VERSION "HINBNNNYNNNNNNNNNNNNNNNNNNNNNNNNNNNYYNNNNN/4>%%%/4/'%**4NNN///"

NS_ :

BS_:

BU_: Traffic Tester CGW ADU

BO_ 597 HMI_Request_ADU_CatS1: 32 ADU
 SG_ HMI_Request_ADU_CatS1_MACTx : 227|28@0+ (1,0) [0|268435455] ""  CGW
 SG_ HMI_Request_ADU_CatS1_FVTx : 231|4@0+ (1,0) [0|15] ""  CGW
 SG_ HMI_Request_ADU_CatS1_No_Cs : 223|8@0+ (1,0) [0|255] ""  CGW
 SG_ HMI_Request_ADU_CatS1_No_Cnt : 211|4@0+ (1,0) [0|15] ""  CGW
 SG_ HMI_Status_TSROffMute_Rq : 154|2@0+ (1,0) [0|0] ""  CGW
 SG_ HMI_Status_CBDA5_Rq : 155|1@0+ (1,0) [0|0] ""  CGW
 SG_ HMI_Status_CBDA4_Rq : 156|1@0+ (1,0) [0|0] ""  CGW
 SG_ HMI_Status_BSM6_Rq : 157|1@0+ (1,0) [0|0] ""  CGW
 SG_ HMI_Status_BSM5_Rq : 158|1@0+ (1,0) [0|0] ""  CGW
 SG_ HMI_Status_DAS2_Rq : 145|3@0+ (1,0) [0|0] ""  CGW
 SG_ HMI_Status_DAS1_Rq : 149|4@0+ (1,0) [0|0] ""  CGW
 SG_ HMI_Status_TSR3_Rq : 150|1@0+ (1,0) [0|0] ""  CGW
 SG_ HMI_Status_TSR2_Rq : 151|1@0+ (1,0) [0|0] ""  CGW
 SG_ HMI_Status_TSR1_Rq : 138|3@0+ (1,0) [0|0] ""  CGW
 SG_ HMI_Status_LKA10_Rq : 139|1@0+ (1,0) [0|0] ""  CGW
 SG_ HMI_Status_LKA9_Rq : 142|3@0+ (1,0) [0|0] ""  CGW
 SG_ HMI_Status_LKA8_Rq : 143|1@0+ (1,0) [0|0] ""  CGW
 SG_ HMI_Status_LKA7_Rq : 128|1@0+ (1,0) [0|0] ""  CGW
 SG_ HMI_Status_LKA6_Rq : 129|1@0+ (1,0) [0|0] ""  CGW
 SG_ HMI_Status_LKA5_Rq : 130|1@0+ (1,0) [0|0] ""  CGW
 SG_ HMI_Status_LKA4_Rq : 131|1@0+ (1,0) [0|0] ""  CGW
 SG_ HMI_Status_LKA3_Rq : 132|1@0+ (1,0) [0|0] ""  CGW
 SG_ HMI_Status_LKA2_Rq : 133|1@0+ (1,0) [0|0] ""  CGW
 SG_ HMI_Status_LKA1_Rq : 135|2@0+ (1,0) [0|0] ""  CGW
 SG_ HMI_Status_ACCASCISA2_Rq : 120|1@0+ (1,0) [0|0] ""  CGW
 SG_ HMI_Status_ACCASCISA1_Rq : 121|1@0+ (1,0) [0|0] ""  CGW
 SG_ HMI_Status_ACCASCISA_OVSP_Rq : 123|2@0+ (1,0) [0|0] ""  CGW
 SG_ HMI_Status_ISA2_Rq : 124|1@0+ (1,0) [0|0] ""  CGW
 SG_ HMI_Status_ISA1_Rq : 126|2@0+ (1,0) [0|0] ""  CGW
 SG_ HMI_Status_ACCASC4_Rq : 127|1@0+ (1,0) [0|0] ""  CGW
 SG_ HMI_Status_ACCASC3_Rq : 112|1@0+ (1,0) [0|0] ""  CGW
 SG_ HMI_Status_ACCASC2_Rq : 113|1@0+ (1,0) [0|0] ""  CGW
 SG_ HMI_Status_ACCASC1_Rq : 114|1@0+ (1,0) [0|0] ""  CGW
 SG_ HMI_Status_ASC3_Rq : 115|1@0+ (1,0) [0|0] ""  CGW
 SG_ HMI_Status_ASC2_Rq : 116|1@0+ (1,0) [0|0] ""  CGW
 SG_ HMI_Status_ASC1_Rq : 118|2@0+ (1,0) [0|0] ""  CGW
 SG_ HMI_Status_DAS3_Rq : 105|3@0+ (1,0) [0|0] ""  CGW
 SG_ HMI_Status_ACC12_Rq : 106|1@0+ (1,0) [0|0] ""  CGW
 SG_ HMI_Status_ACC11_Rq : 107|1@0+ (1,0) [0|0] ""  CGW
 SG_ HMI_Status_ACC10_Rq : 108|1@0+ (1,0) [0|0] ""  CGW
 SG_ HMI_Status_ACC9_Rq : 109|1@0+ (1,0) [0|0] ""  CGW
 SG_ HMI_Status_ACC8_Rq : 97|4@0+ (1,0) [0|0] ""  CGW
 SG_ HMI_Status_ACC7_Rq : 100|3@0+ (1,0) [0|0] ""  CGW
 SG_ HMI_Status_ACC6_Rq : 102|2@0+ (1,0) [0|0] ""  CGW
 SG_ HMI_Status_ACC5_Rq : 103|1@0+ (1,0) [0|0] ""  CGW
 SG_ HMI_Status_ACC4_Rq : 89|2@0+ (1,0) [0|0] ""  CGW
 SG_ HMI_Status_ACC3_Rq : 90|1@0+ (1,0) [0|0] ""  CGW
 SG_ HMI_Status_ACC2_Rq : 91|1@0+ (1,0) [0|0] ""  CGW
 SG_ HMI_Status_ACC1_Rq : 94|3@0+ (1,0) [0|0] ""  CGW
 SG_ HMI_Status_RCTA2_Rq : 95|1@0+ (1,0) [0|0] ""  CGW
 SG_ HMI_Status_RCTA1_Rq : 80|1@0+ (1,0) [0|0] ""  CGW
 SG_ HMI_Status_RPTB2_Rq : 81|1@0+ (1,0) [0|0] ""  CGW
 SG_ HMI_Status_RCTB1_Rq : 83|2@0+ (1,0) [0|0] ""  CGW
 SG_ HMI_Status_RPTC2_Rq : 84|1@0+ (1,0) [0|0] ""  CGW
 SG_ HMI_Status_RPTC1_Rq : 86|2@0+ (1,0) [0|0] ""  CGW
 SG_ HMI_Status_PAEB2_Rq : 87|1@0+ (1,0) [0|0] ""  CGW
 SG_ HMI_Status_PAEB1_Rq : 74|3@0+ (1,0) [0|0] ""  CGW
 SG_ HMI_Status_OCP8_Rq : 76|2@0+ (1,0) [0|0] ""  CGW
 SG_ HMI_Status_OCP7_Rq : 78|2@0+ (1,0) [0|0] ""  CGW
 SG_ HMI_Status_OCP6_Rq : 64|2@0+ (1,0) [0|0] ""  CGW
 SG_ HMI_Status_OCP5_Rq : 66|2@0+ (1,0) [0|0] ""  CGW
 SG_ HMI_Status_OCP4_Rq : 67|1@0+ (1,0) [0|0] ""  CGW
 SG_ HMI_Status_OCP3_Rq : 69|2@0+ (1,0) [0|0] ""  CGW
 SG_ HMI_Status_OCP2_Rq : 70|1@0+ (1,0) [0|0] ""  CGW
 SG_ HMI_Status_OCP1_Rq : 71|1@0+ (1,0) [0|0] ""  CGW
 SG_ HMI_Status_CBDA3_Rq : 57|2@0+ (1,0) [0|0] ""  CGW
 SG_ HMI_Status_CBDA2_Rq : 59|2@0+ (1,0) [0|0] ""  CGW
 SG_ HMI_Status_CBDA1_Rq : 60|1@0+ (1,0) [0|0] ""  CGW
 SG_ HMI_Status_BSM4_Rq : 62|2@0+ (1,0) [0|0] ""  CGW
 SG_ HMI_Status_BSM3_Rq : 48|2@0+ (1,0) [0|0] ""  CGW
 SG_ HMI_Status_BSM2_Rq : 49|1@0+ (1,0) [0|0] ""  CGW
 SG_ HMI_Status_BSM1_Rq : 50|1@0+ (1,0) [0|0] ""  CGW
 SG_ HMI_Status_BSP8_Rq : 52|2@0+ (1,0) [0|0] ""  CGW
 SG_ HMI_Status_BSP7_Rq : 54|2@0+ (1,0) [0|0] ""  CGW
 SG_ HMI_Status_BSP6_Rq : 40|2@0+ (1,0) [0|0] ""  CGW
 SG_ HMI_Status_BSP5_Rq : 42|2@0+ (1,0) [0|0] ""  CGW
 SG_ HMI_Status_BSP4_Rq : 43|1@0+ (1,0) [0|0] ""  CGW
 SG_ HMI_Status_BSP3_Rq : 45|2@0+ (1,0) [0|0] ""  CGW
 SG_ HMI_Status_BSP2_Rq : 46|1@0+ (1,0) [0|0] ""  CGW
 SG_ HMI_Status_BSP1_Rq : 47|1@0+ (1,0) [0|0] ""  CGW
 SG_ HMI_Status_RDPRDW4_Rq : 32|1@0+ (1,0) [0|0] ""  CGW
 SG_ HMI_Status_RDPRDW3_Rq : 34|2@0+ (1,0) [0|0] ""  CGW
 SG_ HMI_Status_RDPRDW2_Rq : 35|1@0+ (1,0) [0|0] ""  CGW
 SG_ HMI_Status_RDPRDW1_Rq : 36|1@0+ (1,0) [0|0] ""  CGW
 SG_ HMI_Status_LDW5_Rq : 38|2@0+ (1,0) [0|0] ""  CGW
 SG_ HMI_Status_LDW4_Rq : 24|2@0+ (1,0) [0|0] ""  CGW
 SG_ HMI_Status_LDW3_Rq : 25|1@0+ (1,0) [0|0] ""  CGW
 SG_ HMI_Status_LDW2_Rq : 26|1@0+ (1,0) [0|0] ""  CGW
 SG_ HMI_Status_LDW1_Rq : 27|1@0+ (1,0) [0|0] ""  CGW
 SG_ HMI_Status_LDP4_Rq : 29|2@0+ (1,0) [0|0] ""  CGW
 SG_ HMI_Status_LDP3_Rq : 31|2@0+ (1,0) [0|0] ""  CGW
 SG_ HMI_Status_LDP2_Rq : 16|1@0+ (1,0) [0|0] ""  CGW
 SG_ HMI_Status_LDP1_Rq : 18|2@0+ (1,0) [0|0] ""  CGW
 SG_ HMI_Status_FCTA4_Rq : 20|2@0+ (1,0) [0|0] ""  CGW
 SG_ HMI_Status_FCTA3_Rq : 22|2@0+ (1,0) [0|0] ""  CGW
 SG_ HMI_Status_FCTA2_Rq : 23|1@0+ (1,0) [0|0] ""  CGW
 SG_ HMI_Status_FCTA1_Rq : 8|1@0+ (1,0) [0|0] ""  CGW
 SG_ HMI_Status_CTB5_Rq : 10|2@0+ (1,0) [0|0] ""  CGW
 SG_ HMI_Status_CTB4_Rq : 12|2@0+ (1,0) [0|0] ""  CGW
 SG_ HMI_Status_CTB3_Rq : 13|1@0+ (1,0) [0|0] ""  CGW
 SG_ HMI_Status_CTB2_Rq : 14|1@0+ (1,0) [0|0] ""  CGW
 SG_ HMI_Status_CTB1_Rq : 0|2@0+ (1,0) [0|0] ""  CGW
 SG_ HMI_Status_PTC2_Rq : 1|1@0+ (1,0) [0|0] ""  CGW
 SG_ HMI_Status_PTC1_Rq : 3|2@0+ (1,0) [0|0] ""  CGW
 SG_ HMI_Status_AEBFCW2_Rq : 4|1@0+ (1,0) [0|0] ""  CGW
 SG_ HMI_Status_AEBFCW1_Rq : 7|3@0+ (1,0) [0|0] ""  CGW

BO_ 593 MAZPCM01: 32 CGW
 SG_ ID41B_No_Cs : 255|8@0+ (1,0) [0|255] ""  ADU
 SG_ AMBDS_ST : 183|1@0+ (1,0) [0|0] ""  ADU
 SG_ AMBDS_VL : 168|1@0+ (1,0) [0|0] ""  ADU
 SG_ AMBDS : 160|8@0+ (0.5,-40) [-40|60] "degC"  ADU
 SG_ AMBTE_ST : 161|1@0+ (1,0) [0|0] ""  ADU
 SG_ AMBTE_VL : 162|1@0+ (1,0) [0|0] ""  ADU
 SG_ AMBTE : 154|8@0+ (0.5,-40) [-40|60] "degC"  ADU
 SG_ RDYIND : 155|1@0+ (1,0) [0|1] ""  ADU
 SG_ GEAR_MET : 143|4@0+ (1,0) [0|0] ""  ADU
 SG_ THF : 132|1@0+ (1,0) [0|0] ""  ADU
 SG_ B_ISPTM : 135|3@0+ (1,0) [0|7] ""  ADU
 SG_ IGP_PT2 : 80|1@0+ (1,0) [0|0] ""  ADU
 SG_ B_B : 79|1@0+ (1,0) [0|0] ""  ADU
 SG_ B_LO : 64|1@0+ (1,0) [0|0] ""  ADU
 SG_ B_2 : 65|1@0+ (1,0) [0|0] ""  ADU
 SG_ B_3 : 66|1@0+ (1,0) [0|0] ""  ADU
 SG_ B_4 : 67|1@0+ (1,0) [0|0] ""  ADU
 SG_ B_D : 68|1@0+ (1,0) [0|0] ""  ADU
 SG_ B_N : 69|1@0+ (1,0) [0|0] ""  ADU
 SG_ B_R : 70|1@0+ (1,0) [0|0] ""  ADU
 SG_ B_P : 71|1@0+ (1,0) [0|0] ""  ADU
 SG_ ID251_No_Cs : 63|8@0+ (1,0) [0|255] ""  ADU
 SG_ PDLF : 6|1@0+ (1,0) [0|0] ""  ADU
 SG_ EGF : 7|1@0+ (1,0) [0|0] ""  ADU

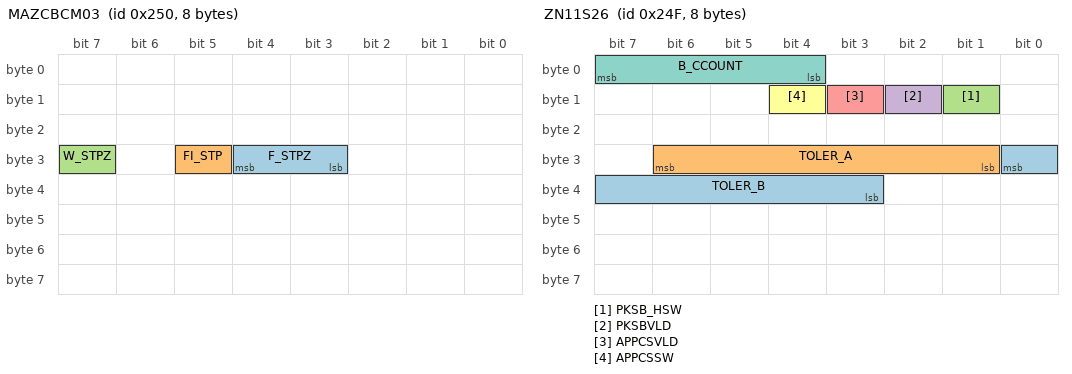
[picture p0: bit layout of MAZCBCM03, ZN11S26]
BO_ 592 MAZCBCM03: 8 CGW
 SG_ F_STPZ : 28|2@0+ (1,0) [0|3] ""  ADU
 SG_ FI_STP : 29|1@0+ (1,0) [0|1] ""  ADU
 SG_ W_STPZ : 31|1@0+ (1,0) [0|1] ""  ADU

BO_ 591 ZN11S26: 8 CGW
 SG_ TOLER_B : 24|6@0- (0.2,0) [-6.4|6.2] "km/h"  ADU
 SG_ TOLER_A : 30|6@0+ (0.002,0.94) [0.94|1.064] "Unitless"  ADU
 SG_ PKSB_HSW : 9|1@0+ (1,0) [0|0] ""  ADU
 SG_ PKSBVLD : 10|1@0+ (1,0) [0|0] ""  ADU
 SG_ APPCSVLD : 11|1@0+ (1,0) [0|0] ""  ADU
 SG_ APPCSSW : 12|1@0+ (1,0) [0|0] ""  ADU
 SG_ B_CCOUNT : 7|4@0+ (1,0) [0|15] ""  ADU

BO_ 590 MET1S44: 8 CGW
 SG_ KZK24E_MACTx : 35|28@0+ (1,0) [0|268435455] ""  ADU
 SG_ FV24E_FVTx : 39|4@0+ (1,0) [0|15] ""  ADU
 SG_ CCCOUNT : 27|4@0+ (1,0) [0|15] ""  ADU
 SG_ TSSMD2_M : 22|1@0+ (1,0) [0|0] ""  ADU
 SG_ TSSMD1_M : 23|1@0+ (1,0) [0|0] ""  ADU
 SG_ LTM_M : 8|1@0+ (1,0) [0|0] ""  ADU
 SG_ CANCEL_M : 9|1@0+ (1,0) [0|0] ""  ADU
 SG_ FLICK_PLUS_M : 10|1@0+ (1,0) [0|0] ""  ADU
 SG_ FLICK_MINUS_M : 11|1@0+ (1,0) [0|0] ""  ADU
 SG_ SET_PLUS_M : 12|1@0+ (1,0) [0|0] ""  ADU
 SG_ SET_MINUS_M : 13|1@0+ (1,0) [0|0] ""  ADU
 SG_ RES_M : 14|1@0+ (1,0) [0|0] ""  ADU
 SG_ TSSMD2 : 15|1@0+ (1,0) [0|0] ""  ADU
 SG_ TSSMD1 : 0|1@0+ (1,0) [0|0] ""  ADU
 SG_ LTM : 1|1@0+ (1,0) [0|0] ""  ADU
 SG_ CANCEL : 2|1@0+ (1,0) [0|0] ""  ADU
 SG_ FLICK_PLUS : 3|1@0+ (1,0) [0|0] ""  ADU
 SG_ FLICK_MINUS : 4|1@0+ (1,0) [0|0] ""  ADU
 SG_ SET_PLUS : 5|1@0+ (1,0) [0|0] ""  ADU
 SG_ SET_MINUS : 6|1@0+ (1,0) [0|0] ""  ADU
 SG_ RES : 7|1@0+ (1,0) [0|0] ""  ADU

BO_ 588 FCM1S78: 8 ADU
 SG_ OTHFRILL : 7|20@0+ (0.04,0) [0|41943] "cd/m^2"  CGW

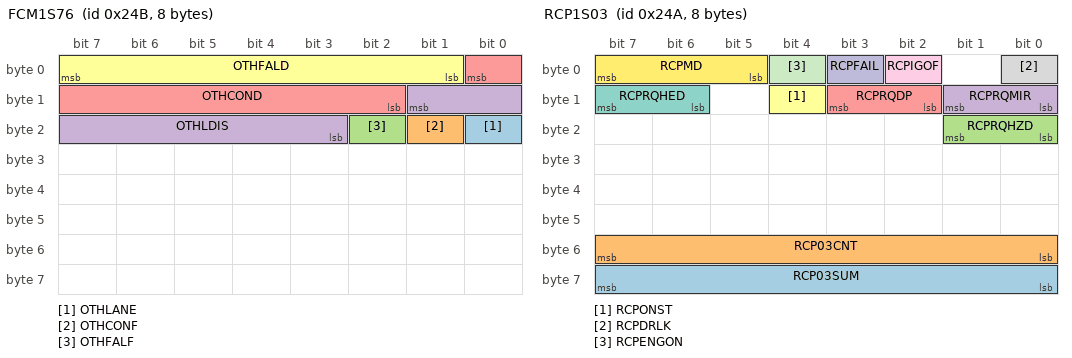
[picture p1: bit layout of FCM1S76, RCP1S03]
BO_ 587 FCM1S76: 8 ADU
 SG_ OTHLANE : 16|1@0+ (1,0) [0|1] ""  CGW
 SG_ OTHCONF : 17|1@0+ (1,0) [0|1] ""  CGW
 SG_ OTHFALF : 18|1@0+ (1,0) [0|1] ""  CGW
 SG_ OTHLDIS : 9|7@0+ (1,0) [0|127] "m"  CGW
 SG_ OTHCOND : 0|7@0+ (1,0) [0|127] "m"  CGW
 SG_ OTHFALD : 7|7@0+ (1,0) [0|127] "m"  CGW

BO_ 586 RCP1S03: 8 ADU
 SG_ RCP03SUM : 63|8@0+ (1,0) [0|255] ""  CGW
 SG_ RCP03CNT : 55|8@0+ (1,0) [0|255] "counter"  CGW
 SG_ RCPRQHZD : 17|2@0+ (1,0) [0|3] ""  CGW
 SG_ RCPRQMIR : 9|2@0+ (1,0) [0|3] ""  CGW
 SG_ RCPRQDP : 11|2@0+ (1,0) [0|3] ""  CGW
 SG_ RCPONST : 12|1@0+ (1,0) [0|1] ""  CGW
 SG_ RCPRQHED : 15|2@0+ (1,0) [0|3] ""  CGW
 SG_ RCPDRLK : 0|1@0+ (1,0) [0|1] ""  CGW
 SG_ RCPIGOF : 2|1@0+ (1,0) [0|1] ""  CGW
 SG_ RCPFAIL : 3|1@0+ (1,0) [0|1] ""  CGW
 SG_ RCPENGON : 4|1@0+ (1,0) [0|1] ""  CGW
 SG_ RCPMD : 7|3@0+ (1,0) [0|7] ""  CGW

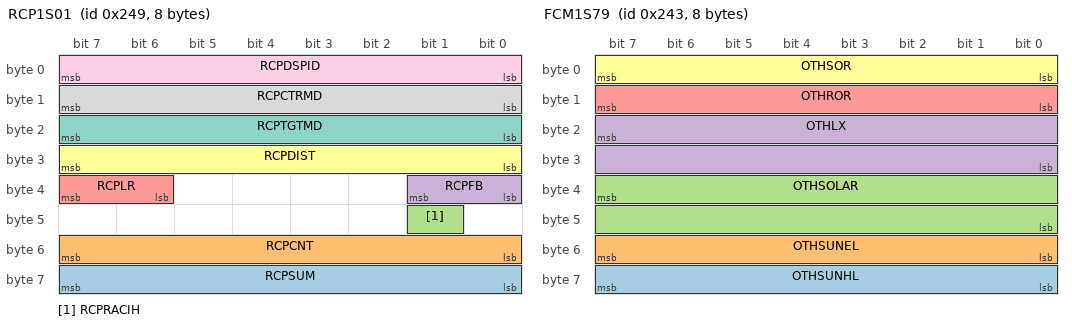
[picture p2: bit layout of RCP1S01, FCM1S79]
BO_ 585 RCP1S01: 8 ADU
 SG_ RCPSUM : 63|8@0+ (1,0) [0|255] ""  CGW
 SG_ RCPCNT : 55|8@0+ (1,0) [0|255] ""  CGW
 SG_ RCPRACIH : 41|1@0+ (1,0) [0|1] ""  CGW
 SG_ RCPFB : 33|2@0+ (1,0) [0|3] ""  CGW
 SG_ RCPLR : 39|2@0+ (1,0) [0|3] ""  CGW
 SG_ RCPDIST : 31|8@0+ (1,0) [0|255] "m"  CGW
 SG_ RCPTGTMD : 23|8@0+ (1,0) [0|255] ""  CGW
 SG_ RCPCTRMD : 15|8@0+ (1,0) [0|255] ""  CGW
 SG_ RCPDSPID : 7|8@0+ (1,0) [0|255] ""  CGW

BO_ 579 FCM1S79: 8 ADU
 SG_ OTHSUNHL : 63|8@0+ (1,0) [0|255] ""  CGW
 SG_ OTHSUNEL : 55|8@0+ (1,0) [0|255] ""  CGW
 SG_ OTHSOLAR : 39|16@0+ (1,0) [0|65535] ""  CGW
 SG_ OTHLX : 23|16@0+ (1,0) [0|65535] ""  CGW
 SG_ OTHROR : 15|8@0+ (1,0) [0|255] ""  CGW
 SG_ OTHSOR : 7|8@0+ (1,0) [0|255] ""  CGW

BO_ 552 TransGearData: 8 CGW
 SG_ ID228_No_Cs : 63|8@0+ (1,0) [0|255] "" Vector__XXX
 SG_ ID228_No_Cnt : 51|4@0+ (1,0) [0|15] "" Vector__XXX
 SG_ ShiftOpeWarning_D_Rq : 55|4@0+ (1,0) [0|0] "" Vector__XXX
 SG_ ShiftPos_D_Act : 43|4@0+ (1,0) [0|0] "" Vector__XXX
 SG_ TransmChangeLeverPosition : 47|4@0+ (1,0) [0|0] ""  ADU
 SG_ DispAtLvrPos_ArrowReq : 32|1@0+ (1,0) [0|0] "" Vector__XXX
 SG_ ShiftPos_D_Trg : 36|4@0+ (1,0) [0|0] "" Vector__XXX
 SG_ DispAtLvrPos_Off_Req : 37|1@0+ (1,0) [0|0] "" Vector__XXX
 SG_ AT_INDLvl_D_Rq : 39|2@0+ (1,0) [0|0] "" Vector__XXX
 SG_ AT_FailSafeLvl_D_Rq : 25|2@0+ (1,0) [0|0] "" Vector__XXX
 SG_ PwrDwn_D_Req_ByTCM : 27|2@0+ (1,0) [0|0] "" Vector__XXX
 SG_ SBW_INDLvl_D_Rq : 29|2@0+ (1,0) [0|0] "" Vector__XXX
 SG_ ParkLockWarning_D_Rq : 31|2@0+ (1,0) [0|0] "" Vector__XXX
 SG_ ShiftrPos_D_Qf : 17|2@0+ (1,0) [0|0] "" Vector__XXX
 SG_ SbwWarningLamp_B_Rq : 18|1@0+ (1,0) [0|0] "" Vector__XXX
 SG_ TransmParking_D_Act : 21|3@0+ (1,0) [0|0] "" Vector__XXX
 SG_ TrnSlaCtl_B_Rq : 22|1@0+ (1,0) [0|0] "" Vector__XXX
 SG_ TrnSlaCtlFlag : 23|1@0+ (1,0) [0|0] "" Vector__XXX
 SG_ TrnShifActv_B_Actl : 8|1@0+ (1,0) [0|0] "" Vector__XXX
 SG_ AT_OILTEMPHi_D_Rq : 10|2@0+ (1,0) [0|0] "" Vector__XXX
 SG_ TrnCnvtClu_D_Actl : 12|2@0+ (1,0) [0|0] "" Vector__XXX
 SG_ DispGearPos_FlashReq : 13|1@0+ (1,0) [0|0] "" Vector__XXX
 SG_ OD_Hold_Sport_Flash : 14|1@0+ (1,0) [0|0] "" Vector__XXX
 SG_ DispAtLvrPos_FlashReq : 15|1@0+ (1,0) [0|0] "" Vector__XXX
 SG_ DispAtLvrPos_D_Rq : 3|4@0+ (1,0) [0|0] "" Vector__XXX
 SG_ DispGearPos_D_Rq : 7|4@0+ (1,0) [0|0] "" Vector__XXX

BO_ 548 MAZDSC01: 32 CGW
 SG_ ID224_No_Cnt : 243|4@0+ (1,0) [0|15] ""  ADU
 SG_ SMVSCMZ01 : 62|8@0+ (1,0) [0|255] ""  ADU
 SG_ B_MCST : 48|2@0+ (1,0) [0|3] ""  ADU
 SG_ RJMALSSR : 49|1@0+ (1,0) [0|0] ""  ADU
 SG_ REJUFEXT : 50|1@0+ (1,0) [0|0] ""  ADU
 SG_ VXRLHDS : 51|1@0+ (1,0) [0|0] ""  ADU
 SG_ VXRRHDS : 52|1@0+ (1,0) [0|0] ""  ADU
 SG_ VXFLHDS : 53|1@0+ (1,0) [0|0] ""  ADU
 SG_ VXFRHDS : 54|1@0+ (1,0) [0|0] ""  ADU
 SG_ GVSPD : 38|16@0+ (0.01,0) [0|655.35] "km/h"  ADU
 SG_ SP1P : 28|6@0+ (1,0) [0|63] ""  ADU
 SG_ GVSPDINV : 29|1@0+ (1,0) [0|0] ""  ADU
 SG_ EPBDDACT : 30|1@0+ (1,0) [0|0] ""  ADU
 SG_ CWAACT : 17|1@0+ (1,0) [0|0] ""  ADU
 SG_ TRCOPE : 23|6@0+ (1,0) [0|63] ""  ADU
 SG_ MCBACT : 8|1@0+ (1,0) [0|0] ""  ADU
 SG_ VDMACT : 9|1@0+ (1,0) [0|0] ""  ADU
 SG_ ABSOPE : 14|5@0+ (1,0) [0|0] ""  ADU
 SG_ EPBF : 15|1@0+ (1,0) [0|0] ""  ADU
 SG_ APPSPCER : 1|2@0+ (1,0) [0|0] ""  ADU
 SG_ WSTP : 2|1@0+ (1,0) [0|0] ""  ADU
 SG_ FSTP : 3|1@0+ (1,0) [0|0] ""  ADU
 SG_ EPBSW : 5|2@0+ (1,0) [0|0] ""  ADU
 SG_ EPBLOCK : 7|2@0+ (1,0) [0|0] ""  ADU

BO_ 544 ABG1S09: 32 CGW
 SG_ SAB_ON : 153|2@0+ (1,0) [0|3] ""  ADU
 SG_ CSA_ON : 155|2@0+ (1,0) [0|3] ""  ADU
 SG_ FRAB_ON : 145|2@0+ (1,0) [0|3] ""  ADU

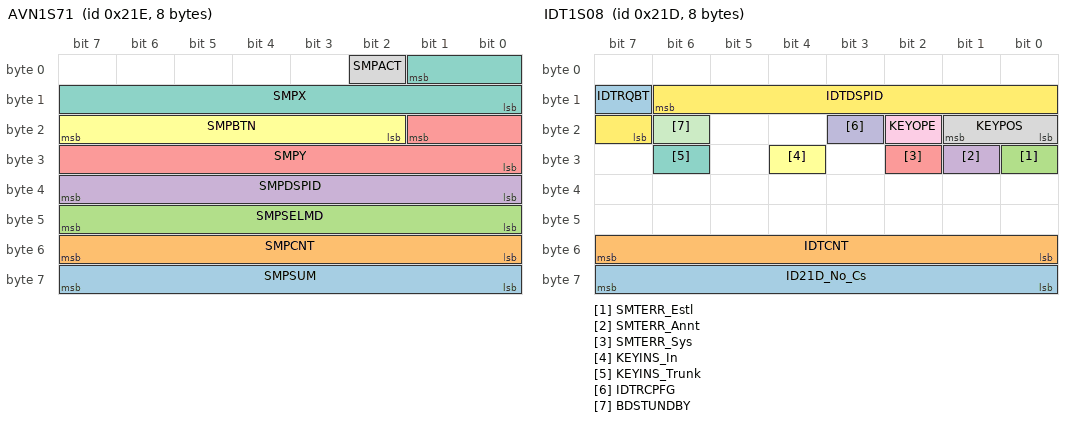
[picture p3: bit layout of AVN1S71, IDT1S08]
BO_ 542 AVN1S71: 8 CGW
 SG_ SMPSUM : 63|8@0+ (1,0) [0|255] ""  ADU
 SG_ SMPCNT : 55|8@0+ (1,0) [0|255] ""  ADU
 SG_ SMPSELMD : 47|8@0+ (1,0) [0|255] ""  ADU
 SG_ SMPDSPID : 39|8@0+ (1,0) [0|255] ""  ADU
 SG_ SMPY : 17|10@0+ (1,0) [0|1023] ""  ADU
 SG_ SMPBTN : 23|6@0+ (1,0) [0|63] ""  ADU
 SG_ SMPX : 1|10@0+ (1,0) [0|1023] ""  ADU
 SG_ SMPACT : 2|1@0+ (1,0) [0|1] ""  ADU

BO_ 541 IDT1S08: 8 CGW
 SG_ ID21D_No_Cs : 63|8@0+ (1,0) [0|255] ""  ADU
 SG_ IDTCNT : 55|8@0+ (1,0) [0|255] ""  ADU
 SG_ SMTERR_Estl : 24|1@0+ (1,0) [0|0] ""  ADU
 SG_ SMTERR_Annt : 25|1@0+ (1,0) [0|0] ""  ADU
 SG_ SMTERR_Sys : 26|1@0+ (1,0) [0|0] ""  ADU
 SG_ KEYINS_In : 28|1@0+ (1,0) [0|0] ""  ADU
 SG_ KEYINS_Trunk : 30|1@0+ (1,0) [0|0] ""  ADU
 SG_ KEYPOS : 17|2@0+ (1,0) [0|0] ""  ADU
 SG_ KEYOPE : 18|1@0+ (1,0) [0|0] ""  ADU
 SG_ IDTRCPFG : 19|1@0+ (1,0) [0|0] ""  ADU
 SG_ BDSTUNDBY : 22|1@0+ (1,0) [0|0] ""  ADU
 SG_ IDTDSPID : 14|8@0+ (1,0) [0|0] ""  ADU
 SG_ IDTRQBT : 15|1@0+ (1,0) [0|0] ""  ADU

BO_ 540 AVN1S73: 8 CGW
 SG_ Y2_COORD : 49|10@0+ (1,0) [0|1023] "pix"  ADU
 SG_ SW_AP : 51|1@0+ (1,0) [0|0] ""  ADU
 SG_ CD_SIZE : 55|4@0+ (1,0) [0|0] ""  ADU
 SG_ X2_COORD : 33|10@0+ (1,0) [0|1023] "pix"  ADU
 SG_ MIC_POS : 36|3@0+ (1,0) [0|0] ""  ADU
 SG_ VR_STATE : 39|3@0+ (1,0) [0|0] ""  ADU
 SG_ Y_COORD : 17|10@0+ (1,0) [0|1023] "pix"  ADU
 SG_ CUST_APP : 19|1@0+ (1,0) [0|0] ""  ADU
 SG_ CUST_TRA : 20|1@0+ (1,0) [0|0] ""  ADU
 SG_ SW_PVM : 21|1@0+ (1,0) [0|0] ""  ADU
 SG_ MMD_MODE : 22|1@0+ (1,0) [0|0] ""  ADU
 SG_ DN_DISP : 23|1@0+ (1,0) [0|0] ""  ADU
 SG_ X_COORD : 1|10@0+ (1,0) [0|1023] "pix"  ADU
 SG_ MM_RESET : 2|1@0+ (1,0) [0|0] ""  ADU
 SG_ DI_MODE : 3|1@0+ (1,0) [0|0] ""  ADU
 SG_ CMD_MODE : 4|1@0+ (1,0) [0|0] ""  ADU
 SG_ IRQ_MM : 5|1@0+ (1,0) [0|0] ""  ADU
 SG_ CC_MODE : 6|1@0+ (1,0) [0|0] ""  ADU
 SG_ AVN_ON : 7|1@0+ (1,0) [0|0] ""  ADU

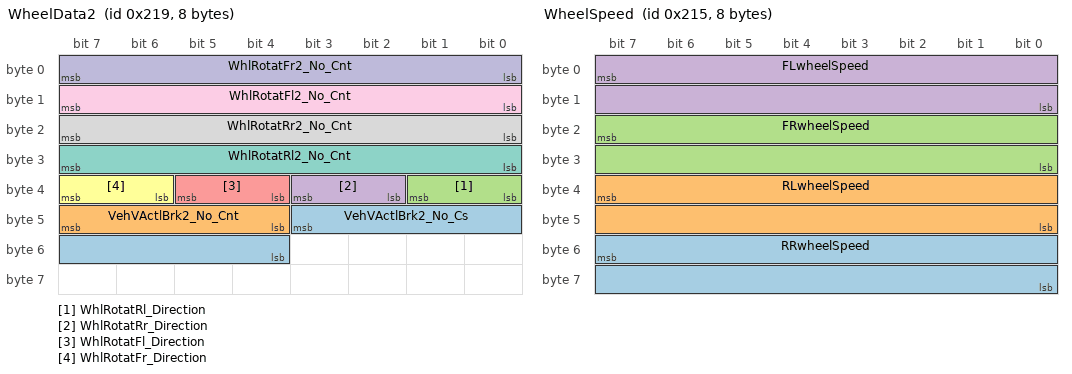
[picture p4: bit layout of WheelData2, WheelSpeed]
BO_ 537 WheelData2: 8 CGW
 SG_ VehVActlBrk2_No_Cs : 43|8@0+ (1,0) [0|255] ""  ADU
 SG_ VehVActlBrk2_No_Cnt : 47|4@0+ (1,0) [0|15] ""  ADU
 SG_ WhlRotatRl_Direction : 33|2@0+ (1,0) [0|0] ""  ADU
 SG_ WhlRotatRr_Direction : 35|2@0+ (1,0) [0|0] ""  ADU
 SG_ WhlRotatFl_Direction : 37|2@0+ (1,0) [0|0] ""  ADU
 SG_ WhlRotatFr_Direction : 39|2@0+ (1,0) [0|0] ""  ADU
 SG_ WhlRotatRl2_No_Cnt : 31|8@0+ (1,0) [0|255] ""  ADU
 SG_ WhlRotatRr2_No_Cnt : 23|8@0+ (1,0) [0|255] ""  ADU
 SG_ WhlRotatFl2_No_Cnt : 15|8@0+ (1,0) [0|255] ""  ADU
 SG_ WhlRotatFr2_No_Cnt : 7|8@0+ (1,0) [0|255] ""  ADU

BO_ 533 WheelSpeed: 8 CGW
 SG_ RRwheelSpeed : 55|16@0+ (0.01,-100) [-100|300] "km/h"  ADU
 SG_ RLwheelSpeed : 39|16@0+ (0.01,-100) [-100|300] "km/h"  ADU
 SG_ FRwheelSpeed : 23|16@0+ (0.01,-100) [-100|300] "km/h"  ADU
 SG_ FLwheelSpeed : 7|16@0+ (0.01,-100) [-100|300] "km/h"  ADU

BO_ 526 VSC1G35: 8 CGW
 SG_ ID20E_No_Cs : 63|8@0+ (1,0) [0|255] ""  ADU
 SG_ DAMODE : 50|3@0+ (1,0) [0|0] ""  ADU
 SG_ BRKON : 51|1@0+ (1,0) [0|0] ""  ADU
 SG_ BRKSBFC : 53|2@0+ (1,0) [0|0] ""  ADU
 SG_ BRKMNFC : 55|2@0+ (1,0) [0|0] ""  ADU
 SG_ SFTFC : 41|2@0+ (1,0) [0|0] ""  ADU
 SG_ DRVFC : 43|2@0+ (1,0) [0|0] ""  ADU
 SG_ VMCLGFC : 45|2@0+ (1,0) [0|0] ""  ADU
 SG_ EPBFC : 47|2@0+ (1,0) [0|0] ""  ADU
 SG_ DAFAIL : 34|1@0+ (1,0) [0|0] ""  ADU
 SG_ DASTBHAL : 35|1@0+ (1,0) [0|0] ""  ADU
 SG_ HLDSTB : 36|1@0+ (1,0) [0|0] ""  ADU
 SG_ CCS : 39|1@0+ (1,0) [0|0] ""  ADU
 SG_ FBKRLY : 24|1@0+ (1,0) [0|0] ""  ADU
 SG_ TSVSC : 26|1@0+ (1,0) [0|0] ""  ADU
 SG_ DBRKINFC : 28|2@0+ (1,0) [0|0] ""  ADU
 SG_ BRKHT : 29|1@0+ (1,0) [0|0] ""  ADU
 SG_ XGVCINV : 30|1@0+ (1,0) [0|0] ""  ADU
 SG_ SPDLMTD : 31|1@0+ (1,0) [0|0] ""  ADU
 SG_ SPDLMT : 23|8@0+ (1,0) [0|255] "km/h"  ADU
 SG_ GVC : 7|16@0- (0.001,0) [-32.768|32.767] "m/s^2"  ADU

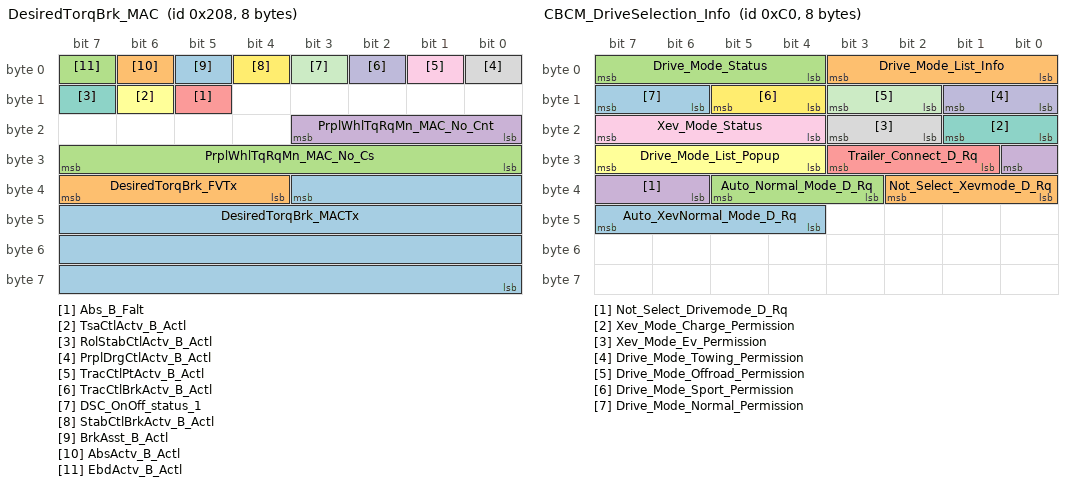
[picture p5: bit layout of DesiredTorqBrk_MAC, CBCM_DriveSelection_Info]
BO_ 520 DesiredTorqBrk_MAC: 8 CGW
 SG_ DesiredTorqBrk_MACTx : 35|28@0+ (1,0) [0|268435455] ""  ADU
 SG_ DesiredTorqBrk_FVTx : 39|4@0+ (1,0) [0|15] ""  ADU
 SG_ PrplWhlTqRqMn_MAC_No_Cs : 31|8@0+ (1,0) [0|255] "" Vector__XXX
 SG_ PrplWhlTqRqMn_MAC_No_Cnt : 19|4@0+ (1,0) [0|15] "" Vector__XXX
 SG_ Abs_B_Falt : 13|1@0+ (1,0) [0|0] ""  ADU
 SG_ TsaCtlActv_B_Actl : 14|1@0+ (1,0) [0|0] ""  ADU
 SG_ RolStabCtlActv_B_Actl : 15|1@0+ (1,0) [0|0] "" Vector__XXX
 SG_ PrplDrgCtlActv_B_Actl : 0|1@0+ (1,0) [0|0] "" Vector__XXX
 SG_ TracCtlPtActv_B_Actl : 1|1@0+ (1,0) [0|0] "" Vector__XXX
 SG_ TracCtlBrkActv_B_Actl : 2|1@0+ (1,0) [0|0] "" Vector__XXX
 SG_ DSC_OnOff_status_1 : 3|1@0+ (1,0) [0|0] "" Vector__XXX
 SG_ StabCtlBrkActv_B_Actl : 4|1@0+ (1,0) [0|0] ""  ADU
 SG_ BrkAsst_B_Actl : 5|1@0+ (1,0) [0|0] ""  ADU
 SG_ AbsActv_B_Actl : 6|1@0+ (1,0) [0|0] "" Vector__XXX
 SG_ EbdActv_B_Actl : 7|1@0+ (1,0) [0|0] "" Vector__XXX

BO_ 508 VSC1G30: 32 CGW
 SG_ KZK1FC_MACTx : 227|28@0+ (1,0) [0|268435455] ""  ADU
 SG_ FV1FC_FVTx : 231|4@0+ (1,0) [0|15] ""  ADU
 SG_ FBKDR_AX : 212|13@0- (0.01,0) [-40.96|40.95] "m/s^2"  ADU
 SG_ PBALEVEL : 215|3@0+ (1,0) [0|0] ""  ADU
 SG_ FAPDL_AX : 199|16@0- (0.001,0) [-32.768|32.767] "m/s^2"  ADU
 SG_ AVLH_GAX : 183|16@0- (0.001,0) [-32.768|32.767] "m/s^2"  ADU
 SG_ AVLL_GAX : 167|16@0- (0.001,0) [-32.768|32.767] "m/s^2"  ADU
 SG_ FDRV_GAX : 151|16@0- (0.001,0) [-32.768|32.767] "m/s^2"  ADU
 SG_ VMC_STR : 135|16@0- (0.001,0) [-32.768|32.767] "rad"  ADU
 SG_ PECO_ACC : 119|16@0- (0.001,0) [-32.768|32.767] "m/s^2"  ADU
 SG_ VMC_LTID : 109|6@0+ (1,0) [0|0] ""  ADU
 SG_ LTCLFC : 111|2@0+ (1,0) [0|0] ""  ADU
 SG_ SSMST : 101|2@0+ (1,0) [0|0] ""  ADU
 SG_ BDLCVRCP : 89|2@0+ (1,0) [0|0] ""  ADU
 SG_ BDLCFRCP : 91|1@0+ (1,0) [0|0] ""  ADU
 SG_ ADSBKINV : 92|1@0+ (1,0) [0|0] ""  ADU
 SG_ PCSBKLE : 95|1@0+ (1,0) [0|0] ""  ADU
 SG_ SSBKST : 81|2@0+ (1,0) [0|0] ""  ADU
 SG_ SSMFC : 83|2@0+ (1,0) [0|0] ""  ADU
 SG_ PCSGUARD : 87|1@0+ (1,0) [0|0] ""  ADU
 SG_ GECO_ACC : 71|16@0- (0.001,0) [-32.768|32.767] "m/s^2"  ADU
 SG_ VMC_LGID : 53|6@0+ (1,0) [0|0] ""  ADU
 SG_ ACCBKLE : 54|1@0+ (1,0) [0|0] ""  ADU
 SG_ XSTOP : 55|1@0+ (1,0) [0|0] ""  ADU
 SG_ VMC_ACC : 39|16@0- (0.001,0) [-32.768|32.767] "m/s^2"  ADU
 SG_ VMCLGIDP : 29|6@0+ (1,0) [0|0] ""  ADU
 SG_ VMACSYS : 30|1@0+ (1,0) [0|0] ""  ADU
 SG_ VMCLGIDB : 21|6@0+ (1,0) [0|0] ""  ADU
 SG_ VMCINTMT : 22|1@0+ (1,0) [0|0] ""  ADU
 SG_ DRVBKOP : 23|1@0+ (1,0) [0|0] ""  ADU
 SG_ TBKCR_AX : 4|13@0- (0.01,0) [-40.96|40.95] "m/s^2"  ADU
 SG_ TBKCSYS2 : 5|1@0+ (1,0) [0|0] ""  ADU
 SG_ FBKDRSYS : 6|1@0+ (1,0) [0|0] ""  ADU
 SG_ RCONFLG : 7|1@0+ (1,0) [0|0] ""  ADU

BO_ 505 ENG1G40: 32 CGW
 SG_ EDRENG04 : 80|8@0+ (1,0) [0|255] ""  ADU
 SG_ EDRENG03 : 72|8@0+ (1,0) [0|255] ""  ADU
 SG_ EDRENG02 : 64|8@0+ (1,0) [0|255] ""  ADU
 SG_ EDRENG01 : 56|8@0+ (1,0) [0|255] ""  ADU
 SG_ WSTL2 : 57|1@0+ (1,0) [0|0] ""  ADU
 SG_ WSTL2_F : 59|2@0+ (1,0) [0|0] ""  ADU
 SG_ Y_TGTIDL : 49|6@0+ (1,0) [0|0] ""  ADU
 SG_ Y_FSIDL : 41|8@0+ (1,0) [0|0] ""  ADU
 SG_ B_PDLF : 42|1@0+ (1,0) [0|0] ""  ADU
 SG_ EACCP : 34|8@0+ (0.5,0) [0|100] "%"  ADU
 SG_ IGP_PT1 : 35|1@0+ (1,0) [0|0] ""  ADU
 SG_ NE1 : 19|16@0+ (0.78125,0) [0|12799.21875] "rpm"  ADU
 SG_ PTCURSFT : 8|5@0+ (1,0) [0|0] ""  ADU
 SG_ KDNSW : 9|1@0+ (1,0) [0|0] ""  ADU
 SG_ XPAIDLV : 10|1@0+ (1,0) [0|0] ""  ADU
 SG_ XPAIDL : 11|1@0+ (1,0) [0|0] ""  ADU
 SG_ CRUCAN : 14|3@0+ (1,0) [0|0] ""  ADU
 SG_ DGTMD : 15|1@0+ (1,0) [0|0] ""  ADU

BO_ 357 EngControlData: 32 CGW
 SG_ HeaterCntVlv_State : 189|3@0+ (1,0) [0|0] "" Vector__XXX
 SG_ FuelLid_UnLock_B_Req : 191|2@0+ (1,0) [0|0] "" Vector__XXX
 SG_ EngCltFlow_Cnt_Vlv : 183|8@0+ (1,-15) [-15|134] "deg" Vector__XXX
 SG_ CylState : 174|7@0+ (1,0) [0|127] "" Vector__XXX
 SG_ TrnAinTq_D_Qf1 : 144|2@0+ (1,0) [0|0] "" Vector__XXX
 SG_ TrnAin_Tq_Actl1 : 139|11@0+ (1,-500) [-500|1547] "NM" Vector__XXX
 SG_ HeaterCoreEst_Te_Actl : 132|8@0+ (1,-40) [-40|214] "degC" Vector__XXX
 SG_ HeaterCoreTeEst_D_Qf : 134|2@0+ (1,0) [0|0] "" Vector__XXX
 SG_ ClosedFuelTankSystem_PCM : 135|1@0+ (1,0) [0|0] "" Vector__XXX
 SG_ ID202_E2E_CRCProfile1 : 127|8@0+ (1,0) [0|255] "" Vector__XXX
 SG_ ApedPosPcActl_D_Qf : 116|2@0+ (1,0) [0|0] ""  ADU
 SG_ ID202_E2E_CNTProfile1 : 107|4@0+ (1,0) [0|14] "" Vector__XXX
 SG_ DcdcWarningDisp_B_Rq_202 : 109|1@0+ (1,0) [0|0] "" Vector__XXX
 SG_ ApedPos_Pc_ActlArb : 103|10@0+ (0.1,0) [0|102.3] "%"  ADU
 SG_ EngAout_N_ReqTacho : 84|13@0+ (2,0) [0|16380] "rpm" Vector__XXX
 SG_ EngAout_D_ReqTachoGain : 86|2@0+ (1,0) [0|0] "" Vector__XXX
 SG_ EngAout_N_Actl : 71|13@0+ (2,0) [0|16380] "rpm"  ADU
 SG_ TrnTotTq_Rt_Est : 55|16@0+ (0.001,0) [0|65.533] "" Vector__XXX
 SG_ VehVLim_Warning : 41|1@0+ (1,0) [0|0] "" Vector__XXX
 SG_ AirCondRec_B_Rq : 42|1@0+ (1,0) [0|0] "" Vector__XXX
 SG_ AWD_State_Req_165 : 32|4@0+ (1,0) [0|0] "" Vector__XXX
 SG_ VehVLim_OverVS_KD : 33|1@0+ (1,0) [0|0] "" Vector__XXX
 SG_ NeutralSwActv_D_Actl : 36|2@0+ (1,0) [0|0] "" Vector__XXX
 SG_ GearPos_D_TrgMt : 24|4@0+ (1,0) [0|0] "" Vector__XXX
 SG_ GearRvrseActv_B_Actl : 25|1@0+ (1,0) [0|0] ""  ADU
 SG_ BrakeSw_Fail_Warning2 : 27|1@0+ (1,0) [0|0] ""  ADU
 SG_ EngAoutIdl_N_RqVsc : 22|11@0+ (2,0) [0|4094] "rpm" Vector__XXX
 SG_ BrkOnOffSwtch_D_Actl_2 : 8|2@0+ (1,0) [0|0] ""  ADU
 SG_ AWDTrgt_I_Req_165 : 7|12@0+ (0.015,0) [0|6] "A" Vector__XXX

BO_ 253 ECM_Status: 32 CGW
 SG_ ID0B0_No_Cs : 191|8@0+ (1,0) [0|255] "" Vector__XXX
 SG_ ID0B0_No_Cnt : 179|4@0+ (1,0) [0|15] "" Vector__XXX
 SG_ HEVIG_B_Actl : 162|1@0+ (1,0) [0|0] "" Vector__XXX
 SG_ IG_OnOff_PT : 163|1@0+ (1,0) [0|0] "" Vector__XXX
 SG_ RexRelay_Req : 164|1@0+ (1,0) [0|0] "" Vector__XXX
 SG_ EngCrank_Req : 165|1@0+ (1,0) [0|0] "" Vector__XXX
 SG_ ChgHiVoltCont_Req : 166|1@0+ (1,0) [0|0] "" Vector__XXX
 SG_ HiVoltCont_Req : 167|1@0+ (1,0) [0|0] "" Vector__XXX
 SG_ CDTHVANS : 152|1@0+ (1,0) [0|0] "" Vector__XXX
 SG_ Permit_Isolate_Detect : 153|1@0+ (1,0) [0|0] "" Vector__XXX
 SG_ Chrg_Enable : 154|1@0+ (1,0) [0|0] "" Vector__XXX
 SG_ Eng_Enable : 155|1@0+ (1,0) [0|0] "" Vector__XXX
 SG_ HiVolt_Enable : 156|1@0+ (1,0) [0|0] "" Vector__XXX
 SG_ CellBalance_Req : 157|1@0+ (1,0) [0|0] "" Vector__XXX
 SG_ CoastDownMode : 158|1@0+ (1,0) [0|0] "" Vector__XXX
 SG_ Discharge_Req : 159|1@0+ (1,0) [0|0] "" Vector__XXX
 SG_ BatteryHeater_On_Sig : 147|1@0+ (1,0) [0|0] "" Vector__XXX
 SG_ AirConditioner_On_Sig : 148|1@0+ (1,0) [0|0] "" Vector__XXX
 SG_ Supply_On_Sig : 149|1@0+ (1,0) [0|0] "" Vector__XXX
 SG_ Charge_On_Sig : 150|1@0+ (1,0) [0|0] "" Vector__XXX
 SG_ Ready_On_Sig : 151|1@0+ (1,0) [0|0] "" Vector__XXX
 SG_ GenStartStop_Req : 138|1@0+ (1,0) [0|0] "" Vector__XXX
 SG_ SupStartStop_Req : 139|1@0+ (1,0) [0|0] "" Vector__XXX
 SG_ ChgStartStop_Req : 140|1@0+ (1,0) [0|0] "" Vector__XXX
 SG_ DrvStartStop_Req : 141|1@0+ (1,0) [0|0] "" Vector__XXX
 SG_ EatcStartStop_Req : 142|1@0+ (1,0) [0|0] "" Vector__XXX
 SG_ EcuStartStop_Req : 143|1@0+ (1,0) [0|0] "" Vector__XXX
 SG_ Veh_State_Sig : 131|4@0+ (1,0) [0|0] "" Vector__XXX
 SG_ Veh_Mode_Sig : 135|4@0+ (1,0) [0|0] "" Vector__XXX
 SG_ Clutch_Stroke : 127|8@0+ (0.5,0) [0|100] "%" Vector__XXX
 SG_ CidSwStat_iStpCancel_ONOFF_GUI : 111|2@0+ (1,0) [0|0] "" Vector__XXX
 SG_ PTiStpRdy_B_Actl : 96|1@0+ (1,0) [0|0] "" Vector__XXX
 SG_ iStpDenyBrk_B_Actl : 97|1@0+ (1,0) [0|0] "" Vector__XXX
 SG_ iStpDenyPwStr_B_Actl : 98|1@0+ (1,0) [0|0] "" Vector__XXX
 SG_ iStpKeySta_B_Actl : 99|1@0+ (1,0) [0|0] "" Vector__XXX
 SG_ iStpDenyAC_B_Actl : 100|1@0+ (1,0) [0|0] "" Vector__XXX
 SG_ iStpDenyNrange_B_Actl : 101|1@0+ (1,0) [0|0] "" Vector__XXX
 SG_ iStpDenyDPF_B_Actl : 102|1@0+ (1,0) [0|0] "" Vector__XXX
 SG_ CidSwStat_iStpCancel_ONOFF : 88|2@0+ (1,0) [0|0] "" Vector__XXX
 SG_ ELM_IRCutReq : 89|1@0+ (1,0) [0|0] "" Vector__XXX
 SG_ BatteryWeakenFlag : 90|1@0+ (1,0) [0|0] "" Vector__XXX
 SG_ iStpDoorOpen_B_Actl : 91|1@0+ (1,0) [0|0] "" Vector__XXX
 SG_ SISS_EngineState : 95|4@0+ (1,0) [0|0] ""  ADU
 SG_ SISS_IRCutReq : 80|1@0+ (1,0) [0|0] "" Vector__XXX
 SG_ SKE_Control : 82|2@0+ (1,0) [0|0] "" Vector__XXX
 SG_ SISS_Mode_for_SKE : 83|1@0+ (1,0) [0|0] "" Vector__XXX
 SG_ iStpReady_Rq : 84|1@0+ (1,0) [0|0] "" Vector__XXX
 SG_ iStpDenyBatt_B_Actl : 85|1@0+ (1,0) [0|0] "" Vector__XXX
 SG_ SlaCtl_B_Rq : 86|1@0+ (1,0) [0|0] "" Vector__XXX
 SG_ SISS_WarningLamp_R : 73|3@0+ (1,0) [0|0] "" Vector__XXX
 SG_ SISS_WarningLamp_G : 76|3@0+ (1,0) [0|0] "" Vector__XXX
 SG_ SISS_AlarmBuzzer : 79|3@0+ (1,0) [0|0] "" Vector__XXX
 SG_ SISSStatus : 64|1@0+ (1,0) [0|0] "" Vector__XXX
 SG_ SrlyUpper_Connect_Rq : 66|2@0+ (1,0) [0|0] "" Vector__XXX
 SG_ PlaCtl_B_Rq : 67|1@0+ (1,0) [0|0] "" Vector__XXX
 SG_ Xev_Charge_Req_PCM : 58|3@0+ (1,0) [0|0] "" Vector__XXX
 SG_ PTGeneralWarn_Mirror : 59|1@0+ (1,0) [0|0] "" Vector__XXX
 SG_ Drive_Mode_Req_PCM : 63|4@0+ (1,0) [0|0] "" Vector__XXX
 SG_ Drive_Mode_Towing_Req_PCM : 49|2@0+ (1,0) [0|0] "" Vector__XXX
 SG_ Drive_Mode_OffRoad_Req_PCM : 51|2@0+ (1,0) [0|0] "" Vector__XXX
 SG_ Drive_Mode_Sport_Req_PCM : 53|2@0+ (1,0) [0|0] "" Vector__XXX
 SG_ Drive_Mode_Normal_Req_PCM : 55|2@0+ (1,0) [0|0] "" Vector__XXX
 SG_ ATFalseStartWarning : 40|1@0+ (1,0) [0|0] "" Vector__XXX
 SG_ BattRgenStat_B_Actl : 41|1@0+ (1,0) [0|0] "" Vector__XXX
 SG_ RegenBrkFailWarning : 42|1@0+ (1,0) [0|0] "" Vector__XXX
 SG_ BmsWarn_B_Rq : 43|1@0+ (1,0) [0|0] "" Vector__XXX
 SG_ SmtAclInh_B_Actl : 44|1@0+ (1,0) [0|0] "" Vector__XXX
 SG_ BrakeSw_Fail_Warning : 45|1@0+ (1,0) [0|0] "" Vector__XXX
 SG_ BOS_Active_B_Actl : 46|1@0+ (1,0) [0|0] ""  ADU
 SG_ DriveMode_Hold_Rq_PCM : 47|1@0+ (1,0) [0|0] "" Vector__XXX
 SG_ GlobalConfgWarn_B_Rq : 32|1@0+ (1,0) [0|0] "" Vector__XXX
 SG_ CrankingTime : 37|5@0+ (1,0) [2|31] "sec" Vector__XXX
 SG_ ApedOnN_B_Rq : 38|1@0+ (1,0) [0|0] "" Vector__XXX
 SG_ IG_OFF_Delay_Request : 39|1@0+ (1,0) [0|0] "" Vector__XXX
 SG_ Crank_wait : 31|8@0+ (1,0) [0|0] "" Vector__XXX
 SG_ SilGearPosActl_D_Dsply : 19|4@0+ (1,0) [0|0] "" Vector__XXX
 SG_ Xev_Ev_Req_PCM : 22|3@0+ (1,0) [0|0] "" Vector__XXX
 SG_ VspLmtAlarm_B_Rq : 23|1@0+ (1,0) [0|0] "" Vector__XXX
 SG_ PTGeneralWarn_B_Rq : 8|1@0+ (1,0) [0|0] "" Vector__XXX
 SG_ SRLY_state : 9|1@0+ (1,0) [0|0] "" Vector__XXX
 SG_ SilGearPos_D_Dsply : 13|4@0+ (1,0) [0|0] "" Vector__XXX
 SG_ VspLmtWarn_B_Rq : 15|2@0+ (1,0) [0|0] "" Vector__XXX
 SG_ KeyState : 2|3@0+ (1,0) [0|0] "" Vector__XXX
 SG_ ShiftIndicatorLight : 4|2@0+ (1,0) [0|0] "" Vector__XXX
 SG_ PowerSourceStatus : 7|3@0+ (1,0) [0|0] ""  ADU

BO_ 218 ENG1S62: 32 CGW
 SG_ ID0DA_No_Cs : 255|8@0+ (1,0) [0|255] ""  ADU
 SG_ BKSBWCF : 80|1@0+ (1,0) [0|0] ""  ADU
 SG_ SBWSYSOR : 81|1@0+ (1,0) [0|0] ""  ADU
 SG_ DORRQSFT : 85|4@0+ (1,0) [0|0] ""  ADU
 SG_ SBWPROK : 86|1@0+ (1,0) [0|0] ""  ADU
 SG_ SBWPRTNG : 87|1@0+ (1,0) [0|0] ""  ADU
 SG_ FAVLLAPP : 71|16@0+ (1,0) [0|65535] "Nm"  ADU
 SG_ STSPTAPP : 50|3@0+ (1,0) [0|0] ""  ADU
 SG_ ATBRKOK : 51|1@0+ (1,0) [0|0] ""  ADU
 SG_ SOCLOWID : 55|3@0+ (1,0) [0|0] ""  ADU
 SG_ FDRVRAPP : 39|16@0+ (1,0) [0|65535] "Nm"  ADU
 SG_ FAVLLPRE : 23|16@0+ (1,0) [0|65535] "Nm"  ADU
 SG_ FAVLHAPP : 7|16@0+ (1,0) [0|65535] "Nm"  ADU

BO_ 192 CBCM_DriveSelection_Info: 8 CGW
 SG_ Auto_XevNormal_Mode_D_Rq : 47|4@0+ (1,0) [0|0] "" Vector__XXX
 SG_ Not_Select_Xevmode_D_Rq : 34|3@0+ (1,0) [0|0] "" Vector__XXX
 SG_ Auto_Normal_Mode_D_Rq : 37|3@0+ (1,0) [0|0] "" Vector__XXX
 SG_ Not_Select_Drivemode_D_Rq : 24|3@0+ (1,0) [0|0] "" Vector__XXX
 SG_ Trailer_Connect_D_Rq : 27|3@0+ (1,0) [0|0] "" Vector__XXX
 SG_ Drive_Mode_List_Popup : 31|4@0+ (1,0) [0|0] "" Vector__XXX
 SG_ Xev_Mode_Charge_Permission : 17|2@0+ (1,0) [0|0] "" Vector__XXX
 SG_ Xev_Mode_Ev_Permission : 19|2@0+ (1,0) [0|0] "" Vector__XXX
 SG_ Xev_Mode_Status : 23|4@0+ (1,0) [0|0] "" Vector__XXX
 SG_ Drive_Mode_Towing_Permission : 9|2@0+ (1,0) [0|0] "" Vector__XXX
 SG_ Drive_Mode_Offroad_Permission : 11|2@0+ (1,0) [0|0] "" Vector__XXX
 SG_ Drive_Mode_Sport_Permission : 13|2@0+ (1,0) [0|0] "" Vector__XXX
 SG_ Drive_Mode_Normal_Permission : 15|2@0+ (1,0) [0|0] "" Vector__XXX
 SG_ Drive_Mode_List_Info : 3|4@0+ (1,0) [0|0] "" Vector__XXX
 SG_ Drive_Mode_Status : 7|4@0+ (1,0) [0|0] ""  ADU

BO_ 159 CBCM_IllumStatus: 8 CGW
 SG_ BpedDrvAppl_D_Actl : 59|2@0+ (1,0) [0|0] ""  ADU
 SG_ IndirectIllumination_D_Rq : 63|3@0+ (1,0) [0|0] "" Vector__XXX
 SG_ WelcomIllumination_D_Rq : 49|2@0+ (1,0) [0|0] "" Vector__XXX
 SG_ FootLamp_D_Rq : 52|3@0+ (1,0) [0|0] "" Vector__XXX
 SG_ DoorCourtesyLamp_D_Rq : 54|2@0+ (1,0) [0|0] "" Vector__XXX
 SG_ CargoLamp_D_Rq : 40|2@0+ (1,0) [0|0] "" Vector__XXX
 SG_ CBCM_Control_No_Cnt : 44|4@0+ (1,0) [0|15] "" Vector__XXX
 SG_ DimmerCancel : 46|2@0+ (1,0) [0|0] "" Vector__XXX
 SG_ EngOff_T_Actl : 30|16@0+ (1,0) [0|65534] "" Vector__XXX
 SG_ Drive_Mode_FlashReq : 16|2@0+ (1,0) [0|0] "" Vector__XXX
 SG_ Drive_Mode_Enabled : 18|2@0+ (1,0) [0|0] "" Vector__XXX
 SG_ CarMde_D_Actl : 22|4@0+ (1,0) [0|0] "" Vector__XXX
 SG_ PanelBrightLevel_Pc_Actl : 14|8@0+ (1,0) [0|100] "%" Vector__XXX
 SG_ REVSWVLD : 0|1@0+ (1,0) [0|0] ""  ADU
 SG_ Reverselamp_B_Req : 1|1@0+ (1,0) [0|0] ""  ADU
 SG_ IlumiMde_D_Actl : 3|2@0+ (1,0) [0|0] "" Vector__XXX
 SG_ Illum_PowerControlStatus : 4|1@0+ (1,0) [0|0] ""  ADU
 SG_ AudioMute_B_Actl : 5|1@0+ (1,0) [0|0] "" Vector__XXX
 SG_ RoomFuseStat_D_Actl : 7|2@0+ (1,0) [0|0] "" Vector__XXX

BO_ 154 BCM_Information1: 8 CGW
 SG_ BCMINFO1_No_Cs : 63|8@0+ (1,0) [0|255] "" Vector__XXX
 SG_ BCMINFO1_No_Cnt : 51|4@0+ (1,0) [0|15] "" Vector__XXX
 SG_ LED_HI_B : 53|2@0+ (1,0) [0|0] "" Vector__XXX
 SG_ SndRSP_Fail_B_Actl : 54|1@0+ (1,0) [0|0] "" Vector__XXX
 SG_ SndFSP_Fail_B_Actl : 55|1@0+ (1,0) [0|0] "" Vector__XXX
 SG_ FuelCalcCmplt_B_Actl : 40|1@0+ (1,0) [0|0] "" Vector__XXX
 SG_ Refuel2_B_Actl : 41|1@0+ (1,0) [0|0] "" Vector__XXX
 SG_ Refuel1_B_Actl : 42|1@0+ (1,0) [0|0] "" Vector__XXX
 SG_ Hazard_lamp_State_D_Actl : 43|1@0+ (1,0) [0|0] ""  ADU
 SG_ DRL_Tail_Lamp_B_Rq : 44|1@0+ (1,0) [0|0] "" Vector__XXX
 SG_ TNS_Buzzer_Cntl_Req : 45|1@0+ (1,0) [0|0] "" Vector__XXX
 SG_ Turn_Snd_Cmd_Left : 46|1@0+ (1,0) [0|0] "" Vector__XXX
 SG_ Turn_Snd_Cmd_Right : 47|1@0+ (1,0) [0|0] "" Vector__XXX
 SG_ WiprGuid_B_Rq : 32|1@0+ (1,0) [0|0] "" Vector__XXX
 SG_ BurglarHorn_B_Req : 33|1@0+ (1,0) [0|0] "" Vector__XXX
 SG_ RSRmid_Indicator_Req : 35|2@0+ (1,0) [0|0] "" Vector__XXX
 SG_ RSRmid_DisplayReq : 37|2@0+ (1,0) [0|0] "" Vector__XXX
 SG_ BlwCont_B_Actl : 38|1@0+ (1,0) [0|0] "" Vector__XXX
 SG_ FrntWipr_D_Actl : 24|2@0+ (1,0) [0|0] ""  ADU
 SG_ SteeringHeatCutLvl : 26|2@0+ (1,0) [0|0] "" Vector__XXX
 SG_ PtcCutLvl : 28|2@0+ (1,0) [0|0] "" Vector__XXX
 SG_ BmotCutLvl : 30|2@0+ (1,0) [0|0] "" Vector__XXX
 SG_ SeatHeatCutLvl : 16|2@0+ (1,0) [0|0] "" Vector__XXX
 SG_ RdefCutLvl : 18|2@0+ (1,0) [0|0] "" Vector__XXX
 SG_ SeatVentCutLvl : 20|2@0+ (1,0) [0|0] "" Vector__XXX
 SG_ WshrLvl_D_Actl : 22|2@0+ (1,0) [0|0] "" Vector__XXX
 SG_ TNS_IpcDsply_D_Rq : 8|2@0+ (1,0) [0|0] ""  ADU
 SG_ Turn_Ind_Cmd_Left : 9|1@0+ (1,0) [0|0] ""  ADU
 SG_ Turn_Ind_Cmd_Right : 10|1@0+ (1,0) [0|0] ""  ADU
 SG_ Turnlamp_ESS_B_Req : 11|1@0+ (1,0) [0|0] "" Vector__XXX
 SG_ Turnlamp_KoDo_B_Req : 12|1@0+ (1,0) [0|0] "" Vector__XXX
 SG_ LightWarning_D_Rq : 15|3@0+ (1,0) [0|0] ""  ADU
 SG_ ResHeatCont_B_Actl : 0|1@0+ (1,0) [0|0] "" Vector__XXX
 SG_ ResEngCont_B_Actl : 1|1@0+ (1,0) [0|0] "" Vector__XXX
 SG_ CBDA_Sleep_B_Rq : 2|1@0+ (1,0) [0|0] "" Vector__XXX
 SG_ RearWiprLo_B_Rq : 4|2@0+ (1,0) [0|0] "" Vector__XXX
 SG_ AutoWiprIND_B_Rq : 5|1@0+ (1,0) [0|0] "" Vector__XXX
 SG_ RearFogIpcDsply_B_Rq : 6|1@0+ (1,0) [0|0] ""  ADU
 SG_ HiBeamIpcDsply_B_Rq : 7|1@0+ (1,0) [0|0] ""  ADU

BO_ 153 Light_Control: 8 CGW
 SG_ LightCont_No_Cs : 63|8@0+ (1,0) [0|255] ""  ADU
 SG_ LightCont_No_Cnt : 51|4@0+ (1,0) [0|15] ""  ADU
 SG_ SeatBeltWrn_D_Rq : 53|2@0+ (1,0) [0|0] "" Vector__XXX
 SG_ PWGGUID_B_Rq : 54|1@0+ (1,0) [0|0] "" Vector__XXX
 SG_ DrOpnWrn_D_Rq : 40|2@0+ (1,0) [0|0] "" Vector__XXX
 SG_ LVL_Act_Trgt_length : 36|12@0+ (0.005,0) [0|20.475] "mm" Vector__XXX
 SG_ LidStop_B_Req : 20|1@0+ (1,0) [0|0] "" Vector__XXX
 SG_ Outlet_L2_B_Req : 21|1@0+ (1,0) [0|0] "" Vector__XXX
 SG_ Outlet_L1_B_Req : 22|1@0+ (1,0) [0|0] "" Vector__XXX
 SG_ Outlet_R2_B_Req : 23|1@0+ (1,0) [0|0] "" Vector__XXX
 SG_ Outlet_R1_B_Req : 8|1@0+ (1,0) [0|0] "" Vector__XXX
 SG_ Rearfog_B_Req : 9|1@0+ (1,0) [0|0] ""  ADU
 SG_ TnsLamp_Frnt_B_Rq : 10|1@0+ (1,0) [0|0] ""  ADU
 SG_ RLS_Control_req : 12|2@0+ (1,0) [0|0] "" Vector__XXX
 SG_ LghtSwState_D_Qf : 14|2@0+ (1,0) [0|0] ""  ADU
 SG_ Light_LeverSW_Mode_D_Actl : 0|2@0+ (1,0) [0|0] "" Vector__XXX
 SG_ Light_CombiSW_Mode_D_Actl : 2|2@0+ (1,0) [0|0] ""  ADU
 SG_ FSM_Lamp_B_Rq : 3|1@0+ (1,0) [0|0] "" Vector__XXX
 SG_ DRL_Lamp_B_Rq : 4|1@0+ (1,0) [0|0] ""  ADU
 SG_ HeadLampHiCtl_D_Rq : 5|1@0+ (1,0) [0|0] ""  ADU
 SG_ HeadLampLoCtl_D_Rq : 6|1@0+ (1,0) [0|0] ""  ADU
 SG_ TnsLamp_Rear_B_Rq : 7|1@0+ (1,0) [0|0] ""  ADU

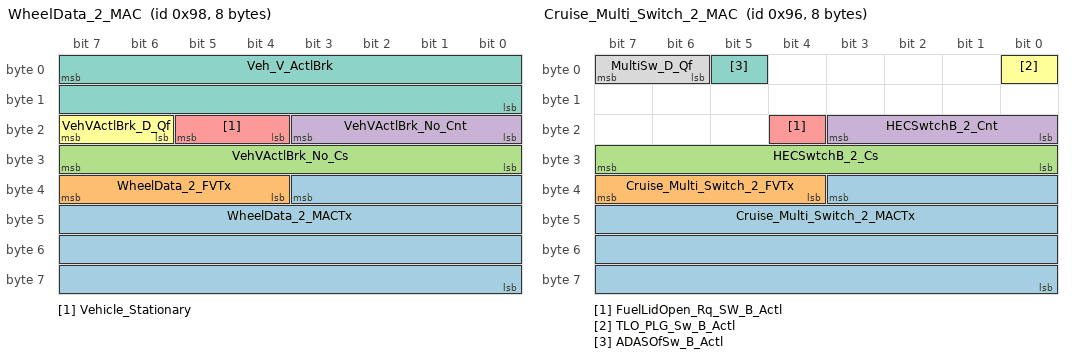
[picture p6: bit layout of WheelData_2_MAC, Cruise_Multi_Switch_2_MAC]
BO_ 152 WheelData_2_MAC: 8 CGW
 SG_ WheelData_2_MACTx : 35|28@0+ (1,0) [0|268435455] ""  ADU
 SG_ WheelData_2_FVTx : 39|4@0+ (1,0) [0|15] ""  ADU
 SG_ VehVActlBrk_No_Cs : 31|8@0+ (1,0) [0|255] ""  ADU
 SG_ VehVActlBrk_No_Cnt : 19|4@0+ (1,0) [0|15] ""  ADU
 SG_ Vehicle_Stationary : 21|2@0+ (1,0) [0|0] "" Vector__XXX
 SG_ VehVActlBrk_D_Qf : 23|2@0+ (1,0) [0|0] ""  ADU
 SG_ Veh_V_ActlBrk : 7|16@0+ (0.01,0) [0|655.35] "kph"  ADU

BO_ 150 Cruise_Multi_Switch_2_MAC: 8 CGW
 SG_ Cruise_Multi_Switch_2_MACTx : 35|28@0+ (1,0) [0|268435455] "" Vector__XXX
 SG_ Cruise_Multi_Switch_2_FVTx : 39|4@0+ (1,0) [0|15] "" Vector__XXX
 SG_ HECSwtchB_2_Cs : 31|8@0+ (1,0) [0|255] "" Vector__XXX
 SG_ HECSwtchB_2_Cnt : 19|4@0+ (1,0) [0|15] "" Vector__XXX
 SG_ FuelLidOpen_Rq_SW_B_Actl : 20|1@0+ (1,0) [0|0] "" Vector__XXX
 SG_ TLO_PLG_Sw_B_Actl : 0|1@0+ (1,0) [0|0] "" Vector__XXX
 SG_ ADASOfSw_B_Actl : 5|1@0+ (1,0) [0|0] ""  ADU
 SG_ MultiSw_D_Qf : 7|2@0+ (1,0) [0|0] ""  ADU

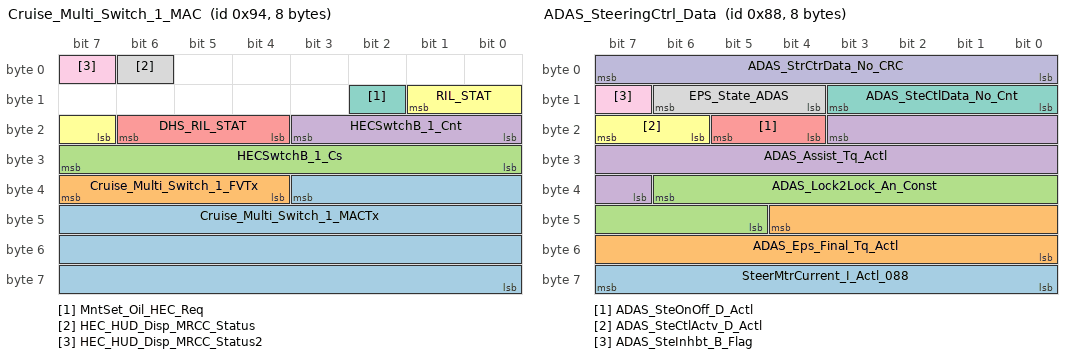
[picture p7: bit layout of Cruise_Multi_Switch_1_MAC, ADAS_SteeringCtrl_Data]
BO_ 148 Cruise_Multi_Switch_1_MAC: 8 CGW
 SG_ Cruise_Multi_Switch_1_MACTx : 35|28@0+ (1,0) [0|268435455] ""  ADU
 SG_ Cruise_Multi_Switch_1_FVTx : 39|4@0+ (1,0) [0|15] ""  ADU
 SG_ HECSwtchB_1_Cs : 31|8@0+ (1,0) [0|255] ""  ADU
 SG_ HECSwtchB_1_Cnt : 19|4@0+ (1,0) [0|15] ""  ADU
 SG_ DHS_RIL_STAT : 22|3@0+ (1,0) [0|0] "" Vector__XXX
 SG_ RIL_STAT : 9|3@0+ (1,0) [0|0] "" Vector__XXX
 SG_ MntSet_Oil_HEC_Req : 10|1@0+ (1,0) [0|0] "" Vector__XXX
 SG_ HEC_HUD_Disp_MRCC_Status : 6|1@0+ (1,0) [0|0] ""  ADU
 SG_ HEC_HUD_Disp_MRCC_Status2 : 7|1@0+ (1,0) [0|0] ""  ADU

BO_ 145 Steering_Column_Switch: 8 CGW
 SG_ HECSwtchA_Cs : 63|8@0+ (1,0) [0|255] ""  ADU
 SG_ HECSwtchA_Cnt : 51|4@0+ (1,0) [0|15] ""  ADU
 SG_ WiprTestMode_B_Actl : 54|1@0+ (1,0) [0|0] "" Vector__XXX
 SG_ FrntWiprInt_V_Actl : 47|8@0+ (1,0) [0|100] "Percent" Vector__XXX
 SG_ PaddleShiftDwn_D_Actl : 29|2@0+ (1,0) [0|0] "" Vector__XXX
 SG_ PaddleShiftUp_D_Actl : 31|2@0+ (1,0) [0|0] "" Vector__XXX
 SG_ RearWasherSw_B_Actl : 16|1@0+ (1,0) [0|0] "" Vector__XXX
 SG_ FrntWasherSw_B_Actl : 17|1@0+ (1,0) [0|0] ""  ADU
 SG_ RearWiprStats_D_Actl : 19|2@0+ (1,0) [0|0] "" Vector__XXX
 SG_ FrntWiprStats_D_Actl : 21|2@0+ (1,0) [0|0] ""  ADU
 SG_ WiprSw_D_Qf : 23|2@0+ (1,0) [0|0] ""  ADU
 SG_ ALH_HBC_Sw_B_Actl : 9|1@0+ (1,0) [0|0] ""  ADU
 SG_ Mfs_Turn_Neutral_SW_Status : 11|1@0+ (1,0) [0|0] ""  ADU
 SG_ Mfs_Turn_Stalk_SW_Status : 13|2@0+ (1,0) [0|0] ""  ADU
 SG_ HeadLghtOffSw_B_Actl : 14|1@0+ (1,0) [0|0] ""  ADU
 SG_ PassngSw_B_Actl : 15|1@0+ (1,0) [0|0] ""  ADU
 SG_ RearFogSw_B_Actl : 0|1@0+ (1,0) [0|0] ""  ADU
 SG_ HeadLghtHiSw_B_Actl : 3|1@0+ (1,0) [0|0] ""  ADU
 SG_ HeadLghtLoSw_B_Actl : 4|1@0+ (1,0) [0|0] ""  ADU
 SG_ TnsSw_B_Actl : 5|1@0+ (1,0) [0|0] ""  ADU
 SG_ LghtSw_D_Qf : 7|2@0+ (1,0) [0|0] ""  ADU

BO_ 139 FCM1S95: 32 ADU
 SG_ KZK08B_MACTx : 227|28@0+ (1,0) [0|268435455] ""  CGW
 SG_ FV08B_FVTx : 231|4@0+ (1,0) [0|15] ""  CGW
 SG_ TSS_SPDL : 209|10@0+ (0.25,0) [0|255.75] "km/h"  CGW
 SG_ TSS_SPDH : 193|10@0+ (0.25,0) [0|255.75] "km/h"  CGW
 SG_ TSSAORFG : 184|1@0+ (1,0) [0|0] ""  CGW
 SG_ TSSACLPH : 185|1@0+ (1,0) [0|0] ""  CGW
 SG_ TSS_RNGR : 188|3@0+ (1,0) [0|0] ""  CGW
 SG_ TSS_PRE : 190|2@0+ (1,0) [0|0] ""  CGW
 SG_ TSS_RSPH : 177|2@0+ (1,0) [0|0] ""  CGW
 SG_ AEBPOSS : 178|1@0+ (1,0) [0|0] ""  CGW
 SG_ TSS_RSPL : 180|2@0+ (1,0) [0|0] ""  CGW
 SG_ TSS_ACLP : 181|1@0+ (1,0) [0|0] ""  CGW
 SG_ TSS_SFTH : 182|1@0+ (1,0) [0|0] ""  CGW
 SG_ TSSLTBKH : 183|1@0+ (1,0) [0|0] ""  CGW
 SG_ TSSCSRQH : 170|1@0+ (1,0) [0|0] ""  CGW
 SG_ TSSCSRQL : 171|1@0+ (1,0) [0|0] ""  CGW
 SG_ TSSINTEL : 172|1@0+ (1,0) [0|0] ""  CGW
 SG_ TSSINTEH : 173|1@0+ (1,0) [0|0] ""  CGW
 SG_ TSSLGFDH : 175|2@0+ (1,0) [0|0] ""  CGW
 SG_ TSSLGIDH : 165|6@0+ (1,0) [0|0] ""  CGW
 SG_ TSS_SFTL : 166|1@0+ (1,0) [0|0] ""  CGW
 SG_ TSSLTBKL : 167|1@0+ (1,0) [0|0] ""  CGW
 SG_ TSS_RACH : 135|16@0- (0.001,0) [-32.768|32.767] "m/s^2"  CGW
 SG_ TSS_ACCH : 111|16@0- (0.001,0) [-32.768|32.767] "m/s^2"  CGW
 SG_ TSS_RACL : 95|16@0- (0.001,0) [-32.768|32.767] "m/s^2"  CGW
 SG_ TSS_ACCL : 71|16@0- (0.001,0) [-32.768|32.767] "m/s^2"  CGW
 SG_ SMKZ08A : 63|8@0+ (1,0) [0|255] ""  CGW
 SG_ TSSLGFDL : 49|2@0+ (1,0) [0|0] ""  CGW
 SG_ TSSLGIDL : 55|6@0+ (1,0) [0|0] ""  CGW
 SG_ TSSBHNGH : 40|1@0+ (1,0) [0|0] ""  CGW
 SG_ TSSSCOKH : 41|1@0+ (1,0) [0|0] ""  CGW
 SG_ TSSBHNGL : 42|1@0+ (1,0) [0|0] ""  CGW
 SG_ TSSSCOKL : 43|1@0+ (1,0) [0|0] ""  CGW
 SG_ TSS_EPBR : 45|2@0+ (1,0) [0|0] ""  CGW
 SG_ SRQEXIST : 46|1@0+ (1,0) [0|0] ""  CGW
 SG_ TSSINV : 47|1@0+ (1,0) [0|0] ""  CGW
 SG_ SCMEXIST : 33|2@0+ (1,0) [0|0] ""  CGW
 SG_ ADSECOST : 35|2@0+ (1,0) [0|0] ""  CGW
 SG_ ESSEGON : 37|1@0+ (1,0) [0|0] ""  CGW
 SG_ PCSALM : 38|1@0+ (1,0) [0|0] ""  CGW
 SG_ ACCFCMF : 39|1@0+ (1,0) [0|0] ""  CGW
 SG_ VGRSTRGR : 25|2@0+ (1,0) [0|0] ""  CGW
 SG_ PCSNOCHG : 26|1@0+ (1,0) [0|0] ""  CGW
 SG_ ACCACT : 27|1@0+ (1,0) [0|0] ""  CGW
 SG_ ACCMOFF : 28|1@0+ (1,0) [0|0] ""  CGW
 SG_ PBATRGR : 30|2@0+ (1,0) [0|0] ""  CGW
 SG_ AVSTRGR : 31|1@0+ (1,0) [0|0] ""  CGW
 SG_ E_CNT08B : 23|8@0+ (1,0) [0|255] ""  CGW
 SG_ E_CRC08B : 7|16@0+ (1,0) [0|65535] ""  CGW

BO_ 136 ADAS_SteeringCtrl_Data: 8 CGW
 SG_ SteerMtrCurrent_I_Actl_088 : 63|8@0+ (1,-127) [-127|127] "Ampere" Vector__XXX
 SG_ ADAS_Eps_Final_Tq_Actl : 44|13@0+ (0.05,-204.75) [-204.75|204.75] "Nm"  ADU
 SG_ ADAS_Lock2Lock_An_Const : 38|10@0+ (1,0) [0|1023] "Angle"  ADU
 SG_ ADAS_Assist_Tq_Actl : 19|13@0+ (0.05,-204.75) [-204.75|204.75] "Nm"  ADU
 SG_ ADAS_SteOnOff_D_Actl : 21|2@0+ (1,0) [0|0] ""  ADU
 SG_ ADAS_SteCtlActv_D_Actl : 23|2@0+ (1,0) [0|0] ""  ADU
 SG_ ADAS_SteCtlData_No_Cnt : 11|4@0+ (1,0) [0|15] ""  ADU
 SG_ EPS_State_ADAS : 14|3@0+ (1,0) [0|0] ""  ADU
 SG_ ADAS_SteInhbt_B_Flag : 15|1@0+ (1,0) [0|0] ""  ADU
 SG_ ADAS_StrCtrData_No_CRC : 7|8@0+ (1,0) [0|255] ""  ADU

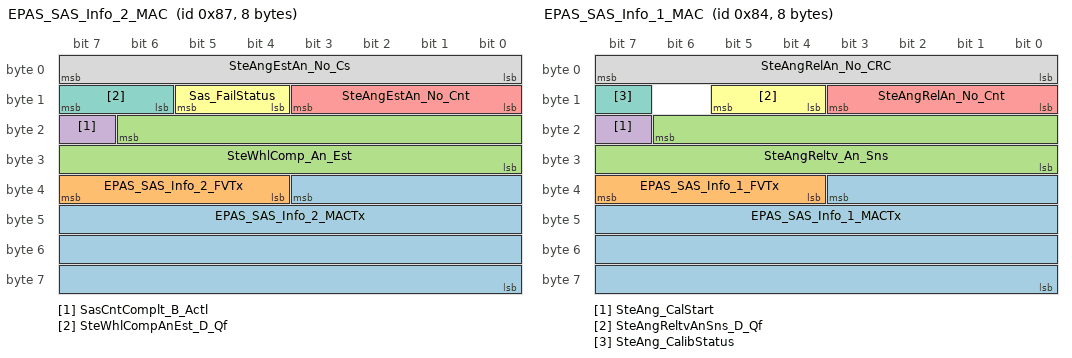
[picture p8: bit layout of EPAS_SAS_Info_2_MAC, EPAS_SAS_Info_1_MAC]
BO_ 135 EPAS_SAS_Info_2_MAC: 8 CGW
 SG_ EPAS_SAS_Info_2_MACTx : 35|28@0+ (1,0) [0|268435455] "" Vector__XXX
 SG_ EPAS_SAS_Info_2_FVTx : 39|4@0+ (1,0) [0|15] "" Vector__XXX
 SG_ SteWhlComp_An_Est : 22|15@0+ (0.1,-1600) [-1600|1676.7] "deg"  ADU
 SG_ SasCntComplt_B_Actl : 23|1@0+ (1,0) [0|0] "" Vector__XXX
 SG_ SteAngEstAn_No_Cnt : 11|4@0+ (1,0) [0|15] "" Vector__XXX
 SG_ Sas_FailStatus : 13|2@0+ (1,0) [0|0] "" Vector__XXX
 SG_ SteWhlCompAnEst_D_Qf : 15|2@0+ (1,0) [0|0] ""  ADU
 SG_ SteAngEstAn_No_Cs : 7|8@0+ (1,0) [0|255] ""  ADU

BO_ 133 CSR1G10: 32 ADU
 SG_ KZK085_MACTx : 227|28@0+ (1,0) [0|268435455] ""  CGW
 SG_ FV085_FVTx : 231|4@0+ (1,0) [0|15] ""  CGW
 SG_ APPSCS : 189|2@0+ (1,0) [0|0] ""  CGW
 SG_ TSSVSPAU : 190|1@0+ (1,0) [0|0] ""  CGW
 SG_ TSSVSPAV : 191|1@0+ (1,0) [0|0] ""  CGW
 SG_ TSS_STR : 175|16@0- (0.001,0) [-32.768|32.767] "rad"  CGW
 SG_ TSSLTRSP : 162|3@0+ (1,0) [0|0] ""  CGW
 SG_ CSRPPMP : 163|1@0+ (1,0) [0|0] ""  CGW
 SG_ CSRAORFG : 164|1@0+ (1,0) [0|0] ""  CGW
 SG_ CSRLMRL : 165|1@0+ (1,0) [0|0] ""  CGW
 SG_ CSRRQBH : 166|1@0+ (1,0) [0|0] ""  CGW
 SG_ TSS_DSTR : 167|1@0+ (1,0) [0|0] ""  CGW
 SG_ TSS_VSPA : 151|16@0- (0.001,0) [-32.768|32.767] "rad"  CGW
 SG_ TSSLDRCO : 139|4@0+ (1,0) [0|0] ""  CGW
 SG_ TSSLGRCH : 143|4@0+ (1,0) [0|0] ""  CGW
 SG_ TSSLTRGN : 135|8@0+ (0.02,0) [0|5.1] ""  CGW
 SG_ SRQCOUNT : 125|6@0+ (1,0) [0|63] ""  CGW
 SG_ DEG6DOF : 127|2@0+ (1,0) [0|0] ""  CGW
 SG_ DMPGAIN : 119|8@0+ (0.01,0) [0|2.55] ""  CGW
 SG_ SYSGAIN : 111|8@0+ (0.01,0) [0|2.55] ""  CGW
 SG_ TSSLTRCK : 99|4@0+ (1,0) [0|0] ""  CGW
 SG_ STVIBFTV : 102|3@0+ (1,0) [0|0] ""  CGW
 SG_ TRAFAIL : 103|1@0+ (1,0) [0|0] ""  CGW
 SG_ CSRGBRK : 87|16@0- (0.001,0) [-32.768|32.767] "m/s^2"  CGW
 SG_ CSRGDRV : 71|16@0- (0.001,0) [-32.768|32.767] "m/s^2"  CGW
 SG_ TSS_LTID : 61|6@0+ (1,0) [0|0] ""  CGW
 SG_ E_APPF : 62|1@0+ (1,0) [0|0] ""  CGW
 SG_ ICSFAIL : 63|1@0+ (1,0) [0|0] ""  CGW
 SG_ CSRBRKID : 53|6@0+ (1,0) [0|0] ""  CGW
 SG_ RCPEXBRK : 54|1@0+ (1,0) [0|0] ""  CGW
 SG_ ICSSYS : 55|1@0+ (1,0) [0|0] ""  CGW
 SG_ CSRDRVID : 45|6@0+ (1,0) [0|0] ""  CGW
 SG_ CSRRQSFT : 34|3@0+ (1,0) [0|0] ""  CGW
 SG_ CSR_RNGR : 37|3@0+ (1,0) [0|0] ""  CGW
 SG_ CSRRCSFT : 39|2@0+ (1,0) [0|0] ""  CGW
 SG_ CSR_EPBR : 25|2@0+ (1,0) [0|0] ""  CGW
 SG_ APPFAIL : 26|1@0+ (1,0) [0|0] ""  CGW
 SG_ APPSYS : 27|1@0+ (1,0) [0|0] ""  CGW
 SG_ APPEXIST : 28|1@0+ (1,0) [0|0] ""  CGW
 SG_ APPMD : 31|3@0+ (1,0) [0|0] ""  CGW
 SG_ E_CNT085 : 23|8@0+ (1,0) [0|255] ""  CGW
 SG_ E_CRC085 : 7|16@0+ (1,0) [0|65535] ""  CGW

BO_ 132 EPAS_SAS_Info_1_MAC: 8 CGW
 SG_ EPAS_SAS_Info_1_MACTx : 35|28@0+ (1,0) [0|268435455] "" Vector__XXX
 SG_ EPAS_SAS_Info_1_FVTx : 39|4@0+ (1,0) [0|15] "" Vector__XXX
 SG_ SteAngReltv_An_Sns : 22|15@0+ (0.1,-1600) [-1600|1676.7] "deg"  ADU
 SG_ SteAng_CalStart : 23|1@0+ (1,0) [0|0] "" Vector__XXX
 SG_ SteAngRelAn_No_Cnt : 11|4@0+ (1,0) [0|15] ""  ADU
 SG_ SteAngReltvAnSns_D_Qf : 13|2@0+ (1,0) [0|0] ""  ADU
 SG_ SteAng_CalibStatus : 15|1@0+ (1,0) [0|0] "" Vector__XXX
 SG_ SteAngRelAn_No_CRC : 7|8@0+ (1,0) [0|255] "" Vector__XXX

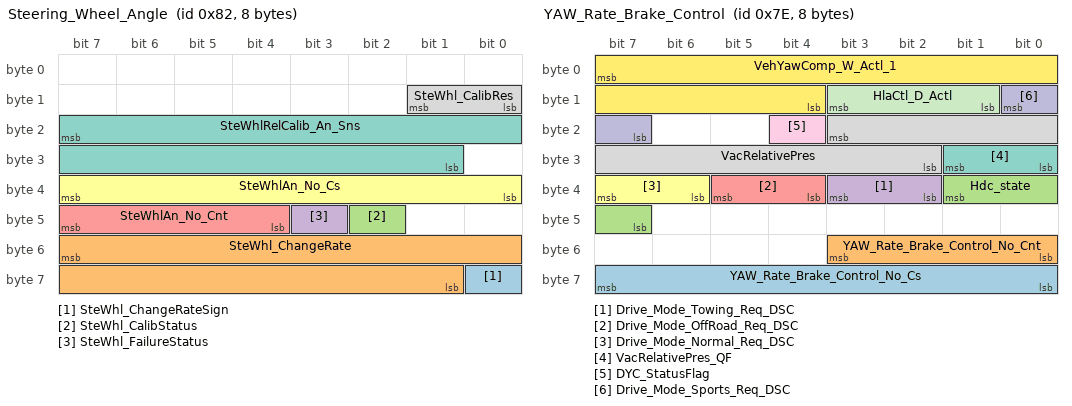
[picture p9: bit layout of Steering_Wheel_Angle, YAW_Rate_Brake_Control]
BO_ 130 Steering_Wheel_Angle: 8 CGW
 SG_ SteWhl_ChangeRateSign : 56|1@0+ (1,0) [0|0] ""  ADU
 SG_ SteWhl_ChangeRate : 55|15@0+ (0.06104,0) [0|1999.9756] "deg/s"  ADU
 SG_ SteWhl_CalibStatus : 42|1@0+ (1,0) [0|0] ""  ADU
 SG_ SteWhl_FailureStatus : 43|1@0+ (1,0) [0|0] ""  ADU
 SG_ SteWhlAn_No_Cnt : 47|4@0+ (1,0) [0|15] "Counts"  ADU
 SG_ SteWhlAn_No_Cs : 39|8@0+ (1,0) [0|255] ""  ADU
 SG_ SteWhlRelCalib_An_Sns : 23|15@0+ (0.1,-1600) [-1600|1676.7] "Deg"  ADU
 SG_ SteWhl_CalibRes : 9|2@0+ (1,0) [0|0] ""  ADU

BO_ 129 VSC1G12: 32 CGW
 SG_ KZK081_MACTx : 227|28@0+ (1,0) [0|268435455] ""  ADU
 SG_ FV081_FVTx : 231|4@0+ (1,0) [0|15] ""  ADU
 SG_ V_YR1HR0 : 103|16@0+ (0.01,-100) [-100|100] "des/s"  ADU
 SG_ V_GYHR0 : 87|16@0+ (1,-3000) [-3000|3000] "mG"  ADU
 SG_ V_GXHR0 : 71|16@0+ (1,-3000) [-3000|3000] "mG"  ADU
 SG_ SMKZ090 : 63|8@0+ (1,0) [0|255] ""  ADU
 SG_ ID081_No_Cnt : 51|4@0+ (1,0) [0|15] ""  ADU
 SG_ VSC_YAW0 : 33|10@0+ (0.244140625,-125.00000001) [-99.853515635|99.853515615] "des/s"  ADU
 SG_ VSC_YAWF : 38|1@0+ (1,0) [0|0] ""  ADU
 SG_ VSC_YAWS : 39|1@0+ (1,0) [0|0] ""  ADU
 SG_ VSC_GY0 : 17|10@0+ (0.035888672,-18.375) [-18.375|18.339111456] "m/s^2"  ADU
 SG_ VSC_GYIV : 22|1@0+ (1,0) [0|0] ""  ADU
 SG_ VSC_GYF : 23|1@0+ (1,0) [0|0] ""  ADU
 SG_ VSC_GX0 : 1|10@0+ (0.035888672,-18.375) [-18.375|18.339111456] "m/s^2"  ADU
 SG_ VSC_GXIV : 6|1@0+ (1,0) [0|0] ""  ADU
 SG_ VSC_GXF : 7|1@0+ (1,0) [0|0] ""  ADU

BO_ 126 YAW_Rate_Brake_Control: 8 CGW
 SG_ YAW_Rate_Brake_Control_No_Cs : 63|8@0+ (1,0) [0|255] "" Vector__XXX
 SG_ YAW_Rate_Brake_Control_No_Cnt : 51|4@0+ (1,0) [0|15] "" Vector__XXX
 SG_ Hdc_state : 33|3@0+ (1,0) [0|0] ""  ADU
 SG_ Drive_Mode_Towing_Req_DSC : 35|2@0+ (1,0) [0|0] "" Vector__XXX
 SG_ Drive_Mode_OffRoad_Req_DSC : 37|2@0+ (1,0) [0|0] "" Vector__XXX
 SG_ Drive_Mode_Normal_Req_DSC : 39|2@0+ (1,0) [0|0] "" Vector__XXX
 SG_ VacRelativePres_QF : 25|2@0+ (1,0) [0|0] "" Vector__XXX
 SG_ VacRelativePres : 19|10@0+ (0.1,-100) [-100|2.3] "Kpa" Vector__XXX
 SG_ DYC_StatusFlag : 20|1@0+ (1,0) [0|0] "" Vector__XXX
 SG_ Drive_Mode_Sports_Req_DSC : 8|2@0+ (1,0) [0|0] ""  ADU
 SG_ HlaCtl_D_Actl : 11|3@0+ (1,0) [0|0] "" Vector__XXX
 SG_ VehYawComp_W_Actl_1 : 7|12@0+ (0.03663,-74.98161) [-74.98161|75.01824] "degrees/second" Vector__XXX

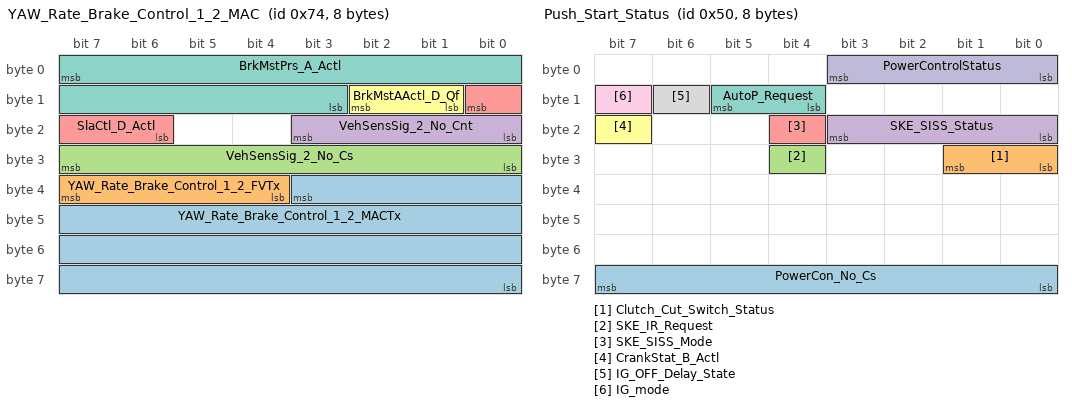
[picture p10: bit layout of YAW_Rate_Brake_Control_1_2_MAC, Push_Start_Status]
BO_ 116 YAW_Rate_Brake_Control_1_2_MAC: 8 CGW
 SG_ YAW_Rate_Brake_Control_1_2_MACTx : 35|28@0+ (1,0) [0|268435455] ""  ADU
 SG_ YAW_Rate_Brake_Control_1_2_FVTx : 39|4@0+ (1,0) [0|15] ""  ADU
 SG_ VehSensSig_2_No_Cs : 31|8@0+ (1,0) [0|255] ""  ADU
 SG_ VehSensSig_2_No_Cnt : 19|4@0+ (1,0) [0|15] ""  ADU
 SG_ SlaCtl_D_Actl : 8|3@0+ (1,0) [0|0] "" Vector__XXX
 SG_ BrkMstAActl_D_Qf : 10|2@0+ (1,0) [0|0] ""  ADU
 SG_ BrkMstPrs_A_Actl : 7|13@0+ (0.032768,-5) [-5|19.969216] "MPa"  ADU

BO_ 80 Push_Start_Status: 8 CGW
 SG_ PowerCon_No_Cs : 63|8@0+ (1,0) [0|255] "" Vector__XXX
 SG_ Clutch_Cut_Switch_Status : 25|2@0+ (1,0) [0|0] "" Vector__XXX
 SG_ SKE_IR_Request : 28|1@0+ (1,0) [0|0] "" Vector__XXX
 SG_ SKE_SISS_Status : 19|4@0+ (1,0) [0|0] "" Vector__XXX
 SG_ SKE_SISS_Mode : 20|1@0+ (1,0) [0|0] "" Vector__XXX
 SG_ CrankStat_B_Actl : 23|1@0+ (1,0) [0|0] "" Vector__XXX
 SG_ AutoP_Request : 13|2@0+ (1,0) [0|0] "" Vector__XXX
 SG_ IG_OFF_Delay_State : 14|1@0+ (1,0) [0|0] "" Vector__XXX
 SG_ IG_mode : 15|1@0+ (1,0) [0|0] "" Vector__XXX
 SG_ PowerControlStatus : 3|4@0+ (1,0) [0|0] ""  ADU

BO_ 48 EPS1S11: 32 CGW
 SG_ KZK030_MACTx : 227|28@0+ (1,0) [0|268435455] ""  ADU
 SG_ FV030_FVTx : 231|4@0+ (1,0) [0|15] ""  ADU
 SG_ EPSACT5 : 216|1@0+ (1,0) [0|0] ""  ADU
 SG_ EPSSTS5 : 217|1@0+ (1,0) [0|0] ""  ADU
 SG_ EPSSATGF : 219|1@0+ (1,0) [0|0] ""  ADU
 SG_ EPSSATG : 215|12@0- (1.5,0) [-3072|3070.5] "deg"  ADU
 SG_ EPS1S11_No_Cnt : 203|4@0+ (1,0) [0|15] "Counts"  ADU
 SG_ EPSTRQ : 183|16@0- (0.01,0) [-327.68|327.67] "Nm"  ADU
 SG_ EPS_AEST : 167|16@0- (0.001,0) [-32.768|32.767] "rad"  ADU
 SG_ EPSAESTF : 152|1@0+ (1,0) [0|0] ""  ADU
 SG_ EPSADACT : 145|2@0+ (1,0) [0|0] ""  ADU
 SG_ DRTGTSTR : 151|6@0+ (2,0) [0|126] "%"  ADU
 SG_ TRQSENSS : 139|4@0- (0.01,0) [-0.08|0.07] "Nm"  ADU
 SG_ EPSSTS0 : 142|1@0+ (1,0) [0|0] ""  ADU
 SG_ EPSACT : 143|1@0+ (1,0) [0|0] ""  ADU
 SG_ EPSFANG : 128|1@0+ (1,0) [0|0] ""  ADU
 SG_ STRUNSET : 131|1@0+ (1,0) [0|0] ""  ADU
 SG_ GRDF : 132|1@0+ (1,0) [0|0] ""  ADU
 SG_ DGRDF : 133|1@0+ (1,0) [0|0] ""  ADU
 SG_ EPSFC : 105|2@0+ (1,0) [0|0] ""  ADU
 SG_ EPSVSPAC : 83|1@0+ (1,0) [0|0] ""  ADU
 SG_ EPS_VSPA : 71|16@0- (0.001,0) [-32.768|32.767] "rad"  ADU
 SG_ SMKZ030 : 63|8@0+ (1,0) [0|255] ""  ADU
 SG_ TRQSENSF : 48|1@0+ (1,0) [0|0] ""  ADU
 SG_ EPSF : 50|1@0+ (1,0) [0|0] ""  ADU
 SG_ EPSSAINV : 51|1@0+ (1,0) [0|0] ""  ADU
 SG_ EPSSAV : 47|12@0- (1,0) [-2048|2047] "deg/s"  ADU
 SG_ EPSSAS : 35|4@0- (0.1,0) [-0.8|0.6] "deg"  ADU
 SG_ EPSSA : 31|12@0- (1.5,0) [-3072|3070.5] "deg"  ADU
 SG_ EPSTS1 : 16|1@0+ (1,0) [0|0] ""  ADU
 SG_ TRQSENS : 7|8@0- (0.1,0) [-12.8|12.6] "Nm"  ADU

BO_ 38 STR1S01: 32 CGW
 SG_ KZK026_MACTx : 227|28@0+ (1,0) [0|268435455] ""  ADU
 SG_ FV026_FVTx : 231|4@0+ (1,0) [0|15] ""  ADU
 SG_ SteWhl_ChangeRateSign2 : 56|1@0+ (1,0) [0|0] ""  ADU
 SG_ SteWhl_ChangeRate2 : 55|15@0+ (0.06104,0) [0|1999.9756] "deg/s"  ADU
 SG_ SteWhl_CalibStatus2 : 42|1@0+ (1,0) [0|0] ""  ADU
 SG_ SteWhl_FailureStatus2 : 43|1@0+ (1,0) [0|0] ""  ADU
 SG_ SteWhlAn_No_Cnt2 : 47|4@0+ (1,0) [0|15] "Counts"  ADU
 SG_ SteWhlAn_No_Cs2 : 39|8@0+ (1,0) [0|255] ""  ADU
 SG_ SteWhlRelCalib_An_Sns2 : 23|15@0+ (0.1,-1600) [-1600|1676.7] "Deg"  ADU
 SG_ SteWhl_CalibRes2 : 9|2@0+ (1,0) [0|0] ""  ADU

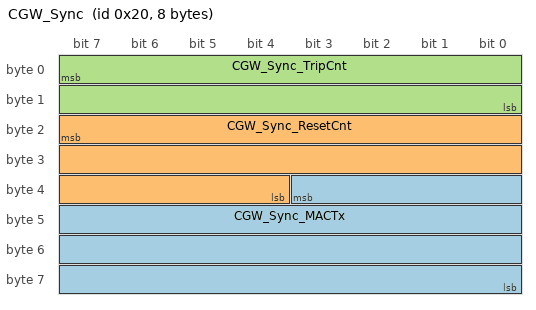
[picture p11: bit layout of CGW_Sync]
BO_ 32 CGW_Sync: 8 CGW
 SG_ CGW_Sync_MACTx : 35|28@0+ (1,0) [0|268435455] ""  ADU
 SG_ CGW_Sync_ResetCnt : 23|20@0+ (1,0) [0|1048575] ""  ADU
 SG_ CGW_Sync_TripCnt : 7|16@0+ (1,0) [0|65535] ""  ADU

BO_ 28 MACKVERI4: 8 CGW
 SG_ MACKVERI4_2 : 39|32@0+ (1,0) [0|4294967295] ""  ADU
 SG_ MACKVERI4_1 : 7|32@0+ (1,0) [0|4294967295] ""  ADU

BO_ 27 MACKVERI3: 8 CGW
 SG_ MACKVERI3_2 : 39|32@0+ (1,0) [0|4294967295] ""  ADU
 SG_ MACKVERI3_1 : 7|32@0+ (1,0) [0|4294967295] ""  ADU

BO_ 26 MACKVERI2: 8 CGW
 SG_ MACKVERI2_2 : 39|32@0+ (1,0) [0|4294967295] ""  ADU
 SG_ MACKVERI2_1 : 7|32@0+ (1,0) [0|4294967295] ""  ADU

BO_ 25 MACKVERI1: 8 CGW
 SG_ MACKVERI1_2 : 39|32@0+ (1,0) [0|4294967295] ""  ADU
 SG_ MACKVERI1_1 : 7|32@0+ (1,0) [0|4294967295] ""  ADU

BO_ 24 MACKID_MACKUSAGE: 8 CGW
 SG_ MACKUSAGE : 15|8@0+ (1,0) [0|255] ""  ADU
 SG_ MACKID : 7|8@0+ (1,0) [0|255] ""  ADU

BO_ 23 MACKSEND8: 8 CGW
 SG_ MACKSEND8_2 : 39|32@0+ (1,0) [0|4294967295] ""  ADU
 SG_ MACKSEND8_1 : 7|32@0+ (1,0) [0|4294967295] ""  ADU

BO_ 22 MACKSEND7: 8 CGW
 SG_ MACKSEND7_2 : 39|32@0+ (1,0) [0|4294967295] ""  ADU
 SG_ MACKSEND7_1 : 7|32@0+ (1,0) [0|4294967295] ""  ADU

BO_ 21 MACKSEND6: 8 CGW
 SG_ MACKSEND6_2 : 39|32@0+ (1,0) [0|4294967295] ""  ADU
 SG_ MACKSEND6_1 : 7|32@0+ (1,0) [0|4294967295] ""  ADU

BO_ 20 MACKSEND5: 8 CGW
 SG_ MACKSEND5_2 : 39|32@0+ (1,0) [0|4294967295] ""  ADU
 SG_ MACKSEND5_1 : 7|32@0+ (1,0) [0|4294967295] ""  ADU

BO_ 19 MACKSEND4: 8 CGW
 SG_ MACKSEND4_2 : 39|32@0+ (1,0) [0|4294967295] ""  ADU
 SG_ MACKSEND4_1 : 7|32@0+ (1,0) [0|4294967295] ""  ADU

BO_ 18 MACKSEND3: 8 CGW
 SG_ MACKSEND3_2 : 39|32@0+ (1,0) [0|4294967295] ""  ADU
 SG_ MACKSEND3_1 : 7|32@0+ (1,0) [0|4294967295] ""  ADU

BO_ 17 MACKSEND2: 8 CGW
 SG_ MACKSEND2_2 : 39|32@0+ (1,0) [0|4294967295] ""  ADU
 SG_ MACKSEND2_1 : 7|32@0+ (1,0) [0|4294967295] ""  ADU

BO_ 16 MACKSEND1: 8 CGW
 SG_ MACKSEND1_2 : 39|32@0+ (1,0) [0|4294967295] ""  ADU
 SG_ MACKSEND1_1 : 7|32@0+ (1,0) [0|4294967295] ""  ADU

BA_DEF_REL_ BU_SG_REL_  "SC_Verification" ENUM  "No","Yes";
BA_DEF_ BO_  "SCP_FreshnessValueTxLength" INT 0 512;
BA_DEF_ BO_  "SCP_FreshnessValueLength" INT 0 512;
BA_DEF_ BO_  "SCP_DataId" INT 0 65535;
BA_DEF_ BO_  "SCP_AuthInfoTxLength" INT 0 512;
BA_DEF_ BO_  "SC_Message" ENUM  "No","Yes";
BA_DEF_ BO_  "CANFD_BRS" ENUM  "0","1";
BA_DEF_ BO_  "VFrameFormat" ENUM  "StandardCAN","ExtendedCAN","reserved","reserved","reserved","reserved","reserved","reserved","reserved","reserved","reserved","reserved","reserved","reserved","StandardCAN_FD","ExtendedCAN_FD";
BA_DEF_ BO_  "DiagRequest" ENUM  "No","Yes";
BA_DEF_ BO_  "DiagResponse" ENUM  "No","Yes";
BA_DEF_ BO_  "DiagState" ENUM  "No","Yes";
BA_DEF_ BO_  "DiagConnection" INT 0 65535;
BA_DEF_ BO_  "GenMsgCycleTime" INT 0 10000;
BA_DEF_ BO_  "GenMsgCycleTimeFast" INT 0 100000;
BA_DEF_ BO_  "GenMsgDelayTime" INT 0 1000;
BA_DEF_ BO_  "GenMsgILSupport" ENUM  "No","Yes";
BA_DEF_ BO_  "GenMsgNrOfRepetition" INT 0 100;
BA_DEF_ BO_  "GenMsgSendType" ENUM  "FixedPeriodic","Event","EnabledPeriodic","NotUsed","NotUsed","EventPeriodic","NotUsed","NotUsed","NoMsgSendType";
BA_DEF_ SG_  "GenSigSendType" ENUM  "Cyclic","OnWrite","OnWriteWithRepetition","OnChange","OnChangeWithRepetition","IfActive","IfActiveWithRepetition","NoSigSendType";
BA_DEF_ SG_  "GenSigStartValue" FLOAT 0 1E+011;
BA_DEF_ SG_  "GenSigTimeoutTime_CGW" INT 0 100000;
BA_DEF_ SG_  "GenSigTimeoutTime_ADU" INT 0 100000;
BA_DEF_ BO_  "NetworkInitialization" ENUM  "No","Yes";
BA_DEF_ SG_  "GenSigEnvVarType" ENUM  "int","float","undef";
BA_DEF_ SG_  "NWM-WakeupAllowed" ENUM  "No","Yes";
BA_DEF_ BO_  "NmAsrMessage" ENUM  "No","Yes";
BA_DEF_ BO_  "GenMsgTxConditionAccOn" ENUM  "No","Yes";
BA_DEF_ BO_  "GenMsgTxConditionIg1On" ENUM  "No","Yes";
BA_DEF_ BO_  "GenMsgTxConditionPlusBOn" ENUM  "No","Yes";
BA_DEF_ SG_  "GenSigInvalidValue" INT 0 10000000000;
BA_DEF_ BO_  "CANoeMsgTxTimingIgnitionSwitched" ENUM  "AccOn","IG1On","IG2On","NoMsgTxTiming";
BA_DEF_DEF_REL_ "SC_Verification" "Yes";
BA_DEF_DEF_  "SCP_FreshnessValueTxLength" 4;
BA_DEF_DEF_  "SCP_FreshnessValueLength" 48;
BA_DEF_DEF_  "SCP_DataId" 0;
BA_DEF_DEF_  "SCP_AuthInfoTxLength" 28;
BA_DEF_DEF_  "SC_Message" "No";
BA_DEF_DEF_  "CANFD_BRS" "1";
BA_DEF_DEF_  "VFrameFormat" "ExtendedCAN_FD";
BA_DEF_DEF_  "DiagRequest" "No";
BA_DEF_DEF_  "DiagResponse" "No";
BA_DEF_DEF_  "DiagState" "No";
BA_DEF_DEF_  "DiagConnection" 0;
BA_DEF_DEF_  "GenMsgCycleTime" 0;
BA_DEF_DEF_  "GenMsgCycleTimeFast" 0;
BA_DEF_DEF_  "GenMsgDelayTime" 20;
BA_DEF_DEF_  "GenMsgILSupport" "Yes";
BA_DEF_DEF_  "GenMsgNrOfRepetition" 0;
BA_DEF_DEF_  "GenMsgSendType" "NoMsgSendType";
BA_DEF_DEF_  "GenSigSendType" "NoSigSendType";
BA_DEF_DEF_  "GenSigStartValue" 0;
BA_DEF_DEF_  "GenSigTimeoutTime_CGW" 5000;
BA_DEF_DEF_  "GenSigTimeoutTime_ADU" 5000;
BA_DEF_DEF_  "NetworkInitialization" "No";
BA_DEF_DEF_  "GenSigEnvVarType" "undef";
BA_DEF_DEF_  "NWM-WakeupAllowed" "No";
BA_DEF_DEF_  "NmAsrMessage" "No";
BA_DEF_DEF_  "GenMsgTxConditionAccOn" "No";
BA_DEF_DEF_  "GenMsgTxConditionIg1On" "No";
BA_DEF_DEF_  "GenMsgTxConditionPlusBOn" "No";
BA_DEF_DEF_  "GenSigInvalidValue" 0;
BA_DEF_DEF_  "CANoeMsgTxTimingIgnitionSwitched" "NoMsgTxTiming";
BA_ "GenMsgSendType" BO_ 597 5;
BA_ "GenMsgCycleTime" BO_ 597 100;
BA_ "VFrameFormat" BO_ 597 14;
BA_ "GenMsgSendType" BO_ 593 5;
BA_ "GenMsgCycleTime" BO_ 593 20;
BA_ "GenMsgDelayTime" BO_ 593 19;
BA_ "VFrameFormat" BO_ 593 14;
BA_ "GenMsgSendType" BO_ 592 0;
BA_ "GenMsgCycleTime" BO_ 592 20;
BA_ "GenMsgDelayTime" BO_ 592 0;
BA_ "VFrameFormat" BO_ 592 14;
BA_ "GenMsgSendType" BO_ 591 5;
BA_ "GenMsgCycleTime" BO_ 591 1000;
BA_ "VFrameFormat" BO_ 591 14;
BA_ "GenMsgSendType" BO_ 590 5;
BA_ "SC_Message" BO_ 590 1;
BA_ "SCP_DataId" BO_ 590 590;
BA_ "GenMsgCycleTime" BO_ 590 150;
BA_ "VFrameFormat" BO_ 590 14;
BA_ "GenMsgSendType" BO_ 588 0;
BA_ "GenMsgCycleTime" BO_ 588 100;
BA_ "VFrameFormat" BO_ 588 14;
BA_ "GenMsgSendType" BO_ 587 5;
BA_ "GenMsgCycleTime" BO_ 587 100;
BA_ "VFrameFormat" BO_ 587 14;
BA_ "GenMsgSendType" BO_ 586 0;
BA_ "GenMsgCycleTime" BO_ 586 100;
BA_ "VFrameFormat" BO_ 586 14;
BA_ "GenMsgSendType" BO_ 585 0;
BA_ "GenMsgCycleTime" BO_ 585 100;
BA_ "VFrameFormat" BO_ 585 14;
BA_ "GenMsgSendType" BO_ 579 0;
BA_ "GenMsgCycleTime" BO_ 579 50;
BA_ "VFrameFormat" BO_ 579 14;
BA_ "GenMsgSendType" BO_ 552 0;
BA_ "GenMsgCycleTime" BO_ 552 20;
BA_ "GenMsgDelayTime" BO_ 552 0;
BA_ "VFrameFormat" BO_ 552 14;
BA_ "GenMsgSendType" BO_ 548 0;
BA_ "GenMsgCycleTime" BO_ 548 20;
BA_ "GenMsgDelayTime" BO_ 548 0;
BA_ "VFrameFormat" BO_ 548 14;
BA_ "GenMsgSendType" BO_ 544 0;
BA_ "GenMsgCycleTime" BO_ 544 300;
BA_ "VFrameFormat" BO_ 544 14;
BA_ "GenMsgSendType" BO_ 542 0;
BA_ "GenMsgCycleTime" BO_ 542 100;
BA_ "VFrameFormat" BO_ 542 14;
BA_ "GenMsgSendType" BO_ 541 0;
BA_ "GenMsgCycleTime" BO_ 541 100;
BA_ "VFrameFormat" BO_ 541 14;
BA_ "GenMsgSendType" BO_ 540 5;
BA_ "GenMsgCycleTime" BO_ 540 1000;
BA_ "VFrameFormat" BO_ 540 14;
BA_ "GenMsgSendType" BO_ 537 0;
BA_ "GenMsgCycleTime" BO_ 537 20;
BA_ "GenMsgDelayTime" BO_ 537 0;
BA_ "VFrameFormat" BO_ 537 14;
BA_ "GenMsgSendType" BO_ 533 0;
BA_ "GenMsgCycleTime" BO_ 533 10;
BA_ "GenMsgDelayTime" BO_ 533 0;
BA_ "VFrameFormat" BO_ 533 14;
BA_ "GenMsgSendType" BO_ 526 0;
BA_ "GenMsgCycleTime" BO_ 526 50;
BA_ "VFrameFormat" BO_ 526 14;
BA_ "GenMsgSendType" BO_ 520 0;
BA_ "SC_Message" BO_ 520 1;
BA_ "SCP_DataId" BO_ 520 520;
BA_ "GenMsgCycleTime" BO_ 520 20;
BA_ "GenMsgDelayTime" BO_ 520 0;
BA_ "VFrameFormat" BO_ 520 14;
BA_ "GenMsgSendType" BO_ 508 0;
BA_ "SC_Message" BO_ 508 1;
BA_ "SCP_DataId" BO_ 508 508;
BA_ "GenMsgCycleTime" BO_ 508 30;
BA_ "VFrameFormat" BO_ 508 14;
BA_ "GenMsgSendType" BO_ 505 0;
BA_ "GenMsgCycleTime" BO_ 505 20;
BA_ "GenMsgDelayTime" BO_ 505 0;
BA_ "VFrameFormat" BO_ 505 14;
BA_ "GenMsgSendType" BO_ 357 0;
BA_ "GenMsgCycleTime" BO_ 357 10;
BA_ "GenMsgDelayTime" BO_ 357 0;
BA_ "NetworkInitialization" BO_ 357 1;
BA_ "VFrameFormat" BO_ 357 14;
BA_ "GenMsgSendType" BO_ 253 5;
BA_ "GenMsgCycleTime" BO_ 253 20;
BA_ "GenMsgDelayTime" BO_ 253 19;
BA_ "NetworkInitialization" BO_ 253 1;
BA_ "VFrameFormat" BO_ 253 14;
BA_ "GenMsgSendType" BO_ 218 0;
BA_ "GenMsgCycleTime" BO_ 218 24;
BA_ "VFrameFormat" BO_ 218 14;
BA_ "GenMsgSendType" BO_ 192 5;
BA_ "GenMsgCycleTime" BO_ 192 200;
BA_ "VFrameFormat" BO_ 192 14;
BA_ "GenMsgSendType" BO_ 159 5;
BA_ "GenMsgCycleTime" BO_ 159 200;
BA_ "VFrameFormat" BO_ 159 14;
BA_ "GenMsgSendType" BO_ 154 5;
BA_ "GenMsgCycleTime" BO_ 154 100;
BA_ "VFrameFormat" BO_ 154 14;
BA_ "GenMsgSendType" BO_ 153 5;
BA_ "GenMsgCycleTime" BO_ 153 100;
BA_ "VFrameFormat" BO_ 153 14;
BA_ "GenMsgSendType" BO_ 152 0;
BA_ "SC_Message" BO_ 152 1;
BA_ "SCP_DataId" BO_ 152 152;
BA_ "GenMsgCycleTime" BO_ 152 20;
BA_ "GenMsgDelayTime" BO_ 152 0;
BA_ "VFrameFormat" BO_ 152 14;
BA_ "GenMsgSendType" BO_ 150 5;
BA_ "GenMsgCycleTime" BO_ 150 100;
BA_ "VFrameFormat" BO_ 150 14;
BA_ "GenMsgSendType" BO_ 148 5;
BA_ "GenMsgCycleTime" BO_ 148 100;
BA_ "VFrameFormat" BO_ 148 14;
BA_ "GenMsgSendType" BO_ 145 5;
BA_ "GenMsgCycleTime" BO_ 145 100;
BA_ "VFrameFormat" BO_ 145 14;
BA_ "GenMsgSendType" BO_ 139 5;
BA_ "SC_Message" BO_ 139 1;
BA_ "SCP_DataId" BO_ 139 139;
BA_ "GenMsgCycleTime" BO_ 139 25;
BA_ "VFrameFormat" BO_ 139 14;
BA_ "GenMsgSendType" BO_ 136 0;
BA_ "GenMsgCycleTime" BO_ 136 20;
BA_ "GenMsgDelayTime" BO_ 136 0;
BA_ "VFrameFormat" BO_ 136 14;
BA_ "GenMsgSendType" BO_ 135 0;
BA_ "GenMsgCycleTime" BO_ 135 12;
BA_ "GenMsgDelayTime" BO_ 135 0;
BA_ "VFrameFormat" BO_ 135 14;
BA_ "GenMsgSendType" BO_ 133 0;
BA_ "SC_Message" BO_ 133 1;
BA_ "SCP_DataId" BO_ 133 133;
BA_ "GenMsgCycleTime" BO_ 133 25;
BA_ "VFrameFormat" BO_ 133 14;
BA_ "GenMsgSendType" BO_ 132 0;
BA_ "GenMsgCycleTime" BO_ 132 12;
BA_ "GenMsgDelayTime" BO_ 132 0;
BA_ "VFrameFormat" BO_ 132 14;
BA_ "GenMsgSendType" BO_ 130 0;
BA_ "GenMsgCycleTime" BO_ 130 10;
BA_ "GenMsgDelayTime" BO_ 130 0;
BA_ "VFrameFormat" BO_ 130 14;
BA_ "GenMsgSendType" BO_ 129 0;
BA_ "SC_Message" BO_ 129 1;
BA_ "SCP_DataId" BO_ 129 129;
BA_ "GenMsgCycleTime" BO_ 129 10;
BA_ "GenMsgDelayTime" BO_ 129 0;
BA_ "VFrameFormat" BO_ 129 14;
BA_ "GenMsgSendType" BO_ 126 0;
BA_ "GenMsgCycleTime" BO_ 126 10;
BA_ "GenMsgDelayTime" BO_ 126 0;
BA_ "VFrameFormat" BO_ 126 14;
BA_ "GenMsgSendType" BO_ 116 0;
BA_ "SC_Message" BO_ 116 1;
BA_ "SCP_DataId" BO_ 116 116;
BA_ "GenMsgCycleTime" BO_ 116 20;
BA_ "GenMsgDelayTime" BO_ 116 0;
BA_ "VFrameFormat" BO_ 116 14;
BA_ "GenMsgSendType" BO_ 80 5;
BA_ "GenMsgCycleTime" BO_ 80 100;
BA_ "VFrameFormat" BO_ 80 14;
BA_ "GenMsgSendType" BO_ 48 0;
BA_ "SC_Message" BO_ 48 1;
BA_ "SCP_DataId" BO_ 48 48;
BA_ "GenMsgCycleTime" BO_ 48 8;
BA_ "GenMsgDelayTime" BO_ 48 0;
BA_ "VFrameFormat" BO_ 48 14;
BA_ "GenMsgSendType" BO_ 38 1;
BA_ "SC_Message" BO_ 38 1;
BA_ "SCP_DataId" BO_ 38 38;
BA_ "GenMsgDelayTime" BO_ 38 0;
BA_ "VFrameFormat" BO_ 38 14;
BA_ "GenMsgSendType" BO_ 32 0;
BA_ "SC_Message" BO_ 32 1;
BA_ "SCP_FreshnessValueLength" BO_ 32 40;
BA_ "SCP_FreshnessValueTxLength" BO_ 32 36;
BA_ "SCP_DataId" BO_ 32 32;
BA_ "GenMsgCycleTime" BO_ 32 100;
BA_ "VFrameFormat" BO_ 32 14;
BA_ "GenMsgSendType" BO_ 28 1;
BA_ "VFrameFormat" BO_ 28 14;
BA_ "GenMsgSendType" BO_ 27 1;
BA_ "VFrameFormat" BO_ 27 14;
BA_ "GenMsgSendType" BO_ 26 1;
BA_ "VFrameFormat" BO_ 26 14;
BA_ "GenMsgSendType" BO_ 25 1;
BA_ "VFrameFormat" BO_ 25 14;
BA_ "GenMsgSendType" BO_ 24 1;
BA_ "VFrameFormat" BO_ 24 14;
BA_ "GenMsgSendType" BO_ 23 1;
BA_ "VFrameFormat" BO_ 23 14;
BA_ "GenMsgSendType" BO_ 22 1;
BA_ "VFrameFormat" BO_ 22 14;
BA_ "GenMsgSendType" BO_ 21 1;
BA_ "VFrameFormat" BO_ 21 14;
BA_ "GenMsgSendType" BO_ 20 1;
BA_ "VFrameFormat" BO_ 20 14;
BA_ "GenMsgSendType" BO_ 19 1;
BA_ "VFrameFormat" BO_ 19 14;
BA_ "GenMsgSendType" BO_ 18 1;
BA_ "VFrameFormat" BO_ 18 14;
BA_ "GenMsgSendType" BO_ 17 1;
BA_ "VFrameFormat" BO_ 17 14;
BA_ "GenMsgSendType" BO_ 16 1;
BA_ "GenMsgTxConditionIg1On" BO_ 593 1;
BA_ "GenMsgTxConditionIg1On" BO_ 591 1;
BA_ "GenMsgTxConditionIg1On" BO_ 590 1;
BA_ "GenMsgTxConditionIg1On" BO_ 588 1;
BA_ "GenMsgTxConditionIg1On" BO_ 587 1;
BA_ "GenMsgTxConditionIg1On" BO_ 586 1;
BA_ "GenMsgTxConditionIg1On" BO_ 585 1;
BA_ "GenMsgTxConditionIg1On" BO_ 579 1;
BA_ "GenMsgTxConditionIg1On" BO_ 544 1;
BA_ "GenMsgTxConditionIg1On" BO_ 540 1;
BA_ "GenMsgTxConditionIg1On" BO_ 526 1;
BA_ "GenMsgTxConditionIg1On" BO_ 508 1;
BA_ "GenMsgTxConditionIg1On" BO_ 505 1;
BA_ "GenMsgTxConditionIg1On" BO_ 218 1;
BA_ "GenMsgTxConditionIg1On" BO_ 192 1;
BA_ "GenMsgTxConditionIg1On" BO_ 139 1;
BA_ "GenMsgTxConditionIg1On" BO_ 136 1;
BA_ "GenMsgTxConditionIg1On" BO_ 135 1;
BA_ "GenMsgTxConditionIg1On" BO_ 133 1;
BA_ "GenMsgTxConditionIg1On" BO_ 132 1;
BA_ "GenMsgTxConditionIg1On" BO_ 130 1;
BA_ "GenMsgTxConditionIg1On" BO_ 129 1;
BA_ "GenMsgTxConditionIg1On" BO_ 48 1;
BA_ "GenMsgTxConditionIg1On" BO_ 38 1;
BA_ "GenMsgTxConditionIg1On" BO_ 28 1;
BA_ "GenMsgTxConditionIg1On" BO_ 27 1;
BA_ "GenMsgTxConditionIg1On" BO_ 26 1;
BA_ "GenMsgTxConditionIg1On" BO_ 25 1;
BA_ "GenMsgTxConditionIg1On" BO_ 24 1;
BA_ "GenMsgTxConditionIg1On" BO_ 23 1;
BA_ "GenMsgTxConditionIg1On" BO_ 22 1;
BA_ "GenMsgTxConditionIg1On" BO_ 21 1;
BA_ "GenMsgTxConditionIg1On" BO_ 20 1;
BA_ "GenMsgTxConditionIg1On" BO_ 19 1;
BA_ "GenMsgTxConditionIg1On" BO_ 18 1;
BA_ "GenMsgTxConditionIg1On" BO_ 17 1;
BA_ "GenMsgTxConditionIg1On" BO_ 16 1;
BA_ "GenMsgTxConditionPlusBOn" BO_ 597 1;
BA_ "GenMsgTxConditionPlusBOn" BO_ 592 1;
BA_ "GenMsgTxConditionPlusBOn" BO_ 552 1;
BA_ "GenMsgTxConditionPlusBOn" BO_ 548 1;
BA_ "GenMsgTxConditionPlusBOn" BO_ 542 1;
BA_ "GenMsgTxConditionPlusBOn" BO_ 541 1;
BA_ "GenMsgTxConditionPlusBOn" BO_ 537 1;
BA_ "GenMsgTxConditionPlusBOn" BO_ 533 1;
BA_ "GenMsgTxConditionPlusBOn" BO_ 520 1;
BA_ "GenMsgTxConditionPlusBOn" BO_ 357 1;
BA_ "GenMsgTxConditionPlusBOn" BO_ 253 1;
BA_ "GenMsgTxConditionPlusBOn" BO_ 159 1;
BA_ "GenMsgTxConditionPlusBOn" BO_ 154 1;
BA_ "GenMsgTxConditionPlusBOn" BO_ 153 1;
BA_ "GenMsgTxConditionPlusBOn" BO_ 152 1;
BA_ "GenMsgTxConditionPlusBOn" BO_ 150 1;
BA_ "GenMsgTxConditionPlusBOn" BO_ 148 1;
BA_ "GenMsgTxConditionPlusBOn" BO_ 145 1;
BA_ "GenMsgTxConditionPlusBOn" BO_ 126 1;
BA_ "GenMsgTxConditionPlusBOn" BO_ 116 1;
BA_ "GenMsgTxConditionPlusBOn" BO_ 80 1;
BA_ "GenMsgTxConditionPlusBOn" BO_ 32 1;
BA_ "VFrameFormat" BO_ 16 14;
BA_ "GenSigSendType" SG_ 597 HMI_Request_ADU_CatS1_MACTx 3;
BA_ "GenSigSendType" SG_ 597 HMI_Request_ADU_CatS1_FVTx 3;
BA_ "GenSigSendType" SG_ 597 HMI_Request_ADU_CatS1_No_Cs 3;
BA_ "GenSigSendType" SG_ 597 HMI_Request_ADU_CatS1_No_Cnt 3;
BA_ "GenSigSendType" SG_ 597 HMI_Status_TSROffMute_Rq 3;
BA_ "GenSigSendType" SG_ 597 HMI_Status_CBDA5_Rq 3;
BA_ "GenSigSendType" SG_ 597 HMI_Status_CBDA4_Rq 3;
BA_ "GenSigSendType" SG_ 597 HMI_Status_BSM6_Rq 3;
BA_ "GenSigSendType" SG_ 597 HMI_Status_BSM5_Rq 3;
BA_ "GenSigSendType" SG_ 597 HMI_Status_DAS2_Rq 3;
BA_ "GenSigSendType" SG_ 597 HMI_Status_DAS1_Rq 3;
BA_ "GenSigSendType" SG_ 597 HMI_Status_TSR3_Rq 3;
BA_ "GenSigSendType" SG_ 597 HMI_Status_TSR2_Rq 3;
BA_ "GenSigSendType" SG_ 597 HMI_Status_TSR1_Rq 3;
BA_ "GenSigSendType" SG_ 597 HMI_Status_LKA10_Rq 3;
BA_ "GenSigSendType" SG_ 597 HMI_Status_LKA9_Rq 3;
BA_ "GenSigSendType" SG_ 597 HMI_Status_LKA8_Rq 3;
BA_ "GenSigSendType" SG_ 597 HMI_Status_LKA7_Rq 3;
BA_ "GenSigSendType" SG_ 597 HMI_Status_LKA6_Rq 3;
BA_ "GenSigSendType" SG_ 597 HMI_Status_LKA5_Rq 3;
BA_ "GenSigSendType" SG_ 597 HMI_Status_LKA4_Rq 3;
BA_ "GenSigSendType" SG_ 597 HMI_Status_LKA3_Rq 3;
BA_ "GenSigSendType" SG_ 597 HMI_Status_LKA2_Rq 3;
BA_ "GenSigSendType" SG_ 597 HMI_Status_LKA1_Rq 3;
BA_ "GenSigSendType" SG_ 597 HMI_Status_ACCASCISA2_Rq 3;
BA_ "GenSigSendType" SG_ 597 HMI_Status_ACCASCISA1_Rq 3;
BA_ "GenSigSendType" SG_ 597 HMI_Status_ACCASCISA_OVSP_Rq 3;
BA_ "GenSigSendType" SG_ 597 HMI_Status_ISA2_Rq 3;
BA_ "GenSigSendType" SG_ 597 HMI_Status_ISA1_Rq 3;
BA_ "GenSigSendType" SG_ 597 HMI_Status_ACCASC4_Rq 3;
BA_ "GenSigSendType" SG_ 597 HMI_Status_ACCASC3_Rq 3;
BA_ "GenSigSendType" SG_ 597 HMI_Status_ACCASC2_Rq 3;
BA_ "GenSigSendType" SG_ 597 HMI_Status_ACCASC1_Rq 3;
BA_ "GenSigSendType" SG_ 597 HMI_Status_ASC3_Rq 3;
BA_ "GenSigSendType" SG_ 597 HMI_Status_ASC2_Rq 3;
BA_ "GenSigSendType" SG_ 597 HMI_Status_ASC1_Rq 3;
BA_ "GenSigSendType" SG_ 597 HMI_Status_DAS3_Rq 3;
BA_ "GenSigSendType" SG_ 597 HMI_Status_ACC12_Rq 3;
BA_ "GenSigSendType" SG_ 597 HMI_Status_ACC11_Rq 3;
BA_ "GenSigSendType" SG_ 597 HMI_Status_ACC10_Rq 3;
BA_ "GenSigSendType" SG_ 597 HMI_Status_ACC9_Rq 3;
BA_ "GenSigSendType" SG_ 597 HMI_Status_ACC8_Rq 3;
BA_ "GenSigSendType" SG_ 597 HMI_Status_ACC7_Rq 3;
BA_ "GenSigSendType" SG_ 597 HMI_Status_ACC6_Rq 3;
BA_ "GenSigSendType" SG_ 597 HMI_Status_ACC5_Rq 3;
BA_ "GenSigSendType" SG_ 597 HMI_Status_ACC4_Rq 3;
BA_ "GenSigSendType" SG_ 597 HMI_Status_ACC3_Rq 3;
BA_ "GenSigSendType" SG_ 597 HMI_Status_ACC2_Rq 3;
BA_ "GenSigSendType" SG_ 597 HMI_Status_ACC1_Rq 3;
BA_ "GenSigSendType" SG_ 597 HMI_Status_RCTA2_Rq 3;
BA_ "GenSigSendType" SG_ 597 HMI_Status_RCTA1_Rq 3;
BA_ "GenSigSendType" SG_ 597 HMI_Status_RPTB2_Rq 3;
BA_ "GenSigSendType" SG_ 597 HMI_Status_RCTB1_Rq 3;
BA_ "GenSigSendType" SG_ 597 HMI_Status_RPTC2_Rq 3;
BA_ "GenSigSendType" SG_ 597 HMI_Status_RPTC1_Rq 3;
BA_ "GenSigSendType" SG_ 597 HMI_Status_PAEB2_Rq 3;
BA_ "GenSigSendType" SG_ 597 HMI_Status_PAEB1_Rq 3;
BA_ "GenSigSendType" SG_ 597 HMI_Status_OCP8_Rq 3;
BA_ "GenSigSendType" SG_ 597 HMI_Status_OCP7_Rq 3;
BA_ "GenSigSendType" SG_ 597 HMI_Status_OCP6_Rq 3;
BA_ "GenSigSendType" SG_ 597 HMI_Status_OCP5_Rq 3;
BA_ "GenSigSendType" SG_ 597 HMI_Status_OCP4_Rq 3;
BA_ "GenSigSendType" SG_ 597 HMI_Status_OCP3_Rq 3;
BA_ "GenSigSendType" SG_ 597 HMI_Status_OCP2_Rq 3;
BA_ "GenSigSendType" SG_ 597 HMI_Status_OCP1_Rq 3;
BA_ "GenSigSendType" SG_ 597 HMI_Status_CBDA3_Rq 3;
BA_ "GenSigSendType" SG_ 597 HMI_Status_CBDA2_Rq 3;
BA_ "GenSigSendType" SG_ 597 HMI_Status_CBDA1_Rq 3;
BA_ "GenSigSendType" SG_ 597 HMI_Status_BSM4_Rq 3;
BA_ "GenSigSendType" SG_ 597 HMI_Status_BSM3_Rq 3;
BA_ "GenSigSendType" SG_ 597 HMI_Status_BSM2_Rq 3;
BA_ "GenSigSendType" SG_ 597 HMI_Status_BSM1_Rq 3;
BA_ "GenSigSendType" SG_ 597 HMI_Status_BSP8_Rq 3;
BA_ "GenSigSendType" SG_ 597 HMI_Status_BSP7_Rq 3;
BA_ "GenSigSendType" SG_ 597 HMI_Status_BSP6_Rq 3;
BA_ "GenSigSendType" SG_ 597 HMI_Status_BSP5_Rq 3;
BA_ "GenSigSendType" SG_ 597 HMI_Status_BSP4_Rq 3;
BA_ "GenSigSendType" SG_ 597 HMI_Status_BSP3_Rq 3;
BA_ "GenSigSendType" SG_ 597 HMI_Status_BSP2_Rq 3;
BA_ "GenSigSendType" SG_ 597 HMI_Status_BSP1_Rq 3;
BA_ "GenSigSendType" SG_ 597 HMI_Status_RDPRDW4_Rq 3;
BA_ "GenSigSendType" SG_ 597 HMI_Status_RDPRDW3_Rq 3;
BA_ "GenSigSendType" SG_ 597 HMI_Status_RDPRDW2_Rq 3;
BA_ "GenSigSendType" SG_ 597 HMI_Status_RDPRDW1_Rq 3;
BA_ "GenSigSendType" SG_ 597 HMI_Status_LDW5_Rq 3;
BA_ "GenSigSendType" SG_ 597 HMI_Status_LDW4_Rq 3;
BA_ "GenSigSendType" SG_ 597 HMI_Status_LDW3_Rq 3;
BA_ "GenSigSendType" SG_ 597 HMI_Status_LDW2_Rq 3;
BA_ "GenSigSendType" SG_ 597 HMI_Status_LDW1_Rq 3;
BA_ "GenSigSendType" SG_ 597 HMI_Status_LDP4_Rq 3;
BA_ "GenSigSendType" SG_ 597 HMI_Status_LDP3_Rq 3;
BA_ "GenSigSendType" SG_ 597 HMI_Status_LDP2_Rq 3;
BA_ "GenSigSendType" SG_ 597 HMI_Status_LDP1_Rq 3;
BA_ "GenSigSendType" SG_ 597 HMI_Status_FCTA4_Rq 3;
BA_ "GenSigSendType" SG_ 597 HMI_Status_FCTA3_Rq 3;
BA_ "GenSigSendType" SG_ 597 HMI_Status_FCTA2_Rq 3;
BA_ "GenSigSendType" SG_ 597 HMI_Status_FCTA1_Rq 3;
BA_ "GenSigSendType" SG_ 597 HMI_Status_CTB5_Rq 3;
BA_ "GenSigSendType" SG_ 597 HMI_Status_CTB4_Rq 3;
BA_ "GenSigSendType" SG_ 597 HMI_Status_CTB3_Rq 3;
BA_ "GenSigSendType" SG_ 597 HMI_Status_CTB2_Rq 3;
BA_ "GenSigSendType" SG_ 597 HMI_Status_CTB1_Rq 3;
BA_ "GenSigSendType" SG_ 597 HMI_Status_PTC2_Rq 3;
BA_ "GenSigSendType" SG_ 597 HMI_Status_PTC1_Rq 3;
BA_ "GenSigSendType" SG_ 597 HMI_Status_AEBFCW2_Rq 3;
BA_ "GenSigSendType" SG_ 597 HMI_Status_AEBFCW1_Rq 3;
BA_ "GenSigSendType" SG_ 593 ID41B_No_Cs 3;
BA_ "GenSigSendType" SG_ 593 AMBDS_ST 3;
BA_ "GenSigSendType" SG_ 593 AMBDS_VL 3;
BA_ "GenSigSendType" SG_ 593 AMBTE_ST 3;
BA_ "GenSigSendType" SG_ 593 AMBTE_VL 3;
BA_ "GenSigSendType" SG_ 593 RDYIND 3;
BA_ "GenSigSendType" SG_ 593 GEAR_MET 3;
BA_ "GenSigSendType" SG_ 593 THF 3;
BA_ "GenSigSendType" SG_ 593 B_ISPTM 3;
BA_ "GenSigSendType" SG_ 593 IGP_PT2 3;
BA_ "GenSigSendType" SG_ 593 B_B 3;
BA_ "GenSigSendType" SG_ 593 B_LO 3;
BA_ "GenSigSendType" SG_ 593 B_2 3;
BA_ "GenSigSendType" SG_ 593 B_3 3;
BA_ "GenSigSendType" SG_ 593 B_4 3;
BA_ "GenSigSendType" SG_ 593 B_D 3;
BA_ "GenSigSendType" SG_ 593 B_N 3;
BA_ "GenSigSendType" SG_ 593 B_R 3;
BA_ "GenSigSendType" SG_ 593 B_P 3;
BA_ "GenSigStartValue" SG_ 591 TOLER_A 63;
BA_ "GenSigInvalidValue" SG_ 591 TOLER_A 63;
BA_ "GenSigSendType" SG_ 591 PKSB_HSW 3;
BA_ "GenSigSendType" SG_ 591 PKSBVLD 3;
BA_ "GenSigSendType" SG_ 591 APPCSVLD 3;
BA_ "GenSigSendType" SG_ 591 APPCSSW 3;
BA_ "GenSigSendType" SG_ 591 B_CCOUNT 3;
BA_REL_ "SC_Verification" BU_SG_REL_ ADU SG_ 590 KZK24E_MACTx 0;
BA_REL_ "SC_Verification" BU_SG_REL_ ADU SG_ 590 FV24E_FVTx 0;
BA_ "GenSigSendType" SG_ 590 CCCOUNT 3;
BA_ "GenSigSendType" SG_ 590 TSSMD2_M 3;
BA_ "GenSigStartValue" SG_ 590 TSSMD2_M 1;
BA_ "GenSigSendType" SG_ 590 TSSMD1_M 3;
BA_ "GenSigStartValue" SG_ 590 TSSMD1_M 1;
BA_ "GenSigSendType" SG_ 590 LTM_M 3;
BA_ "GenSigStartValue" SG_ 590 LTM_M 1;
BA_ "GenSigSendType" SG_ 590 CANCEL_M 3;
BA_ "GenSigStartValue" SG_ 590 CANCEL_M 1;
BA_ "GenSigSendType" SG_ 590 FLICK_PLUS_M 3;
BA_ "GenSigStartValue" SG_ 590 FLICK_PLUS_M 1;
BA_ "GenSigSendType" SG_ 590 FLICK_MINUS_M 3;
BA_ "GenSigStartValue" SG_ 590 FLICK_MINUS_M 1;
BA_ "GenSigSendType" SG_ 590 SET_PLUS_M 3;
BA_ "GenSigStartValue" SG_ 590 SET_PLUS_M 1;
BA_ "GenSigSendType" SG_ 590 SET_MINUS_M 3;
BA_ "GenSigStartValue" SG_ 590 SET_MINUS_M 1;
BA_ "GenSigSendType" SG_ 590 RES_M 3;
BA_ "GenSigStartValue" SG_ 590 RES_M 1;
BA_ "GenSigSendType" SG_ 590 TSSMD2 3;
BA_ "GenSigSendType" SG_ 590 TSSMD1 3;
BA_ "GenSigSendType" SG_ 590 LTM 3;
BA_ "GenSigSendType" SG_ 590 CANCEL 3;
BA_ "GenSigSendType" SG_ 590 FLICK_PLUS 3;
BA_ "GenSigSendType" SG_ 590 FLICK_MINUS 3;
BA_ "GenSigSendType" SG_ 590 SET_PLUS 3;
BA_ "GenSigSendType" SG_ 590 SET_MINUS 3;
BA_ "GenSigSendType" SG_ 590 RES 3;
BA_ "GenSigStartValue" SG_ 588 OTHFRILL 1048574;
BA_ "GenSigSendType" SG_ 587 OTHLANE 3;
BA_ "GenSigStartValue" SG_ 587 OTHLDIS 127;
BA_ "GenSigStartValue" SG_ 587 OTHCOND 127;
BA_ "GenSigStartValue" SG_ 587 OTHFALD 127;
BA_ "GenSigStartValue" SG_ 552 TransmChangeLeverPosition 14;
BA_ "GenSigTimeoutTime_ADU" SG_ 552 TransmChangeLeverPosition 60;
BA_ "GenSigInvalidValue" SG_ 552 TransmChangeLeverPosition 15;
BA_ "GenSigStartValue" SG_ 552 ShiftrPos_D_Qf 1;
BA_ "GenSigInvalidValue" SG_ 552 TransmParking_D_Act 7;
BA_ "GenSigStartValue" SG_ 552 DispAtLvrPos_D_Rq 14;
BA_ "GenSigInvalidValue" SG_ 552 DispAtLvrPos_D_Rq 15;
BA_ "GenSigStartValue" SG_ 552 DispGearPos_D_Rq 14;
BA_ "GenSigInvalidValue" SG_ 552 DispGearPos_D_Rq 15;
BA_ "GenSigStartValue" SG_ 548 APPSPCER 1;
BA_ "GenSigStartValue" SG_ 548 EPBSW 3;
BA_ "GenSigStartValue" SG_ 548 EPBLOCK 3;
BA_ "GenSigSendType" SG_ 540 Y2_COORD 1;
BA_ "GenSigSendType" SG_ 540 SW_AP 3;
BA_ "GenSigSendType" SG_ 540 CD_SIZE 3;
BA_ "GenSigSendType" SG_ 540 X2_COORD 1;
BA_ "GenSigSendType" SG_ 540 MIC_POS 3;
BA_ "GenSigSendType" SG_ 540 VR_STATE 3;
BA_ "GenSigSendType" SG_ 540 Y_COORD 1;
BA_ "GenSigSendType" SG_ 540 CUST_APP 3;
BA_ "GenSigSendType" SG_ 540 CUST_TRA 3;
BA_ "GenSigSendType" SG_ 540 SW_PVM 3;
BA_ "GenSigSendType" SG_ 540 MMD_MODE 3;
BA_ "GenSigSendType" SG_ 540 DN_DISP 3;
BA_ "GenSigSendType" SG_ 540 X_COORD 1;
BA_ "GenSigSendType" SG_ 540 MM_RESET 3;
BA_ "GenSigSendType" SG_ 540 DI_MODE 3;
BA_ "GenSigSendType" SG_ 540 CMD_MODE 3;
BA_ "GenSigSendType" SG_ 540 IRQ_MM 3;
BA_ "GenSigSendType" SG_ 540 CC_MODE 3;
BA_ "GenSigSendType" SG_ 540 AVN_ON 3;
BA_ "GenSigTimeoutTime_ADU" SG_ 537 VehVActlBrk2_No_Cs 60;
BA_ "GenSigTimeoutTime_ADU" SG_ 537 VehVActlBrk2_No_Cnt 60;
BA_ "GenSigTimeoutTime_ADU" SG_ 537 WhlRotatRl_Direction 60;
BA_ "GenSigTimeoutTime_ADU" SG_ 537 WhlRotatRr_Direction 60;
BA_ "GenSigTimeoutTime_ADU" SG_ 537 WhlRotatFl_Direction 60;
BA_ "GenSigTimeoutTime_ADU" SG_ 537 WhlRotatFr_Direction 60;
BA_ "GenSigTimeoutTime_ADU" SG_ 537 WhlRotatRl2_No_Cnt 60;
BA_ "GenSigTimeoutTime_ADU" SG_ 537 WhlRotatRr2_No_Cnt 60;
BA_ "GenSigTimeoutTime_ADU" SG_ 537 WhlRotatFl2_No_Cnt 60;
BA_ "GenSigTimeoutTime_ADU" SG_ 537 WhlRotatFr2_No_Cnt 60;
BA_ "GenSigStartValue" SG_ 533 RRwheelSpeed 65534;
BA_ "GenSigTimeoutTime_ADU" SG_ 533 RRwheelSpeed 30;
BA_ "GenSigInvalidValue" SG_ 533 RRwheelSpeed 65535;
BA_ "GenSigStartValue" SG_ 533 RLwheelSpeed 65534;
BA_ "GenSigTimeoutTime_ADU" SG_ 533 RLwheelSpeed 30;
BA_ "GenSigInvalidValue" SG_ 533 RLwheelSpeed 65535;
BA_ "GenSigStartValue" SG_ 533 FRwheelSpeed 65534;
BA_ "GenSigTimeoutTime_ADU" SG_ 533 FRwheelSpeed 30;
BA_ "GenSigInvalidValue" SG_ 533 FRwheelSpeed 65535;
BA_ "GenSigStartValue" SG_ 533 FLwheelSpeed 65534;
BA_ "GenSigTimeoutTime_ADU" SG_ 533 FLwheelSpeed 30;
BA_ "GenSigInvalidValue" SG_ 533 FLwheelSpeed 65535;
BA_REL_ "SC_Verification" BU_SG_REL_ ADU SG_ 520 DesiredTorqBrk_MACTx 0;
BA_REL_ "SC_Verification" BU_SG_REL_ ADU SG_ 520 DesiredTorqBrk_FVTx 0;
BA_ "GenSigTimeoutTime_ADU" SG_ 520 Abs_B_Falt 60;
BA_ "GenSigTimeoutTime_ADU" SG_ 520 TsaCtlActv_B_Actl 60;
BA_ "GenSigTimeoutTime_ADU" SG_ 520 StabCtlBrkActv_B_Actl 60;
BA_ "GenSigTimeoutTime_ADU" SG_ 520 BrkAsst_B_Actl 60;
BA_REL_ "SC_Verification" BU_SG_REL_ ADU SG_ 508 KZK1FC_MACTx 0;
BA_REL_ "SC_Verification" BU_SG_REL_ ADU SG_ 508 FV1FC_FVTx 0;
BA_ "GenSigStartValue" SG_ 508 ADSBKINV 1;
BA_ "GenSigInvalidValue" SG_ 505 B_PDLF 1;
BA_ "GenSigInvalidValue" SG_ 357 EngCltFlow_Cnt_Vlv 255;
BA_ "GenSigStartValue" SG_ 357 TrnAinTq_D_Qf1 1;
BA_ "GenSigStartValue" SG_ 357 HeaterCoreTeEst_D_Qf 1;
BA_ "GenSigStartValue" SG_ 357 ApedPosPcActl_D_Qf 1;
BA_ "GenSigTimeoutTime_ADU" SG_ 357 ApedPosPcActl_D_Qf 30;
BA_ "GenSigTimeoutTime_ADU" SG_ 357 ApedPos_Pc_ActlArb 30;
BA_ "GenSigInvalidValue" SG_ 357 EngAout_N_ReqTacho 8191;
BA_ "GenSigTimeoutTime_ADU" SG_ 357 EngAout_N_Actl 30;
BA_ "GenSigInvalidValue" SG_ 357 EngAout_N_Actl 8191;
BA_ "GenSigInvalidValue" SG_ 357 TrnTotTq_Rt_Est 65535;
BA_ "GenSigTimeoutTime_ADU" SG_ 357 GearRvrseActv_B_Actl 200;
BA_ "GenSigTimeoutTime_ADU" SG_ 357 BrkOnOffSwtch_D_Actl_2 30;
BA_ "GenSigInvalidValue" SG_ 357 AWDTrgt_I_Req_165 4095;
BA_ "GenSigSendType" SG_ 253 HEVIG_B_Actl 3;
BA_ "GenSigSendType" SG_ 253 IG_OnOff_PT 3;
BA_ "GenSigSendType" SG_ 253 EngCrank_Req 3;
BA_ "GenSigSendType" SG_ 253 ChgHiVoltCont_Req 3;
BA_ "GenSigSendType" SG_ 253 HiVoltCont_Req 3;
BA_ "GenSigSendType" SG_ 253 CDTHVANS 3;
BA_ "GenSigSendType" SG_ 253 Permit_Isolate_Detect 3;
BA_ "GenSigSendType" SG_ 253 Chrg_Enable 3;
BA_ "GenSigSendType" SG_ 253 Eng_Enable 3;
BA_ "GenSigSendType" SG_ 253 HiVolt_Enable 3;
BA_ "GenSigSendType" SG_ 253 CellBalance_Req 3;
BA_ "GenSigSendType" SG_ 253 CoastDownMode 3;
BA_ "GenSigSendType" SG_ 253 Discharge_Req 3;
BA_ "GenSigSendType" SG_ 253 BatteryHeater_On_Sig 3;
BA_ "GenSigSendType" SG_ 253 AirConditioner_On_Sig 3;
BA_ "GenSigSendType" SG_ 253 Supply_On_Sig 3;
BA_ "GenSigSendType" SG_ 253 Charge_On_Sig 3;
BA_ "GenSigSendType" SG_ 253 Ready_On_Sig 3;
BA_ "GenSigSendType" SG_ 253 GenStartStop_Req 3;
BA_ "GenSigSendType" SG_ 253 SupStartStop_Req 3;
BA_ "GenSigSendType" SG_ 253 ChgStartStop_Req 3;
BA_ "GenSigSendType" SG_ 253 DrvStartStop_Req 3;
BA_ "GenSigSendType" SG_ 253 EatcStartStop_Req 3;
BA_ "GenSigSendType" SG_ 253 EcuStartStop_Req 3;
BA_ "GenSigSendType" SG_ 253 Veh_State_Sig 3;
BA_ "GenSigSendType" SG_ 253 Veh_Mode_Sig 3;
BA_ "GenSigInvalidValue" SG_ 253 Clutch_Stroke 255;
BA_ "GenSigStartValue" SG_ 253 SISS_EngineState 1;
BA_ "GenSigStartValue" SG_ 253 Xev_Charge_Req_PCM 6;
BA_ "GenSigInvalidValue" SG_ 253 Xev_Charge_Req_PCM 7;
BA_ "GenSigStartValue" SG_ 253 PTGeneralWarn_Mirror 1;
BA_ "GenSigStartValue" SG_ 253 Drive_Mode_Towing_Req_PCM 2;
BA_ "GenSigInvalidValue" SG_ 253 Drive_Mode_Towing_Req_PCM 3;
BA_ "GenSigStartValue" SG_ 253 Drive_Mode_OffRoad_Req_PCM 2;
BA_ "GenSigInvalidValue" SG_ 253 Drive_Mode_OffRoad_Req_PCM 3;
BA_ "GenSigStartValue" SG_ 253 Drive_Mode_Sport_Req_PCM 2;
BA_ "GenSigInvalidValue" SG_ 253 Drive_Mode_Sport_Req_PCM 3;
BA_ "GenSigStartValue" SG_ 253 Drive_Mode_Normal_Req_PCM 2;
BA_ "GenSigInvalidValue" SG_ 253 Drive_Mode_Normal_Req_PCM 3;
BA_ "GenSigStartValue" SG_ 253 CrankingTime 2;
BA_ "GenSigStartValue" SG_ 253 Xev_Ev_Req_PCM 6;
BA_ "GenSigInvalidValue" SG_ 253 Xev_Ev_Req_PCM 7;
BA_ "GenSigTimeoutTime_ADU" SG_ 253 PowerSourceStatus 60;
BA_ "GenSigSendType" SG_ 192 Auto_XevNormal_Mode_D_Rq 3;
BA_ "GenSigSendType" SG_ 192 Not_Select_Xevmode_D_Rq 3;
BA_ "GenSigSendType" SG_ 192 Auto_Normal_Mode_D_Rq 3;
BA_ "GenSigSendType" SG_ 192 Not_Select_Drivemode_D_Rq 3;
BA_ "GenSigSendType" SG_ 192 Trailer_Connect_D_Rq 3;
BA_ "GenSigSendType" SG_ 192 Drive_Mode_List_Popup 3;
BA_ "GenSigSendType" SG_ 192 Xev_Mode_Charge_Permission 3;
BA_ "GenSigStartValue" SG_ 192 Xev_Mode_Charge_Permission 2;
BA_ "GenSigInvalidValue" SG_ 192 Xev_Mode_Charge_Permission 3;
BA_ "GenSigSendType" SG_ 192 Xev_Mode_Ev_Permission 3;
BA_ "GenSigStartValue" SG_ 192 Xev_Mode_Ev_Permission 2;
BA_ "GenSigInvalidValue" SG_ 192 Xev_Mode_Ev_Permission 3;
BA_ "GenSigSendType" SG_ 192 Xev_Mode_Status 3;
BA_ "GenSigStartValue" SG_ 192 Xev_Mode_Status 14;
BA_ "GenSigInvalidValue" SG_ 192 Xev_Mode_Status 15;
BA_ "GenSigSendType" SG_ 192 Drive_Mode_Towing_Permission 3;
BA_ "GenSigStartValue" SG_ 192 Drive_Mode_Towing_Permission 2;
BA_ "GenSigInvalidValue" SG_ 192 Drive_Mode_Towing_Permission 3;
BA_ "GenSigSendType" SG_ 192 Drive_Mode_Offroad_Permission 3;
BA_ "GenSigStartValue" SG_ 192 Drive_Mode_Offroad_Permission 2;
BA_ "GenSigInvalidValue" SG_ 192 Drive_Mode_Offroad_Permission 3;
BA_ "GenSigSendType" SG_ 192 Drive_Mode_Sport_Permission 3;
BA_ "GenSigStartValue" SG_ 192 Drive_Mode_Sport_Permission 2;
BA_ "GenSigInvalidValue" SG_ 192 Drive_Mode_Sport_Permission 3;
BA_ "GenSigSendType" SG_ 192 Drive_Mode_Normal_Permission 3;
BA_ "GenSigStartValue" SG_ 192 Drive_Mode_Normal_Permission 2;
BA_ "GenSigInvalidValue" SG_ 192 Drive_Mode_Normal_Permission 3;
BA_ "GenSigSendType" SG_ 192 Drive_Mode_List_Info 3;
BA_ "GenSigStartValue" SG_ 192 Drive_Mode_List_Info 14;
BA_ "GenSigInvalidValue" SG_ 192 Drive_Mode_List_Info 15;
BA_ "GenSigSendType" SG_ 192 Drive_Mode_Status 3;
BA_ "GenSigStartValue" SG_ 192 Drive_Mode_Status 14;
BA_ "GenSigTimeoutTime_ADU" SG_ 192 Drive_Mode_Status 600;
BA_ "GenSigInvalidValue" SG_ 192 Drive_Mode_Status 15;
BA_ "GenSigSendType" SG_ 159 BpedDrvAppl_D_Actl 3;
BA_ "GenSigTimeoutTime_ADU" SG_ 159 BpedDrvAppl_D_Actl 600;
BA_ "GenSigSendType" SG_ 159 IndirectIllumination_D_Rq 3;
BA_ "GenSigSendType" SG_ 159 WelcomIllumination_D_Rq 3;
BA_ "GenSigSendType" SG_ 159 FootLamp_D_Rq 3;
BA_ "GenSigSendType" SG_ 159 DoorCourtesyLamp_D_Rq 3;
BA_ "GenSigSendType" SG_ 159 CargoLamp_D_Rq 3;
BA_ "GenSigSendType" SG_ 159 DimmerCancel 3;
BA_ "GenSigStartValue" SG_ 159 EngOff_T_Actl 65534;
BA_ "GenSigInvalidValue" SG_ 159 EngOff_T_Actl 65535;
BA_ "GenSigSendType" SG_ 159 Drive_Mode_FlashReq 3;
BA_ "GenSigSendType" SG_ 159 Drive_Mode_Enabled 3;
BA_ "GenSigSendType" SG_ 159 CarMde_D_Actl 3;
BA_ "GenSigSendType" SG_ 159 PanelBrightLevel_Pc_Actl 3;
BA_ "GenSigInvalidValue" SG_ 159 PanelBrightLevel_Pc_Actl 255;
BA_ "GenSigSendType" SG_ 159 REVSWVLD 3;
BA_ "GenSigSendType" SG_ 159 Reverselamp_B_Req 3;
BA_ "GenSigTimeoutTime_ADU" SG_ 159 Reverselamp_B_Req 600;
BA_ "GenSigSendType" SG_ 159 IlumiMde_D_Actl 3;
BA_ "GenSigSendType" SG_ 159 Illum_PowerControlStatus 3;
BA_ "GenSigTimeoutTime_ADU" SG_ 159 Illum_PowerControlStatus 600;
BA_ "GenSigSendType" SG_ 159 AudioMute_B_Actl 3;
BA_ "GenSigSendType" SG_ 159 RoomFuseStat_D_Actl 3;
BA_ "GenSigStartValue" SG_ 159 RoomFuseStat_D_Actl 3;
BA_ "GenSigSendType" SG_ 154 LED_HI_B 3;
BA_ "GenSigSendType" SG_ 154 SndRSP_Fail_B_Actl 3;
BA_ "GenSigSendType" SG_ 154 SndFSP_Fail_B_Actl 3;
BA_ "GenSigSendType" SG_ 154 FuelCalcCmplt_B_Actl 3;
BA_ "GenSigSendType" SG_ 154 Refuel2_B_Actl 3;
BA_ "GenSigSendType" SG_ 154 Refuel1_B_Actl 3;
BA_ "GenSigSendType" SG_ 154 Hazard_lamp_State_D_Actl 3;
BA_ "GenSigSendType" SG_ 154 DRL_Tail_Lamp_B_Rq 3;
BA_ "GenSigSendType" SG_ 154 TNS_Buzzer_Cntl_Req 3;
BA_ "GenSigSendType" SG_ 154 Turn_Snd_Cmd_Left 3;
BA_ "GenSigSendType" SG_ 154 Turn_Snd_Cmd_Right 3;
BA_ "GenSigSendType" SG_ 154 WiprGuid_B_Rq 3;
BA_ "GenSigSendType" SG_ 154 BurglarHorn_B_Req 3;
BA_ "GenSigSendType" SG_ 154 RSRmid_Indicator_Req 3;
BA_ "GenSigSendType" SG_ 154 RSRmid_DisplayReq 3;
BA_ "GenSigSendType" SG_ 154 BlwCont_B_Actl 3;
BA_ "GenSigSendType" SG_ 154 FrntWipr_D_Actl 3;
BA_ "GenSigTimeoutTime_ADU" SG_ 154 FrntWipr_D_Actl 300;
BA_ "GenSigSendType" SG_ 154 SteeringHeatCutLvl 3;
BA_ "GenSigSendType" SG_ 154 PtcCutLvl 3;
BA_ "GenSigSendType" SG_ 154 BmotCutLvl 3;
BA_ "GenSigSendType" SG_ 154 SeatHeatCutLvl 3;
BA_ "GenSigSendType" SG_ 154 RdefCutLvl 3;
BA_ "GenSigSendType" SG_ 154 SeatVentCutLvl 3;
BA_ "GenSigSendType" SG_ 154 WshrLvl_D_Actl 3;
BA_ "GenSigStartValue" SG_ 154 WshrLvl_D_Actl 3;
BA_ "GenSigSendType" SG_ 154 TNS_IpcDsply_D_Rq 3;
BA_ "GenSigSendType" SG_ 154 Turn_Ind_Cmd_Left 3;
BA_ "GenSigTimeoutTime_ADU" SG_ 154 Turn_Ind_Cmd_Left 300;
BA_ "GenSigSendType" SG_ 154 Turn_Ind_Cmd_Right 3;
BA_ "GenSigTimeoutTime_ADU" SG_ 154 Turn_Ind_Cmd_Right 300;
BA_ "GenSigSendType" SG_ 154 ResHeatCont_B_Actl 3;
BA_ "GenSigSendType" SG_ 154 ResEngCont_B_Actl 3;
BA_ "GenSigSendType" SG_ 154 CBDA_Sleep_B_Rq 3;
BA_ "GenSigSendType" SG_ 154 RearWiprLo_B_Rq 3;
BA_ "GenSigSendType" SG_ 154 AutoWiprIND_B_Rq 3;
BA_ "GenSigSendType" SG_ 154 RearFogIpcDsply_B_Rq 3;
BA_ "GenSigSendType" SG_ 154 HiBeamIpcDsply_B_Rq 3;
BA_ "GenSigTimeoutTime_ADU" SG_ 153 LightCont_No_Cs 1500;
BA_ "GenSigTimeoutTime_ADU" SG_ 153 LightCont_No_Cnt 1500;
BA_ "GenSigSendType" SG_ 153 SeatBeltWrn_D_Rq 3;
BA_ "GenSigSendType" SG_ 153 PWGGUID_B_Rq 3;
BA_ "GenSigSendType" SG_ 153 LVL_Act_Trgt_length 3;
BA_ "GenSigSendType" SG_ 153 LidStop_B_Req 3;
BA_ "GenSigSendType" SG_ 153 Outlet_L2_B_Req 3;
BA_ "GenSigSendType" SG_ 153 Outlet_L1_B_Req 3;
BA_ "GenSigSendType" SG_ 153 Outlet_R2_B_Req 3;
BA_ "GenSigSendType" SG_ 153 Outlet_R1_B_Req 3;
BA_ "GenSigSendType" SG_ 153 Rearfog_B_Req 3;
BA_ "GenSigSendType" SG_ 153 TnsLamp_Frnt_B_Rq 3;
BA_ "GenSigSendType" SG_ 153 RLS_Control_req 3;
BA_ "GenSigStartValue" SG_ 153 LghtSwState_D_Qf 1;
BA_ "GenSigTimeoutTime_ADU" SG_ 153 LghtSwState_D_Qf 1500;
BA_ "GenSigSendType" SG_ 153 Light_LeverSW_Mode_D_Actl 3;
BA_ "GenSigSendType" SG_ 153 Light_CombiSW_Mode_D_Actl 3;
BA_ "GenSigTimeoutTime_ADU" SG_ 153 Light_CombiSW_Mode_D_Actl 1500;
BA_ "GenSigSendType" SG_ 153 FSM_Lamp_B_Rq 3;
BA_ "GenSigSendType" SG_ 153 DRL_Lamp_B_Rq 3;
BA_ "GenSigSendType" SG_ 153 HeadLampHiCtl_D_Rq 3;
BA_ "GenSigTimeoutTime_ADU" SG_ 153 HeadLampHiCtl_D_Rq 1500;
BA_ "GenSigSendType" SG_ 153 HeadLampLoCtl_D_Rq 3;
BA_ "GenSigTimeoutTime_ADU" SG_ 153 HeadLampLoCtl_D_Rq 1500;
BA_ "GenSigSendType" SG_ 153 TnsLamp_Rear_B_Rq 3;
BA_REL_ "SC_Verification" BU_SG_REL_ ADU SG_ 152 WheelData_2_MACTx 0;
BA_REL_ "SC_Verification" BU_SG_REL_ ADU SG_ 152 WheelData_2_FVTx 0;
BA_ "GenSigTimeoutTime_ADU" SG_ 152 VehVActlBrk_No_Cs 60;
BA_ "GenSigTimeoutTime_ADU" SG_ 152 VehVActlBrk_No_Cnt 60;
BA_ "GenSigTimeoutTime_ADU" SG_ 152 VehVActlBrk_D_Qf 60;
BA_ "GenSigTimeoutTime_ADU" SG_ 152 Veh_V_ActlBrk 60;
BA_ "GenSigSendType" SG_ 150 HECSwtchB_2_Cs 3;
BA_ "GenSigSendType" SG_ 150 HECSwtchB_2_Cnt 3;
BA_ "GenSigSendType" SG_ 150 FuelLidOpen_Rq_SW_B_Actl 3;
BA_ "GenSigSendType" SG_ 150 TLO_PLG_Sw_B_Actl 3;
BA_ "GenSigSendType" SG_ 150 ADASOfSw_B_Actl 3;
BA_ "GenSigTimeoutTime_ADU" SG_ 150 ADASOfSw_B_Actl 300;
BA_ "GenSigSendType" SG_ 150 MultiSw_D_Qf 3;
BA_ "GenSigStartValue" SG_ 150 MultiSw_D_Qf 2;
BA_ "GenSigTimeoutTime_ADU" SG_ 150 MultiSw_D_Qf 300;
BA_ "GenSigStartValue" SG_ 148 RIL_STAT 1;
BA_ "GenSigSendType" SG_ 148 MntSet_Oil_HEC_Req 3;
BA_ "GenSigSendType" SG_ 148 HEC_HUD_Disp_MRCC_Status 3;
BA_ "GenSigSendType" SG_ 148 HEC_HUD_Disp_MRCC_Status2 3;
BA_ "GenSigTimeoutTime_ADU" SG_ 145 HECSwtchA_Cs 300;
BA_ "GenSigTimeoutTime_ADU" SG_ 145 HECSwtchA_Cnt 300;
BA_ "GenSigSendType" SG_ 145 WiprTestMode_B_Actl 3;
BA_ "GenSigSendType" SG_ 145 FrntWiprInt_V_Actl 3;
BA_ "GenSigStartValue" SG_ 145 FrntWiprInt_V_Actl 20;
BA_ "GenSigInvalidValue" SG_ 145 FrntWiprInt_V_Actl 255;
BA_ "GenSigSendType" SG_ 145 PaddleShiftDwn_D_Actl 3;
BA_ "GenSigSendType" SG_ 145 PaddleShiftUp_D_Actl 3;
BA_ "GenSigSendType" SG_ 145 RearWasherSw_B_Actl 3;
BA_ "GenSigSendType" SG_ 145 FrntWasherSw_B_Actl 3;
BA_ "GenSigTimeoutTime_ADU" SG_ 145 FrntWasherSw_B_Actl 300;
BA_ "GenSigSendType" SG_ 145 RearWiprStats_D_Actl 3;
BA_ "GenSigSendType" SG_ 145 FrntWiprStats_D_Actl 3;
BA_ "GenSigTimeoutTime_ADU" SG_ 145 FrntWiprStats_D_Actl 300;
BA_ "GenSigStartValue" SG_ 145 WiprSw_D_Qf 1;
BA_ "GenSigTimeoutTime_ADU" SG_ 145 WiprSw_D_Qf 300;
BA_ "GenSigSendType" SG_ 145 ALH_HBC_Sw_B_Actl 3;
BA_ "GenSigTimeoutTime_ADU" SG_ 145 ALH_HBC_Sw_B_Actl 300;
BA_ "GenSigSendType" SG_ 145 Mfs_Turn_Neutral_SW_Status 3;
BA_ "GenSigStartValue" SG_ 145 Mfs_Turn_Neutral_SW_Status 1;
BA_ "GenSigTimeoutTime_ADU" SG_ 145 Mfs_Turn_Neutral_SW_Status 300;
BA_ "GenSigSendType" SG_ 145 Mfs_Turn_Stalk_SW_Status 3;
BA_ "GenSigTimeoutTime_ADU" SG_ 145 Mfs_Turn_Stalk_SW_Status 300;
BA_ "GenSigTimeoutTime_ADU" SG_ 145 HeadLghtOffSw_B_Actl 300;
BA_ "GenSigSendType" SG_ 145 PassngSw_B_Actl 3;
BA_ "GenSigTimeoutTime_ADU" SG_ 145 PassngSw_B_Actl 300;
BA_ "GenSigSendType" SG_ 145 RearFogSw_B_Actl 3;
BA_ "GenSigTimeoutTime_ADU" SG_ 145 RearFogSw_B_Actl 300;
BA_ "GenSigSendType" SG_ 145 HeadLghtHiSw_B_Actl 3;
BA_ "GenSigTimeoutTime_ADU" SG_ 145 HeadLghtHiSw_B_Actl 300;
BA_ "GenSigSendType" SG_ 145 HeadLghtLoSw_B_Actl 3;
BA_ "GenSigTimeoutTime_ADU" SG_ 145 HeadLghtLoSw_B_Actl 300;
BA_ "GenSigSendType" SG_ 145 TnsSw_B_Actl 3;
BA_ "GenSigTimeoutTime_ADU" SG_ 145 TnsSw_B_Actl 300;
BA_ "GenSigStartValue" SG_ 145 LghtSw_D_Qf 1;
BA_ "GenSigTimeoutTime_ADU" SG_ 145 LghtSw_D_Qf 300;
BA_REL_ "SC_Verification" BU_SG_REL_ CGW SG_ 139 KZK08B_MACTx 0;
BA_REL_ "SC_Verification" BU_SG_REL_ CGW SG_ 139 FV08B_FVTx 0;
BA_ "GenSigSendType" SG_ 139 TSS_PRE 3;
BA_ "GenSigSendType" SG_ 139 TSSLGIDH 3;
BA_ "GenSigStartValue" SG_ 139 TSS_RACH 32767;
BA_ "GenSigStartValue" SG_ 139 TSS_ACCH 32767;
BA_ "GenSigStartValue" SG_ 139 SCMEXIST 3;
BA_ "GenSigSendType" SG_ 139 VGRSTRGR 3;
BA_ "GenSigSendType" SG_ 139 PBATRGR 3;
BA_ "GenSigStartValue" SG_ 136 SteerMtrCurrent_I_Actl_088 127;
BA_ "GenSigInvalidValue" SG_ 136 SteerMtrCurrent_I_Actl_088 255;
BA_ "GenSigStartValue" SG_ 136 ADAS_Eps_Final_Tq_Actl 4095;
BA_ "GenSigTimeoutTime_ADU" SG_ 136 ADAS_Eps_Final_Tq_Actl 60;
BA_ "GenSigInvalidValue" SG_ 136 ADAS_Eps_Final_Tq_Actl 8191;
BA_ "GenSigTimeoutTime_ADU" SG_ 136 ADAS_Lock2Lock_An_Const 60;
BA_ "GenSigInvalidValue" SG_ 136 ADAS_Lock2Lock_An_Const 1023;
BA_ "GenSigStartValue" SG_ 136 ADAS_Assist_Tq_Actl 4095;
BA_ "GenSigTimeoutTime_ADU" SG_ 136 ADAS_Assist_Tq_Actl 60;
BA_ "GenSigInvalidValue" SG_ 136 ADAS_Assist_Tq_Actl 8191;
BA_ "GenSigTimeoutTime_ADU" SG_ 136 ADAS_SteOnOff_D_Actl 60;
BA_ "GenSigTimeoutTime_ADU" SG_ 136 ADAS_SteCtlActv_D_Actl 60;
BA_ "GenSigTimeoutTime_ADU" SG_ 136 ADAS_SteCtlData_No_Cnt 60;
BA_ "GenSigTimeoutTime_ADU" SG_ 136 EPS_State_ADAS 60;
BA_ "GenSigTimeoutTime_ADU" SG_ 136 ADAS_SteInhbt_B_Flag 60;
BA_ "GenSigTimeoutTime_ADU" SG_ 136 ADAS_StrCtrData_No_CRC 60;
BA_ "GenSigStartValue" SG_ 135 SteWhlComp_An_Est 32766;
BA_ "GenSigTimeoutTime_ADU" SG_ 135 SteWhlComp_An_Est 40;
BA_ "GenSigInvalidValue" SG_ 135 SteWhlComp_An_Est 32767;
BA_ "GenSigTimeoutTime_ADU" SG_ 135 SteWhlCompAnEst_D_Qf 40;
BA_ "GenSigTimeoutTime_ADU" SG_ 135 SteAngEstAn_No_Cs 40;
BA_REL_ "SC_Verification" BU_SG_REL_ CGW SG_ 133 KZK085_MACTx 0;
BA_REL_ "SC_Verification" BU_SG_REL_ CGW SG_ 133 FV085_FVTx 0;
BA_ "GenSigStartValue" SG_ 132 SteAngReltv_An_Sns 32766;
BA_ "GenSigInvalidValue" SG_ 132 SteAngReltv_An_Sns 32767;
BA_ "GenSigStartValue" SG_ 132 SteAng_CalStart 1;
BA_ "GenSigStartValue" SG_ 130 SteWhlRelCalib_An_Sns 32766;
BA_ "GenSigInvalidValue" SG_ 130 SteWhlRelCalib_An_Sns 32767;
BA_REL_ "SC_Verification" BU_SG_REL_ ADU SG_ 129 KZK081_MACTx 0;
BA_REL_ "SC_Verification" BU_SG_REL_ ADU SG_ 129 FV081_FVTx 0;
BA_ "GenSigStartValue" SG_ 129 V_YR1HR0 10000;
BA_ "GenSigStartValue" SG_ 129 V_GYHR0 3000;
BA_ "GenSigStartValue" SG_ 129 V_GXHR0 3000;
BA_ "GenSigStartValue" SG_ 129 VSC_YAW0 512;
BA_ "GenSigStartValue" SG_ 129 VSC_YAWS 1;
BA_ "GenSigStartValue" SG_ 129 VSC_GY0 512;
BA_ "GenSigStartValue" SG_ 129 VSC_GYIV 1;
BA_ "GenSigStartValue" SG_ 129 VSC_GX0 512;
BA_ "GenSigStartValue" SG_ 129 VSC_GXIV 1;
BA_ "GenSigStartValue" SG_ 126 Drive_Mode_Towing_Req_DSC 2;
BA_ "GenSigStartValue" SG_ 126 Drive_Mode_OffRoad_Req_DSC 2;
BA_ "GenSigStartValue" SG_ 126 Drive_Mode_Normal_Req_DSC 2;
BA_ "GenSigStartValue" SG_ 126 VacRelativePres 1000;
BA_ "GenSigStartValue" SG_ 126 Drive_Mode_Sports_Req_DSC 2;
BA_ "GenSigStartValue" SG_ 126 VehYawComp_W_Actl_1 4094;
BA_ "GenSigInvalidValue" SG_ 126 VehYawComp_W_Actl_1 4095;
BA_REL_ "SC_Verification" BU_SG_REL_ ADU SG_ 116 YAW_Rate_Brake_Control_1_2_MACTx 0;
BA_REL_ "SC_Verification" BU_SG_REL_ ADU SG_ 116 YAW_Rate_Brake_Control_1_2_FVTx 0;
BA_ "GenSigTimeoutTime_ADU" SG_ 116 VehSensSig_2_No_Cs 60;
BA_ "GenSigTimeoutTime_ADU" SG_ 116 VehSensSig_2_No_Cnt 60;
BA_ "GenSigStartValue" SG_ 116 BrkMstAActl_D_Qf 1;
BA_ "GenSigTimeoutTime_ADU" SG_ 116 BrkMstAActl_D_Qf 60;
BA_ "GenSigStartValue" SG_ 116 BrkMstPrs_A_Actl 152;
BA_ "GenSigTimeoutTime_ADU" SG_ 116 BrkMstPrs_A_Actl 60;
BA_ "GenSigSendType" SG_ 80 Clutch_Cut_Switch_Status 3;
BA_ "GenSigSendType" SG_ 80 SKE_IR_Request 3;
BA_ "GenSigSendType" SG_ 80 SKE_SISS_Status 3;
BA_ "GenSigInvalidValue" SG_ 80 SKE_SISS_Status 15;
BA_ "GenSigSendType" SG_ 80 SKE_SISS_Mode 3;
BA_ "GenSigSendType" SG_ 80 CrankStat_B_Actl 3;
BA_ "GenSigSendType" SG_ 80 AutoP_Request 3;
BA_ "GenSigSendType" SG_ 80 IG_OFF_Delay_State 3;
BA_ "GenSigSendType" SG_ 80 IG_mode 3;
BA_ "GenSigSendType" SG_ 80 PowerControlStatus 3;
BA_ "GenSigTimeoutTime_ADU" SG_ 80 PowerControlStatus 300;
BA_REL_ "SC_Verification" BU_SG_REL_ ADU SG_ 48 KZK030_MACTx 0;
BA_REL_ "SC_Verification" BU_SG_REL_ ADU SG_ 48 FV030_FVTx 0;
BA_ "GenSigInvalidValue" SG_ 48 EPSSAV 2048;
BA_ "GenSigSendType" SG_ 38 KZK026_MACTx 1;
BA_REL_ "SC_Verification" BU_SG_REL_ ADU SG_ 38 KZK026_MACTx 0;
BA_ "GenSigSendType" SG_ 38 FV026_FVTx 1;
BA_REL_ "SC_Verification" BU_SG_REL_ ADU SG_ 38 FV026_FVTx 0;
BA_ "GenSigSendType" SG_ 38 SteWhl_ChangeRateSign2 1;
BA_ "GenSigSendType" SG_ 38 SteWhl_ChangeRate2 1;
BA_ "GenSigSendType" SG_ 38 SteWhl_CalibStatus2 1;
BA_ "GenSigSendType" SG_ 38 SteWhl_FailureStatus2 1;
BA_ "GenSigSendType" SG_ 38 SteWhlAn_No_Cnt2 1;
BA_ "GenSigSendType" SG_ 38 SteWhlAn_No_Cs2 1;
BA_ "GenSigSendType" SG_ 38 SteWhlRelCalib_An_Sns2 1;
BA_ "GenSigStartValue" SG_ 38 SteWhlRelCalib_An_Sns2 32766;
BA_ "GenSigInvalidValue" SG_ 38 SteWhlRelCalib_An_Sns2 32767;
BA_ "GenSigSendType" SG_ 38 SteWhl_CalibRes2 1;
BA_REL_ "SC_Verification" BU_SG_REL_ ADU SG_ 32 CGW_Sync_MACTx 0;
BA_ "GenSigSendType" SG_ 28 MACKVERI4_2 1;
BA_ "GenSigSendType" SG_ 28 MACKVERI4_1 1;
BA_ "GenSigSendType" SG_ 27 MACKVERI3_2 1;
BA_ "GenSigSendType" SG_ 27 MACKVERI3_1 1;
BA_ "GenSigSendType" SG_ 26 MACKVERI2_2 1;
BA_ "GenSigSendType" SG_ 26 MACKVERI2_1 1;
BA_ "GenSigSendType" SG_ 25 MACKVERI1_2 1;
BA_ "GenSigSendType" SG_ 25 MACKVERI1_1 1;
BA_ "GenSigSendType" SG_ 24 MACKUSAGE 1;
BA_ "GenSigSendType" SG_ 24 MACKID 1;
BA_ "GenSigSendType" SG_ 23 MACKSEND8_2 1;
BA_ "GenSigSendType" SG_ 23 MACKSEND8_1 1;
BA_ "GenSigSendType" SG_ 22 MACKSEND7_2 1;
BA_ "GenSigSendType" SG_ 22 MACKSEND7_1 1;
BA_ "GenSigSendType" SG_ 21 MACKSEND6_2 1;
BA_ "GenSigSendType" SG_ 21 MACKSEND6_1 1;
BA_ "GenSigSendType" SG_ 20 MACKSEND5_2 1;
BA_ "GenSigSendType" SG_ 20 MACKSEND5_1 1;
BA_ "GenSigSendType" SG_ 19 MACKSEND4_2 1;
BA_ "GenSigSendType" SG_ 19 MACKSEND4_1 1;
BA_ "GenSigSendType" SG_ 18 MACKSEND3_2 1;
BA_ "GenSigSendType" SG_ 18 MACKSEND3_1 1;
BA_ "GenSigSendType" SG_ 17 MACKSEND2_2 1;
BA_ "GenSigSendType" SG_ 17 MACKSEND2_1 1;
BA_ "GenSigSendType" SG_ 16 MACKSEND1_2 1;
BA_ "GenSigSendType" SG_ 16 MACKSEND1_1 1;
VAL_ 597 HMI_Status_TSROffMute_Rq 0 "no indication" 1 "TSR Off" 2 "TSR Mute" 3 "Reserved" ;
VAL_ 597 HMI_Status_CBDA5_Rq 0 "no indication" 1 "CBDA Buzzer LH" ;
VAL_ 597 HMI_Status_CBDA4_Rq 0 "no indication" 1 "CBDA Buzzer RH" ;
VAL_ 597 HMI_Status_BSM6_Rq 0 "no indication" 1 "BSM Buzzer LH" ;
VAL_ 597 HMI_Status_BSM5_Rq 0 "no indication" 1 "BSM Buzzer RH" ;
VAL_ 597 HMI_Status_DAS2_Rq 0 "no indication" 1 "NEO DAS 1" 2 "NEO DAS 2" 3 "NEO DAS 3" 4 "NEO DAS 4" 5 "NEO DAS 5" 6 "NEO DAS 6" 7 "NEO DAS 7" ;
VAL_ 597 HMI_Status_DAS1_Rq 0 "no indication" 1 "DAS OFF" 2 "DAS Inactive" 3 "DAS Active" 4 "DAS Override" 5 "DAS Control" 6 "DAS Mute OFF" 7 "DAS Mute Inactive" 8 "DAS Mute Active" 9 "DAS Mute Override" 10 "DAS Mute Control" 11 "Reserved" 12 "Reserved" 13 "Reserved" 14 "Reserved" 15 "Reserved" ;
VAL_ 597 HMI_Status_TSR3_Rq 0 "no indication" 1 "TSR On Sound" ;
VAL_ 597 HMI_Status_TSR2_Rq 0 "no indication" 1 "TSR EV Change" ;
VAL_ 597 HMI_Status_TSR1_Rq 0 "no indication" 1 "TSR On Warn1" 2 "TSR On Warn2" 3 "TSR On Warn3" 4 "Reserved" 5 "Reserved" 6 "Reserved" 7 "Reserved" ;
VAL_ 597 HMI_Status_LKA10_Rq 0 "no indication" 1 "LKA Control Limit" ;
VAL_ 597 HMI_Status_LKA9_Rq 0 "no indication" 1 "CTS Handsfree1" 2 "CTS Handsfree2" 3 "CTS Handsfree3" 4 "CTS Handsfree4" 5 "Reserved" 6 "Reserved" 7 "Reserved" ;
VAL_ 597 HMI_Status_LKA8_Rq 0 "no indication" 1 "LKA Reject RMF Activated" ;
VAL_ 597 HMI_Status_LKA7_Rq 0 "no indication" 1 "LKA Reject Speed Over" ;
VAL_ 597 HMI_Status_LKA6_Rq 0 "no indication" 1 "LKA Curve Limit Over" ;
VAL_ 597 HMI_Status_LKA5_Rq 0 "no indication" 1 "LKA Lane Limit Over" ;
VAL_ 597 HMI_Status_LKA4_Rq 0 "no indication" 1 "LKA Reject Locked" ;
VAL_ 597 HMI_Status_LKA3_Rq 0 "no indication" 1 "LKA Inactive Handson" ;
VAL_ 597 HMI_Status_LKA2_Rq 0 "no indication" 1 "LKA EV Suspended" ;
VAL_ 597 HMI_Status_LKA1_Rq 0 "no indication" 1 "LKA Inactive" 2 "LKA Active" 3 "LKA Override" ;
VAL_ 597 HMI_Status_ACCASCISA2_Rq 0 "no indication" 1 "ACC ASC ISA Set Speed Over" ;
VAL_ 597 HMI_Status_ACCASCISA1_Rq 0 "no indication" 1 "ACC Disp Change Reject" ;
VAL_ 597 HMI_Status_ACCASCISA_OVSP_Rq 0 "no indication" 1 "ACC ASC ISA Set Speed Over1" 2 "ACC ASC ISA Set Speed Over2" 3 "Reserved" ;
VAL_ 597 HMI_Status_ISA2_Rq 0 "no indication" 1 "ISA EV Reject" ;
VAL_ 597 HMI_Status_ISA1_Rq 0 "no indication" 1 "ISA Inactive" 2 "ISA Active" 3 "ISA Kickdown" ;
VAL_ 597 HMI_Status_ACCASC4_Rq 0 "no indication" 1 "ACC Reject" ;
VAL_ 597 HMI_Status_ACCASC3_Rq 0 "no indication" 1 "ACC ASC Brake Req" ;
VAL_ 597 HMI_Status_ACCASC2_Rq 0 "no indication" 1 "ACC Disp Change" ;
VAL_ 597 HMI_Status_ACCASC1_Rq 0 "no indication" 1 "ACC ASC Override" ;
VAL_ 597 HMI_Status_ASC3_Rq 0 "no indication" 1 "ASC EV Suspended" ;
VAL_ 597 HMI_Status_ASC2_Rq 0 "no indication" 1 "ASC EV Reject" ;
VAL_ 597 HMI_Status_ASC1_Rq 0 "no indication" 1 "ASC Inactive" 2 "ASC Active" 3 "ASC Override" ;
VAL_ 597 HMI_Status_DAS3_Rq 0 "OFF" 1 "Target Bar Silver" 2 "Target Bar Green" 3 "Target Bar Blue" 4 "Target Bar Amber" 5 "Target Bar Amber Flash" 6 "Reserved" 7 "Reserved" ;
VAL_ 597 HMI_Status_ACC12_Rq 0 "no indication" 1 "ACC Warning Cancel" ;
VAL_ 597 HMI_Status_ACC11_Rq 0 "no indication" 1 "ACC Front Vehicle Approach" ;
VAL_ 597 HMI_Status_ACC10_Rq 0 "no indication" 1 "ACC Deceleration EU Left" ;
VAL_ 597 HMI_Status_ACC9_Rq 0 "no indication" 1 "ACC Disp Side Vehicle" ;
VAL_ 597 HMI_Status_ACC8_Rq 0 "no indication" 1 "ACC Disp Curve" 2 "ACC Disp Intersection" 3 "ACC Disp Intersection T" 4 "ACC Disp Tollgate" 5 "ACC Disp Roundabout" 6 "ACC Disp Stop" 7 "ACC Disp Yield" 8 "Reserved" 9 "Reserved" 10 "Reserved" 11 "Reserved" 12 "Reserved" 13 "Reserved" 14 "Reserved" 15 "Reserved" ;
VAL_ 597 HMI_Status_ACC7_Rq 0 "No Target" 1 "ACC Target Car" 2 "ACC Target Truck" 3 "ACC Target Bike" 4 "ACC Target Human" 5 "Invalid" 6 "Reserved" 7 "Reserved" ;
VAL_ 597 HMI_Status_ACC6_Rq 0 "no indication" 1 "ACC Auto Start" 2 "ACC Auto Start Reject" 3 "Reserved" ;
VAL_ 597 HMI_Status_ACC5_Rq 0 "no indication" 1 "ACC Disp Warning" ;
VAL_ 597 HMI_Status_ACC4_Rq 0 "no indication" 1 "Reserved" 2 "ACC Shift UP" 3 "ACC Shift DOWN" ;
VAL_ 597 HMI_Status_ACC3_Rq 0 "no indication" 1 "ACC DAS SW Reject" ;
VAL_ 597 HMI_Status_ACC2_Rq 0 "no indication" 1 "ACC Suspended" ;
VAL_ 597 HMI_Status_ACC1_Rq 0 "no indication" 1 "ACC Inactive" 2 "ACC Active" 3 "ACC Override" 4 "ACC Stop" 5 "Reserved" 6 "Reserved" 7 "Reserved" ;
VAL_ 597 HMI_Status_RCTA2_Rq 0 "no indication" 1 "RCTA Target LH" ;
VAL_ 597 HMI_Status_RCTA1_Rq 0 "no indication" 1 "RCTA Target RH" ;
VAL_ 597 HMI_Status_RPTB2_Rq 0 "no indication" 1 "RCTB EV Notification" ;
VAL_ 597 HMI_Status_RCTB1_Rq 0 "no indication" 1 "RCTB OFF" 2 "RCTB Control Brake" 3 "RCTB Control Engine" ;
VAL_ 597 HMI_Status_RPTC2_Rq 0 "no indication" 1 "RPTC EV Notification" ;
VAL_ 597 HMI_Status_RPTC1_Rq 0 "no indication" 1 "RPTC OFF" 2 "RPTC Control" 3 "RPTC Notification" ;
VAL_ 597 HMI_Status_PAEB2_Rq 0 "no indication" 1 "PAEB EV Notification" ;
VAL_ 597 HMI_Status_PAEB1_Rq 0 "no indication" 1 "PAEB OFF" 2 "PAEB Control Front" 3 "PAEB Control Rear" 4 "PAEB Notification" 5 "Reserved" 6 "Reserved" 7 "Reserved" ;
VAL_ 597 HMI_Status_OCP8_Rq 0 "no indication" 1 "OCP OPP LH 1" 2 "OCP OPP LH 2" 3 "Reserved" ;
VAL_ 597 HMI_Status_OCP7_Rq 0 "no indication" 1 "OCP OPP RH 1" 2 "OCP OPP RH 2" 3 "Reserved" ;
VAL_ 597 HMI_Status_OCP6_Rq 0 "no indication" 1 "OCP Lane LH 1" 2 "OCP Lane LH 2" 3 "Reserved" ;
VAL_ 597 HMI_Status_OCP5_Rq 0 "no indication" 1 "OCP Lane RH 1" 2 "OCP Lane RH 2" 3 "Reserved" ;
VAL_ 597 HMI_Status_OCP4_Rq 0 "no indication" 1 "OCP AL" ;
VAL_ 597 HMI_Status_OCP3_Rq 0 "no indication" 1 "OCP OFF" 2 "OCP Control" 3 "Reserved" ;
VAL_ 597 HMI_Status_OCP2_Rq 0 "no indication" 1 "OCP EV Warning RH" ;
VAL_ 597 HMI_Status_OCP1_Rq 0 "no indication" 1 "OCP EV Warning LH" ;
VAL_ 597 HMI_Status_CBDA3_Rq 0 "no indication" 1 "CBDA Target LH 1" 2 "CBDA Target LH 2" 3 "Reserved" ;
VAL_ 597 HMI_Status_CBDA2_Rq 0 "no indication" 1 "CBDA Target RH 1" 2 "CBDA Target RH 2" 3 "Reserved" ;
VAL_ 597 HMI_Status_CBDA1_Rq 0 "no indication" 1 "CBDA Deartivated" ;
VAL_ 597 HMI_Status_BSM4_Rq 0 "no indication" 1 "BSM Target LH 1" 2 "BSM Target LH 2" 3 "Reserved" ;
VAL_ 597 HMI_Status_BSM3_Rq 0 "no indication" 1 "BSM Target RH 1" 2 "BSM Target RH 2" 3 "Reserved" ;
VAL_ 597 HMI_Status_BSM2_Rq 0 "no indication" 1 "BSM EV Warning RH" ;
VAL_ 597 HMI_Status_BSM1_Rq 0 "no indication" 1 "BSM EV Warning LH" ;
VAL_ 597 HMI_Status_BSP8_Rq 0 "no indication" 1 "BSP Target LH 1" 2 "BSP Target LH 2" 3 "Reserved" ;
VAL_ 597 HMI_Status_BSP7_Rq 0 "no indication" 1 "BSP Target RH 1" 2 "BSP Target RH 2" 3 "Reserved" ;
VAL_ 597 HMI_Status_BSP6_Rq 0 "no indication" 1 "BSP Lane LH 1" 2 "BSP Lane LH 2" 3 "Reserved" ;
VAL_ 597 HMI_Status_BSP5_Rq 0 "no indication" 1 "BSP Lane RH 1" 2 "BSP Lane RH 2" 3 "Reserved" ;
VAL_ 597 HMI_Status_BSP4_Rq 0 "no indication" 1 "BSP AL" ;
VAL_ 597 HMI_Status_BSP3_Rq 0 "no indication" 1 "BSP OFF" 2 "BSP Control" 3 "Reserved" ;
VAL_ 597 HMI_Status_BSP2_Rq 0 "no indication" 1 "BSP EV Warning RH" ;
VAL_ 597 HMI_Status_BSP1_Rq 0 "no indication" 1 "BSP EV Warning LH" ;
VAL_ 597 HMI_Status_RDPRDW4_Rq 0 "no indication" 1 "RDP AL Buzzer" ;
VAL_ 597 HMI_Status_RDPRDW3_Rq 0 "no indication" 1 "RDP OFF" 2 "RDP Control" 3 "Reserved" ;
VAL_ 597 HMI_Status_RDPRDW2_Rq 0 "no indication" 1 "RDP EV Warning RH" ;
VAL_ 597 HMI_Status_RDPRDW1_Rq 0 "no indication" 1 "RDP EV Warning LH" ;
VAL_ 597 HMI_Status_LDW5_Rq 0 "no indication" 1 "LDW Lane LH 1" 2 "LDW Lane LH 2" 3 "Reserved" ;
VAL_ 597 HMI_Status_LDW4_Rq 0 "no indication" 1 "LDW Lane RH 1" 2 "LDW Lane RH 2" 3 "Reserved" ;
VAL_ 597 HMI_Status_LDW3_Rq 0 "no indication" 1 "LDW EV Warning RH" ;
VAL_ 597 HMI_Status_LDW2_Rq 0 "no indication" 1 "LDW EV Warning LH" ;
VAL_ 597 HMI_Status_LDW1_Rq 0 "no indication" 1 "LDW OFF" ;
VAL_ 597 HMI_Status_LDP4_Rq 0 "no indication" 1 "LDP Lane LH 1" 2 "LDP Lane LH 2" 3 "Reserved" ;
VAL_ 597 HMI_Status_LDP3_Rq 0 "no indication" 1 "LDP Lane RH 1" 2 "LDP Lane RH 2" 3 "Reserved" ;
VAL_ 597 HMI_Status_LDP2_Rq 0 "no indication" 1 "LDP AL" ;
VAL_ 597 HMI_Status_LDP1_Rq 0 "no indication" 1 "LDP OFF" 2 "LDP Control" 3 "Reserved" ;
VAL_ 597 HMI_Status_FCTA4_Rq 0 "no indication" 1 "FCTA Target LH 1" 2 "FCTA Target LH 2" 3 "Reserved" ;
VAL_ 597 HMI_Status_FCTA3_Rq 0 "no indication" 1 "FCTA Target RH 1" 2 "FCTA Target RH 2" 3 "Reserved" ;
VAL_ 597 HMI_Status_FCTA2_Rq 0 "no indication" 1 "FCTA EV Warning RH" ;
VAL_ 597 HMI_Status_FCTA1_Rq 0 "no indication" 1 "FCTA EV Warning LH" ;
VAL_ 597 HMI_Status_CTB5_Rq 0 "no indication" 1 "CTB Target LH 1" 2 "CTB Target LH 2" 3 "Reserved" ;
VAL_ 597 HMI_Status_CTB4_Rq 0 "no indication" 1 "CTB Target RH 1" 2 "CTB Target RH 2" 3 "Reserved" ;
VAL_ 597 HMI_Status_CTB3_Rq 0 "no indication" 1 "CTB EV Notification" ;
VAL_ 597 HMI_Status_CTB2_Rq 0 "no indication" 1 "CTB EV Warning" ;
VAL_ 597 HMI_Status_CTB1_Rq 0 "no indication" 1 "CTB OFF" 2 "CTB Control" 3 "CTB Notification" ;
VAL_ 597 HMI_Status_PTC2_Rq 0 "no indication" 1 "PTC EV Notification" ;
VAL_ 597 HMI_Status_PTC1_Rq 0 "no indication" 1 "PTC OFF" 2 "PTC Control" 3 "PTC Notification" ;
VAL_ 597 HMI_Status_AEBFCW2_Rq 0 "no indication" 1 "AEB EV Notification" ;
VAL_ 597 HMI_Status_AEBFCW1_Rq 0 "no indication" 1 "AEB OFF" 2 "AEB Control Warning" 3 "AEB Control Brake" 4 "AEB Notification" 5 "AEB On Coming" 6 "AEB SUBFUNC OFF" 7 "Reserved" ;
VAL_ 593 AMBDS_ST 0 "Normal" 1 "Fail" ;
VAL_ 593 AMBDS_VL 0 "Invalid" 1 "Valid" ;
VAL_ 593 AMBTE_ST 0 "Normal" 1 "Fail" ;
VAL_ 593 AMBTE_VL 0 "Invalid" 1 "Valid" ;
VAL_ 593 GEAR_MET 0 "unconfirmed or no display req" 1 "(1st)" 2 "(2nd)" 3 "(3rd)" 4 "(4th)" 5 "(5th)" 6 "(6th)" 7 "(7th)" 8 "(8th)" 9 "(9th)" 10 "(10th)" 11 "(11th)" 12 "(12th)" 13 "(13th)" 14 "(14th)" 15 "(15th)" ;
VAL_ 593 THF 0 "Normal" 1 "Abnormal" ;
VAL_ 593 IGP_PT2 0 "Off" 1 "On" ;
VAL_ 593 B_B 0 "Off" 1 "On" ;
VAL_ 593 B_LO 0 "Off" 1 "On" ;
VAL_ 593 B_2 0 "Off" 1 "On" ;
VAL_ 593 B_3 0 "Off" 1 "On" ;
VAL_ 593 B_4 0 "Off" 1 "On" ;
VAL_ 593 B_D 0 "Off" 1 "On" ;
VAL_ 593 B_N 0 "Off" 1 "On" ;
VAL_ 593 B_R 0 "Off" 1 "On" ;
VAL_ 593 B_P 0 "Off" 1 "On" ;
VAL_ 593 PDLF 0 "Normal" 1 "Abnormal" ;
VAL_ 593 EGF 0 "Normal" 1 "Abnormal" ;
VAL_ 591 PKSB_HSW 0 "No Operation" 1 "Operation" ;
VAL_ 591 PKSBVLD 0 "INVALID" 1 "VALID" ;
VAL_ 591 APPCSVLD 0 "INVALID" 1 "VALID" ;
VAL_ 591 APPCSSW 0 "No Operation" 1 "Operation" ;
VAL_ 590 TSSMD2_M 0 "ON" 1 "OFF" ;
VAL_ 590 TSSMD1_M 0 "ON" 1 "OFF" ;
VAL_ 590 LTM_M 0 "ON" 1 "OFF" ;
VAL_ 590 CANCEL_M 0 "ON" 1 "OFF" ;
VAL_ 590 FLICK_PLUS_M 0 "ON" 1 "OFF" ;
VAL_ 590 FLICK_MINUS_M 0 "ON" 1 "OFF" ;
VAL_ 590 SET_PLUS_M 0 "ON" 1 "OFF" ;
VAL_ 590 SET_MINUS_M 0 "ON" 1 "OFF" ;
VAL_ 590 RES_M 0 "ON" 1 "OFF" ;
VAL_ 590 TSSMD2 0 "OFF" 1 "ON" ;
VAL_ 590 TSSMD1 0 "OFF" 1 "ON" ;
VAL_ 590 LTM 0 "OFF" 1 "ON" ;
VAL_ 590 CANCEL 0 "OFF" 1 "ON" ;
VAL_ 590 FLICK_PLUS 0 "OFF" 1 "ON" ;
VAL_ 590 FLICK_MINUS 0 "OFF" 1 "ON" ;
VAL_ 590 SET_PLUS 0 "OFF" 1 "ON" ;
VAL_ 590 SET_MINUS 0 "OFF" 1 "ON" ;
VAL_ 590 RES 0 "OFF" 1 "ON" ;
VAL_ 552 ShiftOpeWarning_D_Rq 0 "No Request" 1 "Message1(Check)" 2 "Reserve" 3 "Message3(A_Pedal ON in N)" 4 "Message4(N-D/N-R , Brake)" 5 "Reserve" 6 "Reserve" 7 "Reserve" 10 "Message10(AutoP)" 11 "Message11(not AutoP lever to N)" 12 "Message12(not AutoP)" 13 "Message13(Shift into P)" 15 "Reserve" ;
VAL_ 552 ShiftPos_D_Act 0 "Initial Value" 1 "1st" 2 "2nd" 3 "3rd" 4 "4th" 5 "5th" 6 "6th" 7 "7th" 8 "8th" 9 "9th" 10 "Reserve" 11 "Neutral" 12 "Reverse" 13 "Park" 14 "Unknown Hex" 15 "Invalid Hex" ;
VAL_ 552 TransmChangeLeverPosition 0 "between 2 positions" 1 "P" 2 "R" 3 "N" 4 "D" 5 "M" 6 "Reserve" 7 "not used" 14 "Initial" 15 "Invalid" ;
VAL_ 552 DispAtLvrPos_ArrowReq 0 "No" 1 "Yes" ;
VAL_ 552 ShiftPos_D_Trg 0 "Initial Value" 1 "1st" 2 "2nd" 3 "3rd" 4 "4th" 5 "5th" 6 "6th" 7 "7th" 8 "8th" 9 "9th" 10 "Reserve" 11 "Neutral" 12 "Reverse" 13 "Park" 14 "Unknown Hex" 15 "Invalid Hex" ;
VAL_ 552 DispAtLvrPos_Off_Req 0 "No" 1 "Yes" ;
VAL_ 552 AT_INDLvl_D_Rq 0 "Off" 1 "Level1(MostSevere)" 2 "Level2(Severe)" 3 "Level3(NotSevere)" ;
VAL_ 552 AT_FailSafeLvl_D_Rq 0 "Off" 1 "not Reverse" 2 "Reserve" 3 "Reserve" ;
VAL_ 552 PwrDwn_D_Req_ByTCM 0 "No Request" 1 "Message A" 2 "Message B" 3 "Message C" ;
VAL_ 552 SBW_INDLvl_D_Rq 0 "No Request" 1 "Level1(MostSevere)" 2 "Level2(Severe)" 3 "Level3(NotSevere)" ;
VAL_ 552 ParkLockWarning_D_Rq 0 "No Request" 1 "Message1(No Parking)" 2 "Reserve" 3 "Reserve" ;
VAL_ 552 ShiftrPos_D_Qf 0 "Faulty" 1 "No data exists" 2 "Not within specifications" 3 "OK" ;
VAL_ 552 SbwWarningLamp_B_Rq 0 "No" 1 "Yes" ;
VAL_ 552 TransmParking_D_Act 0 "Initial" 1 "Park" 2 "not Park" 3 "between P and notP" 4 "Reserve" 7 "Invalid" ;
VAL_ 552 TrnSlaCtl_B_Rq 0 "No" 1 "Yes" ;
VAL_ 552 TrnSlaCtlFlag 0 "No" 1 "Yes" ;
VAL_ 552 TrnShifActv_B_Actl 0 "No" 1 "Yes" ;
VAL_ 552 AT_OILTEMPHi_D_Rq 0 "No Request" 1 "Level1(Speed)" 2 "Level2(Stop)" 3 "Level3(Brake)" ;
VAL_ 552 TrnCnvtClu_D_Actl 0 "No Lock Up" 1 "Lock Up Slip" 2 "Lock Up Fixed" 3 "Fault or Unknown" ;
VAL_ 552 DispGearPos_FlashReq 0 "Off" 1 "On" ;
VAL_ 552 OD_Hold_Sport_Flash 0 "Off" 1 "On" ;
VAL_ 552 DispAtLvrPos_FlashReq 0 "Off" 1 "On" ;
VAL_ 552 DispAtLvrPos_D_Rq 0 "turn off(b2p)" 1 "P" 2 "R" 3 "N" 4 "D" 5 "DM" 6 "M" 7 "Reserve" 8 "Reserve" 14 "Initial/Unknown" 15 "Invalid" ;
VAL_ 552 DispGearPos_D_Rq 0 "turn off" 1 "1st" 2 "2nd" 3 "3rd" 4 "4th" 5 "5th" 6 "6th" 7 "7th" 8 "8th" 9 "9th" 10 "10th" 11 "11th" 12 "12th" 13 "Reserve" 14 "Initial /Unknown" 15 "Invalid" ;
VAL_ 548 RJMALSSR 0 "Normal" 1 "Fail (over one amng four wheel)" ;
VAL_ 548 REJUFEXT 0 "There is no judgment function." 1 "There is a judgment function." ;
VAL_ 548 VXRLHDS 0 "RL sens discon_shrt-circ notON" 1 "RL sens discon_short-circuit ON" ;
VAL_ 548 VXRRHDS 0 "RR sens discon_shrt-circ notON" 1 "RR sens discon_short-circuit ON" ;
VAL_ 548 VXFLHDS 0 "FL sens discon_shrt-circ notON" 1 "FL sens discon_short-circuit ON" ;
VAL_ 548 VXFRHDS 0 "FR sens discon_shrt-circ notON" 1 "FR sens discon_short-circuit ON" ;
VAL_ 548 GVSPDINV 0 "valid" 1 "invalid" ;
VAL_ 548 EPBDDACT 0 "Out of EPB Dynamic Deceleration." 1 "Under EPB Dynamic Deceleration." ;
VAL_ 548 CWAACT 0 "Not under CWA control" 1 "Under CWA control" ;
VAL_ 548 MCBACT 0 "Not under MCB control" 1 "Under MCB control" ;
VAL_ 548 VDMACT 0 "Not under VDM control" 1 "Under VDM control" ;
VAL_ 548 ABSOPE 0 "state0" 1 "state1" 2 "state2" 3 "state3" 4 "state4" 5 "state5" 6 "state6" 7 "state7" 8 "state8" 9 "state9" 10 "state10" 11 "state11" 12 "state12" 13 "state13" 14 "state14" 15 "state15" 16 "state16" 17 "state17" 18 "state18" 19 "state19" 20 "state20" 21 "state21" 22 "state22" 23 "state23" 24 "state24" 25 "state25" 26 "state26" 27 "state27" 28 "state28" 29 "state29" 30 "state30" 31 "state31" ;
VAL_ 548 EPBF 0 "Normal" 1 "Abnormal" ;
VAL_ 548 APPSPCER 0 "Indeterminate state" 1 "Reseved" 2 "check result = match" 3 "check result = Unmatch" ;
VAL_ 548 WSTP 0 "Off" 1 "On" ;
VAL_ 548 FSTP 0 "Stop l sw sig not disconnect" 1 "Stop l sw sig disconnect" ;
VAL_ 548 EPBSW 0 "Indeterminate state." 1 "Switch ope to lock side" 2 "Switch ope to release side" 3 "Switch  no operated" ;
VAL_ 548 EPBLOCK 0 "Parking Brake is Released" 1 "Parking Brake is Applied" 2 "Anti-Lock Park Brk Controled" 3 "Park Brk act activ or unknown" ;
VAL_ 541 SMTERR_Estl 0 "Normal" 1 "ESTL Error" ;
VAL_ 541 SMTERR_Annt 0 "Normal" 1 "Anntena Lost Communication" ;
VAL_ 541 SMTERR_Sys 0 "Normal" 1 "System Error" ;
VAL_ 541 KEYINS_In 0 "No key inside the vehicle" 1 "Key is inside the vehicle" ;
VAL_ 541 KEYINS_Trunk 0 "No key inside the trunk room" 1 "Key is inside the trunk room" ;
VAL_ 541 KEYPOS 0 "No detection/outside of RCP area" 1 "Inside of RCP area" ;
VAL_ 541 KEYOPE 0 "No Key Opreation" 1 "Key Operation" ;
VAL_ 541 IDTRCPFG 0 "Other" 1 "IGON on RPC" ;
VAL_ 541 BDSTUNDBY 0 "Body stundby is not complete" 1 "Body stundby was complete" ;
VAL_ 541 IDTDSPID 0 "No Request" 1 "Abnormal Termination" 2 "System Error(Mentainance)" 3 "System Error(Check)" 4 "Reserved" 5 "Key cannot be detected" 6 "System Invalid1(PowerState)" 7 "System Invalid2(Charge Plug)" 8 "System Invalid3(Key in Car)" 9 "Reserved" 10 "Reserved" 11 "Reserved" 12 "Reserved" 13 "Reserved" 14 "Reserved" 15 "Reserved" ;
VAL_ 541 IDTRQBT 0 "No Request" 1 "BT Communication Start Request" ;
VAL_ 540 SW_AP 0 "OFF" 1 "ON" ;
VAL_ 540 CD_SIZE 0 "normal" ;
VAL_ 540 MIC_POS 0 "normal" ;
VAL_ 540 VR_STATE 0 "normal" ;
VAL_ 540 CUST_APP 0 "normal" ;
VAL_ 540 CUST_TRA 0 "normal" ;
VAL_ 540 SW_PVM 0 "OFF" 1 "ON" ;
VAL_ 540 MMD_MODE 0 "normal mode" 1 "MM diag mode" ;
VAL_ 540 DN_DISP 0 "day display state" 1 "night display state" ;
VAL_ 540 MM_RESET 0 "normal" 1 "accept reset info MM" ;
VAL_ 540 DI_MODE 0 "normal mode" 1 "camera diag transmission mode" ;
VAL_ 540 CMD_MODE 0 "normal mode" 1 "camera diag mode" ;
VAL_ 540 IRQ_MM 0 "normal" 1 "interrupt request MM" ;
VAL_ 540 CC_MODE 0 "normal mode" 1 "camera mode" ;
VAL_ 540 AVN_ON 0 "Invalid" 1 "Valid" ;
VAL_ 537 WhlRotatRl_Direction 0 "Unknown" 1 "Forward" 2 "Backward" 3 "Fault" ;
VAL_ 537 WhlRotatRr_Direction 0 "Unknown" 1 "Forward" 2 "Backward" 3 "Fault" ;
VAL_ 537 WhlRotatFl_Direction 0 "Unknown" 1 "Forward" 2 "Backward" 3 "Fault" ;
VAL_ 537 WhlRotatFr_Direction 0 "Unknown" 1 "Forward" 2 "Backward" 3 "Fault" ;
VAL_ 526 DAMODE 0 "Un-controlling mode" 1 "Pressure holding mode" 2 "Pressure cancel mode" 3 "EPB lock mode" ;
VAL_ 526 BRKON 0 "brake control exection absent" 1 "brk cont exe(plant inspectmode)" ;
VAL_ 526 BRKSBFC 0 "No abnormality" 1 "No avail Drive sup brk sys" 2 "No avail Drive sup brksys(temp)" 3 "No avail Drive sup brksys(Fail)" ;
VAL_ 526 BRKMNFC 0 "No abnormality" 1 "No avail Drive sup brk sys" 2 "No avail Drive brk sys(temp)" 3 "No avail Drive brk sys(Fail)" ;
VAL_ 526 SFTFC 0 "sft change req accept" 1 "No definition" 2 "sft change req not accept(temp)" 3 "sft change req not accept(Fail)" ;
VAL_ 526 DRVFC 0 "driving force req is acceptable" 1 "PT abnormality(MIL lighting)" 2 "drvforce req is not accep(temp)" 3 "drvforce req is not accep(Fail)" ;
VAL_ 526 VMCLGFC 0 "No abnormality" 1 "No definition" 2 "Accuracy  has decreased (temp)" 3 "Accuracy has decreased (Fail)" ;
VAL_ 526 EPBFC 0 "No abnormality" 1 "No definition" 2 "No availability for EPB (temp)" 3 "No availability for Brk (Fail)" ;
VAL_ 526 DAFAIL 0 "There is not DTC on the BH" 1 "There is DTC on the BH" ;
VAL_ 526 DASTBHAL 0 "BH control permission" 1 "BH contorl prohibition" ;
VAL_ 526 HLDSTB 0 "Not permit BH control" 1 "Permit BH control" ;
VAL_ 526 CCS 0 "no demand" 1 "demand" ;
VAL_ 526 FBKRLY 0 "Not Stp l drv relay stuck err" 1 "Stp l drv relay stuck err" ;
VAL_ 526 TSVSC 0 "Not test mode" 1 "Test mode" ;
VAL_ 526 DBRKINFC 0 "No abnormality" 1 "No definition" 2 "Unable detect brk ped op(temp)" 3 "Unable detect brk ped op(fail)" ;
VAL_ 526 BRKHT 0 "no limitation" 1 "under limitation" ;
VAL_ 526 XGVCINV 1 "Invalid" 0 "Valid" ;
VAL_ 526 SPDLMTD 0 "Not under controlled limiter" 1 "Under controlled limiter" ;
VAL_ 520 Abs_B_Falt 0 "No" 1 "Yes" ;
VAL_ 520 TsaCtlActv_B_Actl 0 "No" 1 "Yes" ;
VAL_ 520 RolStabCtlActv_B_Actl 0 "No" 1 "Yes" ;
VAL_ 520 PrplDrgCtlActv_B_Actl 0 "Inactive" 1 "Active" ;
VAL_ 520 TracCtlPtActv_B_Actl 0 "No" 1 "Yes" ;
VAL_ 520 TracCtlBrkActv_B_Actl 0 "No" 1 "Yes" ;
VAL_ 520 DSC_OnOff_status_1 0 "ON" 1 "OFF" ;
VAL_ 520 StabCtlBrkActv_B_Actl 0 "No" 1 "Yes" ;
VAL_ 520 BrkAsst_B_Actl 0 "No" 1 "Yes" ;
VAL_ 520 AbsActv_B_Actl 0 "No" 1 "Yes" ;
VAL_ 520 EbdActv_B_Actl 0 "No" 1 "Yes" ;
VAL_ 508 PBALEVEL 0 "Not PBA operation" 1 "Assist Lv.1" 2 "Assist Lv.2" 3 "Assist Lv.3" 4 "Assist Lv.4" ;
VAL_ 508 VMC_LTID 0 "No request" 63 "Driver's operation" ;
VAL_ 508 LTCLFC 0 "Acceptable" 1 "High load request is restricted" 2 "Not excuted(temporary)" 3 "Not excuted (with Diagnosis)" ;
VAL_ 508 SSMST 0 "Out of fail safe treatment" 1 "Vehicle wheel lock treatment" 2 "Brake release notice" 3 "Brake release is on going" ;
VAL_ 508 BDLCVRCP 0 "Invalid" 1 "Valid" 2 "Reserved" 3 "Reserved" ;
VAL_ 508 BDLCFRCP 0 "Not Failure" 1 "Failure" ;
VAL_ 508 ADSBKINV 0 "valid" 1 "invalid" ;
VAL_ 508 PCSBKLE 0 "normal" 1 "abnormal" ;
VAL_ 508 SSBKST 0 "SSC backup NOT complete" 1 "SSC backup EPB complete" 2 "SSC backup P Lock complete" 3 "Under backup request" ;
VAL_ 508 SSMFC 0 "No abnormality" 1 "No definition" 2 "No availability(temporary)" 3 "No availability(Fail detected)" ;
VAL_ 508 PCSGUARD 0 "Not ASIL guard operation" 1 "under ASIL guard operation" ;
VAL_ 508 VMC_LGID 0 "No request" 63 "Driver's operation" ;
VAL_ 508 ACCBKLE 0 "normal" 1 "abnormal" ;
VAL_ 508 XSTOP 0 "Not vehicle stopping" 1 "Vehicle stopping" ;
VAL_ 508 VMCLGIDP 0 "No request" 63 "Driver's operation" ;
VAL_ 508 VMACSYS 0 "Invalid" 1 "Valid" ;
VAL_ 508 VMCLGIDB 0 "No request" 63 "Driver's operation" ;
VAL_ 508 VMCINTMT 0 "Not control" 1 "under control" ;
VAL_ 508 DRVBKOP 0 "Not applying the brake pedal" 1 "Appling the brake pedal" ;
VAL_ 508 TBKCSYS2 0 "Invalid" 1 "Valid" ;
VAL_ 508 FBKDRSYS 0 "Invalid" 1 "Valid" ;
VAL_ 508 RCONFLG 0 "not controlled remotely" 1 "controlled remotely" ;
VAL_ 505 WSTL2 0 "OFF" 1 "ON" ;
VAL_ 505 WSTL2_F 0 "Normal" 1 "Invalid" 2 "Abnormal" ;
VAL_ 505 Y_TGTIDL 0 "No request" 1 "Application1" 2 "Application2" 3 "Application3" 4 "Application4" 5 "Application5" 6 "Application6" 7 "Application7" 8 "Application8" 9 "Application9" 10 "Application10" 11 "Application11" 12 "Application12" 13 "Application13" 14 "Application14" 15 "Application15" 16 "Application16" 17 "Application17" 18 "Application18" 19 "Application19" 20 "Application20" 21 "Application21" 22 "Application22" 23 "Application23" 24 "Application24" 25 "Application25" 26 "Application26" 27 "Application27" 28 "Application28" 29 "Application29" 30 "Application30" 31 "Application31" 32 "Application32" 33 "Application33" 34 "Application34" 35 "Application35" 36 "Application36" 37 "Application37" 38 "Application38" 39 "Application39" 40 "Application40" 41 "Application41" 42 "Application42" 43 "Application43" 44 "Application44" 45 "Application45" 46 "Application46" 47 "Application47" 48 "Application48" 49 "Application49" 50 "Application50" 51 "Application51" 52 "Application52" 53 "Application53" 54 "Application54" 55 "Application55" 56 "Application56" 57 "Application57" 58 "Application58" 59 "Application59" 60 "Application60" 61 "Application61" 62 "Application62" 63 "Driver's operation" ;
VAL_ 505 Y_FSIDL 0 "Normal" 1 "Accel override prohibition req" 2 "Application duration" 3 "Reserved" 4 "Acceleration request" 5 "Reserved" 6 "Reserved" 7 "Reserved" 8 "Reserved" 9 "Reserved" 10 "Reserved" 11 "Reserved" 12 "Reserved" 13 "Reserved" 14 "Reserved" 15 "Reserved" 16 "Automatic parking request" 17 "Reserved" 18 "Reserved" 19 "Reserved" 20 "Reserved" 21 "Reserved" 22 "Reserved" 23 "Reserved" 24 "Reserved" 25 "Reserved" 26 "Reserved" 27 "Reserved" 28 "Reserved" 29 "Reserved" 30 "Reserved" 31 "Reserved" 32 "Received Value" ;
VAL_ 505 B_PDLF 0 "Normal" 1 "Fail" ;
VAL_ 505 IGP_PT1 0 "No" 1 "Yes" ;
VAL_ 505 PTCURSFT 0 "Unknown" 1 "S_Range" 2 "M_Range" 3 "D_Range" 4 "B_Range" 5 "R_Range" 6 "P_Range" 7 "N_Range" ;
VAL_ 505 KDNSW 0 "No" 1 "Yes" ;
VAL_ 505 XPAIDLV 0 "No" 1 "Yes" ;
VAL_ 505 XPAIDL 0 "No" 1 "Yes" ;
VAL_ 505 CRUCAN 0 "No request" 1 "undefined" 2 "undefined" 3 "undefined" 4 "undefined" 5 "MT-Common_cancel" 6 "MT-CC_cancel" 7 "MT-ACC_cancel" ;
VAL_ 505 DGTMD 0 "No" 1 "Yes" ;
VAL_ 357 HeaterCntVlv_State 0 "Eng_VlvOpen,EV_VlvOpen(NO)" 1 "Eng_VlvOpen,EV_VlvClose(HEV)" 2 "Eng_VlvClose,EV_VlvOpen(EV)" 3 "Eng_VlvClose,EV_VlvClose(ND)" ;
VAL_ 357 FuelLid_UnLock_B_Req 0 "Not Drive" 1 "Lock" 2 "UnLock" ;
VAL_ 357 TrnAinTq_D_Qf1 0 "Faulty" 1 "No data exists" 2 "Not within specifications" 3 "OK" ;
VAL_ 357 HeaterCoreTeEst_D_Qf 0 "Faulty" 1 "No_Data_Exists" 2 "Not_Within_Specifications" 3 "OK" ;
VAL_ 357 ClosedFuelTankSystem_PCM 0 "None" 1 "Equipped" ;
VAL_ 357 ApedPosPcActl_D_Qf 0 "Faulty" 1 "NoDataExist" 2 "NotWithinSpecification" 3 "OK" ;
VAL_ 357 DcdcWarningDisp_B_Rq_202 0 "Off" 1 "On" ;
VAL_ 357 EngAout_D_ReqTachoGain 0 "Normal" 1 "gain_1" 2 "gain_2" 3 "gain_3" ;
VAL_ 357 VehVLim_Warning 0 "Off" 1 "On" ;
VAL_ 357 AirCondRec_B_Rq 0 "OFF" 1 "ON" ;
VAL_ 357 AWD_State_Req_165 0 "Stop" 1 "MODE2" 2 "MODE3" 3 "System_Start" 4 "System_Stop" 5 "OFF" 6 "MODE6" 7 "MODE7" 8 "MODE8" 9 "MODE9" 10 "MODE10" 11 "MODE11" 12 "MODE12" 13 "MODE13" 14 "MODE14" 15 "MODE15" ;
VAL_ 357 VehVLim_OverVS_KD 0 "not Over Speed with K/D" 1 "Over Speed with K/D" ;
VAL_ 357 NeutralSwActv_D_Actl 0 "Unknown, default value" 1 "not Neutral" 2 "Neutral" 3 "Invalid" ;
VAL_ 357 GearPos_D_TrgMt 0 "Park/Neutral" 1 "1st" 2 "2nd" 3 "3rd" 4 "4th" 5 "5th" 6 "6th" 7 "7th" 8 "8th" 14 "Reverse" 15 "Unknown" ;
VAL_ 357 GearRvrseActv_B_Actl 0 "Off" 1 "On" ;
VAL_ 357 BrakeSw_Fail_Warning2 0 "Normal" 1 "Abnormal" ;
VAL_ 357 BrkOnOffSwtch_D_Actl_2 0 "not allowed" 1 "driver not braking" 2 "driver braking" 3 "not allowed" ;
VAL_ 253 HEVIG_B_Actl 0 "off" 1 "on" ;
VAL_ 253 IG_OnOff_PT 0 "off" 1 "on" ;
VAL_ 253 RexRelay_Req 0 "off" 1 "on" ;
VAL_ 253 EngCrank_Req 0 "off" 1 "on" ;
VAL_ 253 ChgHiVoltCont_Req 0 "off" 1 "on" ;
VAL_ 253 HiVoltCont_Req 0 "off" 1 "on" ;
VAL_ 253 CDTHVANS 0 "off" 1 "on" ;
VAL_ 253 Permit_Isolate_Detect 0 "off" 1 "on" ;
VAL_ 253 Chrg_Enable 0 "off" 1 "on" ;
VAL_ 253 Eng_Enable 0 "off" 1 "on" ;
VAL_ 253 HiVolt_Enable 0 "off" 1 "on" ;
VAL_ 253 CellBalance_Req 0 "off" 1 "on" ;
VAL_ 253 CoastDownMode 0 "off" 1 "on" ;
VAL_ 253 Discharge_Req 0 "off" 1 "on" ;
VAL_ 253 BatteryHeater_On_Sig 0 "off" 1 "on" ;
VAL_ 253 AirConditioner_On_Sig 0 "off" 1 "on" ;
VAL_ 253 Supply_On_Sig 0 "off" 1 "on" ;
VAL_ 253 Charge_On_Sig 0 "off" 1 "on" ;
VAL_ 253 Ready_On_Sig 0 "off" 1 "on" ;
VAL_ 253 GenStartStop_Req 0 "off" 1 "on" ;
VAL_ 253 SupStartStop_Req 0 "off" 1 "on" ;
VAL_ 253 ChgStartStop_Req 0 "off" 1 "on" ;
VAL_ 253 DrvStartStop_Req 0 "off" 1 "on" ;
VAL_ 253 EatcStartStop_Req 0 "off" 1 "on" ;
VAL_ 253 EcuStartStop_Req 0 "off" 1 "on" ;
VAL_ 253 Veh_State_Sig 0 "OFF" 1 "ECU Wakeup" 2 "ECU ON" 3 "Power Up" 4 "Power ON" 5 "Power Shutdown" 6 "ECU Shutdown" 7 "Reserved" 8 "Reserved" 9 "Reserved" 10 "Reserved" 11 "Reserved" 12 "Reserved" 13 "Reserved" 14 "Reserved" 15 "Reserved" ;
VAL_ 253 Veh_Mode_Sig 0 "OFF" 1 "ECU-ON Mode" 2 "Drive Mode" 3 "DC Charge Mode" 4 "AC Charge Mode" 5 "Air-conditioning Mode" 6 "High Voltage Battery Heater Mode" 7 "12V Charge Mode" 8 "AC Power Outlet Mode" 9 "Reserved" 10 "Reserved" 11 "Reserved" 12 "Reserved" 13 "Reserved" 14 "Reserved" 15 "Reserved" ;
VAL_ 253 CidSwStat_iStpCancel_ONOFF_GUI 0 "Normal" 1 "Gray" 2 "NoDisplay" ;
VAL_ 253 PTiStpRdy_B_Actl 0 "Not ready" 1 "Ready" ;
VAL_ 253 iStpDenyBrk_B_Actl 0 "OFF" 1 "ON" ;
VAL_ 253 iStpDenyPwStr_B_Actl 0 "OFF" 1 "ON" ;
VAL_ 253 iStpKeySta_B_Actl 0 "OFF" 1 "ON" ;
VAL_ 253 iStpDenyAC_B_Actl 0 "OFF" 1 "ON" ;
VAL_ 253 iStpDenyNrange_B_Actl 0 "OFF" 1 "ON" ;
VAL_ 253 iStpDenyDPF_B_Actl 0 "OFF" 1 "ON" ;
VAL_ 253 CidSwStat_iStpCancel_ONOFF 0 "Not Adopted" 1 "ON" 2 "OFF" ;
VAL_ 253 ELM_IRCutReq 0 "No" 1 "Yes" ;
VAL_ 253 BatteryWeakenFlag 0 "OFF" 1 "ON" ;
VAL_ 253 iStpDoorOpen_B_Actl 0 "No" 1 "Yes" ;
VAL_ 253 SISS_EngineState 1 "Ready" 2 "Key Cranking" 3 "Engine Running" 5 "ISS engine stop fullfill" 6 "ISS engine stopping" 7 "ISS engine stopped" 8 "ISS engine restart ready" 9 "ISS engine restarting" 10 "ISS engine running" ;
VAL_ 253 SISS_IRCutReq 0 "No" 1 "Yes" ;
VAL_ 253 SKE_Control 0 "Not_Request" 1 "Request_IS" 2 "Request_IR" ;
VAL_ 253 SISS_Mode_for_SKE 0 "OFF" 1 "ON" ;
VAL_ 253 iStpReady_Rq 0 "Not Ready" 1 "Ready" ;
VAL_ 253 iStpDenyBatt_B_Actl 0 "OFF" 1 "ON" ;
VAL_ 253 SlaCtl_B_Rq 0 "Not Request for SLA Activation" 1 "Request for SLA Activation" ;
VAL_ 253 SISS_WarningLamp_R 0 "OFF" 1 "Pattern1" 2 "Pattern2" 3 "Pattern3" 4 "Pattern4" 5 "Pattern5" ;
VAL_ 253 SISS_WarningLamp_G 0 "OFF" 1 "Pattern1" 2 "Pattern2" 3 "Pattern3" 4 "Pattern4" 5 "Pattern5" ;
VAL_ 253 SISS_AlarmBuzzer 0 "OFF" 1 "Pattern1" 2 "Pattern2" 3 "Pattern3" 4 "Pattern4" ;
VAL_ 253 SISSStatus 0 "Normal Status" 1 "Idle Stop Enst Status" ;
VAL_ 253 SrlyUpper_Connect_Rq 0 "Unknown,default" 1 "Disconnect Request" 2 "Connect Request" ;
VAL_ 253 PlaCtl_B_Rq 0 "Not Request for PLA Activation" 1 "Request for PLA Activation" ;
VAL_ 253 Xev_Charge_Req_PCM 0 "NG" 1 "OK" 2 "NG_ACC" 3 "reserved" 6 "Not Determined" 7 "Invalid" ;
VAL_ 253 PTGeneralWarn_Mirror 0 "ON" 1 "OFF" ;
VAL_ 253 Drive_Mode_Req_PCM 0 "Nml:NG/Spt:NG/3rd:NG/4th:NG" 1 "Nml:OK/Spt:NG/3rd:NG/4th:NG" 2 "Nml:NG/Spt:OK/3rd:NG/4th:NG" 3 "Nml:OK/Spt:OK/3rd:NG/4th:NG" 4 "Nml:NG/Spt:NG/3rd:OK/4th:NG" 5 "Nml:OK/Spt:NG/3rd:OK/4th:NG" 6 "Nml:NG/Spt:OK/3rd:OK/4th:NG" 7 "Nml:OK/Spt:OK/3rd:OK/4th:NG" 8 "Nml:NG/Spt:NG/3rd:NG/4th:OK" 9 "Nml:OK/Spt:NG/3rd:NG/4th:OK" 10 "Nml:NG/Spt:OK/3rd:NG/4th:OK" 11 "Nml:OK/Spt:OK/3rd:NG/4th:OK" 12 "Nml:NG/Spt:NG/3rd:OK/4th:OK" 13 "Nml:OK/Spt:NG/3rd:OK/4th:OK" 14 "Nml:NG/Spt:OK/3rd:OK/4th:OK" 15 "Nml:OK/Spt:OK/3rd:OK/4th:OK" ;
VAL_ 253 Drive_Mode_Towing_Req_PCM 0 "NG" 1 "OK" 2 "Not Determined" 3 "Invalid" ;
VAL_ 253 Drive_Mode_OffRoad_Req_PCM 0 "NG" 1 "OK" 2 "Not Determined" 3 "Invalid" ;
VAL_ 253 Drive_Mode_Sport_Req_PCM 0 "NG" 1 "OK" 2 "NG Temporary" 3 "Invalid" ;
VAL_ 253 Drive_Mode_Normal_Req_PCM 0 "NG" 1 "OK" 2 "Not Determined" 3 "Invalid" ;
VAL_ 253 ATFalseStartWarning 0 "Off" 1 "On" ;
VAL_ 253 BattRgenStat_B_Actl 0 "OFF" 1 "ON" ;
VAL_ 253 RegenBrkFailWarning 0 "OFF" 1 "ON" ;
VAL_ 253 BmsWarn_B_Rq 0 "OFF" 1 "ON" ;
VAL_ 253 SmtAclInh_B_Actl 0 "OFF" 1 "ON" ;
VAL_ 253 BrakeSw_Fail_Warning 0 "Brake switch Normal" 1 "Brake switch Failure" ;
VAL_ 253 BOS_Active_B_Actl 0 "NotActivated" 1 "Activated" ;
VAL_ 253 DriveMode_Hold_Rq_PCM 0 "OFF" 1 "ON" ;
VAL_ 253 GlobalConfgWarn_B_Rq 0 "OFF" 1 "ON" ;
VAL_ 253 ApedOnN_B_Rq 0 "OFF" 1 "ON" ;
VAL_ 253 IG_OFF_Delay_Request 0 "OFF" 1 "ON" ;
VAL_ 253 Crank_wait 0 "No wait, default" 1 "Wait to crank" ;
VAL_ 253 SilGearPosActl_D_Dsply 0 "Off" 1 "1st" 2 "2nd" 3 "3rd" 4 "4th" 5 "5th" 6 "6th" 7 "7th" 8 "8th" 9 "Circuit Check at IG ON" ;
VAL_ 253 Xev_Ev_Req_PCM 0 "NG" 1 "OK" 2 "NG_ACC" 3 "NG_Low Battery Power" 4 "NG_A/C request" 5 "reserved" 6 "Not Determined" 7 "Invalid" ;
VAL_ 253 VspLmtAlarm_B_Rq 0 "OFF" 1 "ON" ;
VAL_ 253 PTGeneralWarn_B_Rq 0 "OFF" 1 "ON" ;
VAL_ 253 SRLY_state 0 "OFF(inactive), default" 1 "ON(active)" ;
VAL_ 253 SilGearPos_D_Dsply 0 "Off" 1 "1st" 2 "2nd" 3 "3rd" 4 "4th" 5 "5th" 6 "6th" 7 "7th" 8 "8th" 9 "Circuit Check at IG ON" ;
VAL_ 253 VspLmtWarn_B_Rq 0 "OFF" 1 "vsplmtwarn1" 2 "vsplmtwarn2" 3 "Not defined" ;
VAL_ 253 KeyState 0 "Unknown-default" 1 "Disable_Crank" 2 "Enable_Crank (w/ iSTOP/Enst)" 3 "Running" 4 "Invalid" 5 "Invalid" 6 "Shutdown(Igoff condition)" 7 "Invalid" ;
VAL_ 253 ShiftIndicatorLight 0 "Off" 1 "Up Shift" 2 "Down Shift" 3 "Circuit Check at IG ON" ;
VAL_ 253 PowerSourceStatus 0 "Off" 1 "Standby" 2 "Startup" 3 "Ready-ON" 4 "Inhibit" ;
VAL_ 218 BKSBWCF 0 "Normal" 1 "Fail" ;
VAL_ 218 SBWSYSOR 0 "No Override" 1 "Override" ;
VAL_ 218 DORRQSFT 0 "No Override request" 1 "P range request" 2 "R range request" 3 "N range request" 4 "D range request" 5 "B/M/S range request" 6 "Reserved" 7 "Reserved" ;
VAL_ 218 SBWPROK 0 "Not ready to unlock P lock" 1 "Ready to unlock P lock" ;
VAL_ 218 SBWPRTNG 0 "Not in progress unlocking P lock" 1 "In progress unlocking P lock" ;
VAL_ 218 STSPTAPP 0 "Normal" 1 "Clutch engaged" 2 "Reserved" 3 "PartsProtectionControlCVTOnly" 4 "Temporarily unavailable" 5 "Reserved" 6 "Reserved" 7 "Reserved" ;
VAL_ 218 ATBRKOK 0 "Prohibit" 1 "Permit" ;
VAL_ 218 SOCLOWID 0 "Reserved" 1 "Reserved" 2 "Reserved" 3 "Reserved" 4 "Reserved" 5 "Reserved" 6 "No continue(Low_State_Of_Charge)" 7 "Reserved" ;
VAL_ 192 Auto_XevNormal_Mode_D_Rq 0 "OFF" 1 "Ev_Mode_Malfunction" 2 "Low Battery Power" 3 "EV_Cancel_General" 4 "Charge_Mode_Malfunction" 5 "A/C request" 6 "Charge_Cancel_General" 7 "reserved" ;
VAL_ 192 Not_Select_Xevmode_D_Rq 0 "OFF" 1 "ALL_Mode_Malfunction" 2 "Mode_ACC" 3 "ALL_Mode_Temporarily" 4 "CHARGE_Mode_Malfunction" 5 "CHARGE_Mode_Temporarily" 6 "Low Battery Power" 7 "A/C request" ;
VAL_ 192 Auto_Normal_Mode_D_Rq 0 "OFF" 1 "ALL_Mode_Malfunction" 2 "Sport_Mode_ACC" 3 "Cancel_General" 4 "reserved" 5 "reserved" 6 "reserved" 7 "reserved" ;
VAL_ 192 Not_Select_Drivemode_D_Rq 0 "OFF" 1 "ALL_Mode_Malfunction" 2 "Sport_Mode_ACC" 3 "ALL_Mode_Temporarily" 4 "Towing_Mode_Not_Detect" 5 "reserved" 6 "reserved" 7 "reserved" ;
VAL_ 192 Trailer_Connect_D_Rq 0 "OFF" 1 "Trailer Connected" 2 "ADAS Partially_Towing Mode" 3 "ADAS Partially" 4 "ADAS Rear_Towing Mode" 5 "ADAS Rear" 6 "reserved" 7 "reserved" ;
VAL_ 192 Drive_Mode_List_Popup 0 "Off" 1 "List_Popup" 2 "Limit_Upper" 3 "Limit_Lower" 4 "List_Popup_Normal" 5 "List_Popup_Sport" 6 "List_Popup_Offroad" 7 "List_Popup_Towing" 8 "List_Popup_EV" 9 "reserved" 10 "reserved" 11 "reserved" 12 "reserved" 13 "reserved" 14 "reserved" 15 "Invalid" ;
VAL_ 192 Xev_Mode_Charge_Permission 0 "OK" 1 "NG" 2 "Not_Determined" 3 "Invalid" ;
VAL_ 192 Xev_Mode_Ev_Permission 0 "OK" 1 "NG" 2 "Not_Determined" 3 "Invalid" ;
VAL_ 192 Xev_Mode_Status 0 "Normal mode" 1 "Ev mode" 2 "Charge mode" 3 "reserved" 14 "Not_Determined" 15 "Invalid" ;
VAL_ 192 Drive_Mode_Towing_Permission 0 "OK" 1 "NG" 2 "Not_Determined" 3 "Invalid" ;
VAL_ 192 Drive_Mode_Offroad_Permission 0 "OK" 1 "NG" 2 "Not_Determined" 3 "Invalid" ;
VAL_ 192 Drive_Mode_Sport_Permission 0 "OK" 1 "NG" 2 "Not_Determined" 3 "Invalid" ;
VAL_ 192 Drive_Mode_Normal_Permission 0 "OK" 1 "NG" 2 "Not_Determined" 3 "Invalid" ;
VAL_ 192 Drive_Mode_List_Info 0 "NORMAL/NONE" 1 "SPORT_NORMAL" 2 "SPORT_NORMAL_OFFROAD" 3 "TOWING_SPORT_NORMAL_OFFROAD" 4 "NORMAL+OFFROAD" 5 "TOWING_NORMAL+OFFROAD" 6 "CHARGE_NORMAL_EV" 7 "TOWING_SPORT_NORMAL_EV_OFFROAD" 8 "SPORT_NORMAL_EV_OFFROAD" 9 "reserved" 10 "reserved" 11 "reserved" 12 "reserved" 13 "reserved" 14 "Not_Determined" 15 "Invalid" ;
VAL_ 192 Drive_Mode_Status 0 "Normal mode" 1 "Sport mode" 2 "Offroad mode" 3 "Towing mode" 4 "EV mode" 5 "reserved" 6 "reserved" 7 "reserved" 8 "reserved" 9 "reserved" 10 "reserved" 11 "reserved" 12 "reserved" 13 "reserved" 14 "Not_Determined" 15 "Invalid" ;
VAL_ 159 BpedDrvAppl_D_Actl 0 "not allowed" 1 "driver not braking" 2 "driver braking" 3 "not allowed" ;
VAL_ 159 IndirectIllumination_D_Rq 0 "Unknown" 1 "0%Fade out" 2 "100%Fade in" 3 "KINDIRECTILLUMRATE_DARK% Fade" 4 "KINDIRECTILLUMRATE_MEDIUM% Fade" 5 "KINDIRECTILLUMRATE_BLIGHT% Fade" ;
VAL_ 159 WelcomIllumination_D_Rq 0 "Unknown" 1 "0%Fade out" 2 "100%Fade in" 3 "KWELCOMLLUMRATE% Fade" ;
VAL_ 159 FootLamp_D_Rq 0 "Unknown" 1 "0%Fade out" 2 "100%Fade in" 3 "KFOOTLAMPRATE_DARK%Fade" 4 "KFOOTLAMPRATE_MEDIUM% Fade" 5 "KFOOTLAMPRATE_BLIGHT% Fade" ;
VAL_ 159 DoorCourtesyLamp_D_Rq 0 "Unknown" 1 "0%Fade out" 2 "100%Fade in" ;
VAL_ 159 CargoLamp_D_Rq 0 "Unknown" 1 "0%Fade out" 2 "100%Fade in" ;
VAL_ 159 DimmerCancel 0 "Unknown" 1 "OFF" 2 "ON" ;
VAL_ 159 Drive_Mode_FlashReq 0 "Off" 1 "3times_Start(400msOn/Off)" 2 "On" ;
VAL_ 159 Drive_Mode_Enabled 0 "Normal mode" 1 "Sports mode" 2 "3rd mode" 3 "4th mode" ;
VAL_ 159 CarMde_D_Actl 0 "Normal" 1 "Factory" 2 "Not Used" 3 "Transport" 4 "Not Used" 5 "Not Used" ;
VAL_ 159 REVSWVLD 0 "Invalid" 1 "Valid" ;
VAL_ 159 Reverselamp_B_Req 0 "OFF" 1 "ON" ;
VAL_ 159 IlumiMde_D_Actl 0 "Unknown" 1 "OFF, daylight mode" 2 "ON, night mode" ;
VAL_ 159 Illum_PowerControlStatus 0 "OFF" 1 "ON" ;
VAL_ 159 AudioMute_B_Actl 0 "Off" 1 "On" ;
VAL_ 159 RoomFuseStat_D_Actl 0 "Without Room Fuse" 1 "With Room Fuse" 2 "Unused" 3 "Unknown" ;
VAL_ 154 LED_HI_B 0 "LED _NORMAL_TurnOff" 1 "Not Used" 2 "LED_Abnormal_TurnOn" 3 "Bulb_Check" ;
VAL_ 154 SndRSP_Fail_B_Actl 0 "Off" 1 "On" ;
VAL_ 154 SndFSP_Fail_B_Actl 0 "Off" 1 "On" ;
VAL_ 154 FuelCalcCmplt_B_Actl 0 "Off" 1 "On" ;
VAL_ 154 Refuel2_B_Actl 0 "Off" 1 "On" ;
VAL_ 154 Refuel1_B_Actl 0 "Off" 1 "On" ;
VAL_ 154 Hazard_lamp_State_D_Actl 0 "Manual Hazard Off" 1 "Manual Hazard On" ;
VAL_ 154 DRL_Tail_Lamp_B_Rq 0 "Off" 1 "On" ;
VAL_ 154 TNS_Buzzer_Cntl_Req 0 "Off" 1 "On" ;
VAL_ 154 Turn_Snd_Cmd_Left 0 "Off" 1 "On" ;
VAL_ 154 Turn_Snd_Cmd_Right 0 "Off" 1 "On" ;
VAL_ 154 WiprGuid_B_Rq 0 "Off" 1 "On" ;
VAL_ 154 BurglarHorn_B_Req 0 "Off" 1 "On" ;
VAL_ 154 RSRmid_Indicator_Req 0 "OFF" 1 "ON at IG On" 2 "ON at IG On Extension" 3 "ON at IG Off" ;
VAL_ 154 RSRmid_DisplayReq 0 "Not Request" 1 "Request Arming" 2 "Request Alert" 3 "Request Completed" ;
VAL_ 154 BlwCont_B_Actl 0 "Blow Motor Relay OFF" 1 "Blow Motor Relay ON" ;
VAL_ 154 FrntWipr_D_Actl 0 "OFF" 1 "Front Wiper Lo ON" 2 "Front Wiper Hi ON" ;
VAL_ 154 SteeringHeatCutLvl 0 "NoRequest" 1 "CutRequestWithIndicatorOn" 2 "CutRequestWithIndicatorOff" 3 "Reserved" ;
VAL_ 154 PtcCutLvl 0 "NoRequest" 1 "CutRequestWithIndicatorOn" 2 "CutRequestWithIndicatorOff" 3 "Reserved" ;
VAL_ 154 BmotCutLvl 0 "NoRequest" 1 "CutRequestWithIndicatorOn" 2 "CutRequestWithIndicatorOff" 3 "Reserved" ;
VAL_ 154 SeatHeatCutLvl 0 "NoRequest" 1 "CutRequestWithIndicatorOn" 2 "CutRequestWithIndicatorOff" 3 "Reserved" ;
VAL_ 154 RdefCutLvl 0 "NoRequest" 1 "CutRequestWithIndicatorOn" 2 "CutRequestWithIndicatorOff" 3 "Reserved" ;
VAL_ 154 SeatVentCutLvl 0 "NoRequest" 1 "CutRequestWithIndicatorOn" 2 "CutRequestWithIndicatorOff" 3 "Reserved" ;
VAL_ 154 WshrLvl_D_Actl 0 "Unknown" 1 "Normal" 2 "Low" 3 "Invalid" ;
VAL_ 154 TNS_IpcDsply_D_Rq 0 "OFF" 1 "Green ON" 2 "Reserved (Yellow ON)" 3 "Reserved" ;
VAL_ 154 Turn_Ind_Cmd_Left 0 "OFF" 1 "ON" ;
VAL_ 154 Turn_Ind_Cmd_Right 0 "OFF" 1 "ON" ;
VAL_ 154 Turnlamp_ESS_B_Req 0 "OFF" 1 "ON" ;
VAL_ 154 Turnlamp_KoDo_B_Req 0 "OFF" 1 "ON" ;
VAL_ 154 LightWarning_D_Rq 0 "OFF" 1 "System check" 2 "Flashing 2Hz" 3 "Flashing 3 times" 7 "Yellow ON (Fail)" ;
VAL_ 154 ResHeatCont_B_Actl 0 "No request" 1 "Requested" ;
VAL_ 154 ResEngCont_B_Actl 0 "Remote Start Off" 1 "Remote Start On" ;
VAL_ 154 CBDA_Sleep_B_Rq 0 "uC Sleep mode" 1 "uC Wakeup mode" ;
VAL_ 154 RearWiprLo_B_Rq 0 "Off" 1 "Rear Wiper Lo On" 2 "Stop" ;
VAL_ 154 AutoWiprIND_B_Rq 0 "OFF" 1 "ON" ;
VAL_ 154 RearFogIpcDsply_B_Rq 0 "OFF" 1 "Yellow ON" ;
VAL_ 154 HiBeamIpcDsply_B_Rq 0 "No Request" 1 "On Request" ;
VAL_ 153 SeatBeltWrn_D_Rq 0 "Off" 1 "ON_NoChime" 2 "ON_WithChimeON" 3 "ON_WithChimeOff" ;
VAL_ 153 PWGGUID_B_Rq 0 "OFF" 1 "ON" ;
VAL_ 153 DrOpnWrn_D_Rq 0 "Off" 1 "ON" 2 "Flash(1Hz)" 3 "reserve" ;
VAL_ 153 LidStop_B_Req 0 "OFF" 1 "ON" ;
VAL_ 153 Outlet_L2_B_Req 0 "OFF" 1 "ON" ;
VAL_ 153 Outlet_L1_B_Req 0 "OFF" 1 "ON" ;
VAL_ 153 Outlet_R2_B_Req 0 "OFF" 1 "ON" ;
VAL_ 153 Outlet_R1_B_Req 0 "OFF" 1 "ON" ;
VAL_ 153 Rearfog_B_Req 0 "OFF" 1 "ON" ;
VAL_ 153 TnsLamp_Frnt_B_Rq 0 "OFF" 1 "ON" ;
VAL_ 153 RLS_Control_req 0 "OFF" 1 "TNS Only ON" 2 "Low + TNS" 3 "Unknown" ;
VAL_ 153 LghtSwState_D_Qf 0 "Faulty" 1 "Undefined/NotConfig" 2 "Not within Specification" 3 "OK" ;
VAL_ 153 Light_LeverSW_Mode_D_Actl 0 "Head OFF" 1 "Passing" 2 "Head Hi" 3 "Reserve" ;
VAL_ 153 Light_CombiSW_Mode_D_Actl 0 "Off" 1 "Auto" 2 "TNS" 3 "Low+TNS" ;
VAL_ 153 FSM_Lamp_B_Rq 0 "OFF" 1 "ON" ;
VAL_ 153 DRL_Lamp_B_Rq 0 "OFF" 1 "ON" ;
VAL_ 153 HeadLampHiCtl_D_Rq 0 "OFF" 1 "ON" ;
VAL_ 153 HeadLampLoCtl_D_Rq 0 "OFF" 1 "ON" ;
VAL_ 153 TnsLamp_Rear_B_Rq 0 "OFF" 1 "ON" ;
VAL_ 152 Vehicle_Stationary 0 "Not stationary" 1 "Stationary" 2 "Unknown" 3 "Fault" ;
VAL_ 152 VehVActlBrk_D_Qf 0 "Faulty" 1 "No_Data_Exists" 2 "Not_Within_Specifications" 3 "OK" ;
VAL_ 150 FuelLidOpen_Rq_SW_B_Actl 0 "No Request" 1 "Open Request" ;
VAL_ 150 TLO_PLG_Sw_B_Actl 0 "Off" 1 "On" ;
VAL_ 150 ADASOfSw_B_Actl 0 "Off" 1 "On" ;
VAL_ 150 MultiSw_D_Qf 0 "Faulty" 1 "Undefined" 2 "Not within Specification" 3 "OK" ;
VAL_ 148 DHS_RIL_STAT 0 "Off" 1 "On" 2 "Plant_Mode" 3 "Fault" 4 "Unknown" 5 "Reserved" ;
VAL_ 148 RIL_STAT 0 "Off" 1 "On" 2 "Plant_Mode" 3 "Fault" 4 "Unknown" 5 "Reserved" 6 "Invalid value" ;
VAL_ 148 MntSet_Oil_HEC_Req 0 "Off" 1 "On" ;
VAL_ 148 HEC_HUD_Disp_MRCC_Status 0 "Not Allowed" 1 "Allowed" ;
VAL_ 148 HEC_HUD_Disp_MRCC_Status2 0 "Not Allowed" 1 "Allowed" ;
VAL_ 145 WiprTestMode_B_Actl 0 "Off" 1 "On" ;
VAL_ 145 PaddleShiftDwn_D_Actl 0 "Off" 1 "On" 2 "Reserved" 3 "Unknown" ;
VAL_ 145 PaddleShiftUp_D_Actl 0 "Off" 1 "On" 2 "Reserved" 3 "Unknown" ;
VAL_ 145 RearWasherSw_B_Actl 0 "Off" 1 "On" ;
VAL_ 145 FrntWasherSw_B_Actl 0 "Off" 1 "On" ;
VAL_ 145 RearWiprStats_D_Actl 0 "Off" 1 "RearWiperLo" 2 "Not defined" 3 "WiperINT" ;
VAL_ 145 FrntWiprStats_D_Actl 0 "OFF" 1 "FrontWiper On Lo" 2 "FrontWiper On Hi" 3 "FrontWiperINT Auto On" ;
VAL_ 145 WiprSw_D_Qf 0 "Faulty" 1 "Undefined" 2 "Not within Specification" 3 "OK" ;
VAL_ 145 ALH_HBC_Sw_B_Actl 0 "OFF" 1 "ON" ;
VAL_ 145 Mfs_Turn_Neutral_SW_Status 0 "Turn Neutral OFF" 1 "Turn Neutral ON" ;
VAL_ 145 Mfs_Turn_Stalk_SW_Status 0 "Turn OFF" 1 "Turn Right ON" 2 "Turn Left ON" 3 "Unknown" ;
VAL_ 145 HeadLghtOffSw_B_Actl 0 "Off" 1 "On" ;
VAL_ 145 PassngSw_B_Actl 0 "Off" 1 "On" ;
VAL_ 145 RearFogSw_B_Actl 0 "Off" 1 "On" ;
VAL_ 145 HeadLghtHiSw_B_Actl 0 "Off" 1 "On" ;
VAL_ 145 HeadLghtLoSw_B_Actl 0 "Off" 1 "On" ;
VAL_ 145 TnsSw_B_Actl 0 "Off" 1 "On" ;
VAL_ 145 LghtSw_D_Qf 0 "Faulty" 1 "Undefined/NotConfig" 2 "Not within Specification" 3 "OK" ;
VAL_ 139 TSSAORFG 0 "Permit accel override" 1 "Prohibit accel override" ;
VAL_ 139 TSSACLPH 0 "No request" 1 "Request" ;
VAL_ 139 TSS_RNGR 0 "No request" 1 "Reserved" 2 "Reserved" 3 "D range" 4 "Reserved" 5 "R range" 6 "P range" 7 "N range" ;
VAL_ 139 TSS_PRE 0 "Off" 1 "On (Pump Speed:low)" 2 "On (Pump Speed:middle)" 3 "On (Pump Speed:high)" ;
VAL_ 139 TSS_RSPH 0 "Do not apply" 1 "Apply High gain" 2 "Apply Middle gain" 3 "Apply Low gain" ;
VAL_ 139 AEBPOSS 0 "No possibility to operate PCS" 1 "Possibility to operate PCS brake" ;
VAL_ 139 TSS_RSPL 0 "Do not apply" 1 "Apply High gain" 2 "Apply Middle gain" 3 "Apply Low gain" ;
VAL_ 139 TSS_ACLP 0 "No request" 1 "Request" ;
VAL_ 139 TSS_SFTH 0 "No shift-down request" 1 "Shift-down request" ;
VAL_ 139 TSSLTBKH 0 "Prohibit" 1 "Permit" ;
VAL_ 139 TSSCSRQH 0 "No request" 1 "Request" ;
VAL_ 139 TSSCSRQL 0 "No request" 1 "Request" ;
VAL_ 139 TSSINTEL 0 "Prohibit" 1 "Permit" ;
VAL_ 139 TSSINTEH 0 "Prohibit" 1 "Permit" ;
VAL_ 139 TSSLGFDH 0 "Only engine" 1 "Engine and brake" 2 "Engine and brake(only brake)" 3 "Only brake" ;
VAL_ 139 TSSLGIDH 0 "No request" 1 "Application1" 2 "Application2" 3 "Application3" 4 "Application4" 5 "Application5" 6 "Application6" 7 "Application7" 8 "Application8" 9 "Application9" 10 "Application10" 11 "Application11" 12 "Application12" 13 "Application13" 14 "Application14" 15 "Application15" 16 "Application16" 17 "Application17" 18 "Application18" 19 "Application19" 20 "Application20" 21 "Application21" 22 "Application22" 23 "Application23" 24 "Application24" 25 "Application25" 26 "Application26" 27 "Application27" 28 "Application28" 29 "Application29" 30 "Application30" 31 "Application31" 32 "Application32" 33 "Application33" 34 "Application34" 35 "Application35" 36 "Application36" 37 "Application37" 38 "Application38" 39 "Application39" 40 "Application40" 41 "Application41" 42 "Application42" 43 "Application43" 44 "Application44" 45 "Application45" 46 "Application46" 47 "Application47" 48 "Application48" 49 "Application49" 50 "Application50" 51 "Application51" 52 "Application52" 53 "Application53" 54 "Application54" 55 "Application55" 56 "Application56" 57 "Application57" 58 "Application58" 59 "Application59" 60 "Application60" 61 "Application61" 62 "Application62" 63 "Driver's operation" ;
VAL_ 139 TSS_SFTL 0 "No shift-down request" 1 "Shift-down request" ;
VAL_ 139 TSSLTBKL 0 "Prohibit" 1 "Permit" ;
VAL_ 139 TSSLGFDL 0 "Only engine" 1 "Engine and brake" 2 "Engine and brake(only brake)" 3 "Only brake" ;
VAL_ 139 TSSLGIDL 0 "No request" 1 "Application1" 2 "Application2" 3 "Application3" 4 "Application4" 5 "Application5" 6 "Application6" 7 "Application7" 8 "Application8" 9 "Application9" 10 "Application10" 11 "Application11" 12 "Application12" 13 "Application13" 14 "Application14" 15 "Application15" 16 "Application16" 17 "Application17" 18 "Application18" 19 "Application19" 20 "Application20" 21 "Application21" 22 "Application22" 23 "Application23" 24 "Application24" 25 "Application25" 26 "Application26" 27 "Application27" 28 "Application28" 29 "Application29" 30 "Application30" 31 "Application31" 32 "Application32" 33 "Application33" 34 "Application34" 35 "Application35" 36 "Application36" 37 "Application37" 38 "Application38" 39 "Application39" 40 "Application40" 41 "Application41" 42 "Application42" 43 "Application43" 44 "Application44" 45 "Application45" 46 "Application46" 47 "Application47" 48 "Application48" 49 "Application49" 50 "Application50" 51 "Application51" 52 "Application52" 53 "Application53" 54 "Application54" 55 "Application55" 56 "Application56" 57 "Application57" 58 "Application58" 59 "Application59" 60 "Application60" 61 "Application61" 62 "Application62" 63 "Driver's operation" ;
VAL_ 139 TSSBHNGH 0 "No Prohibit request" 1 "Prohibit request" ;
VAL_ 139 TSSSCOKH 0 "Prohibit" 1 "Permit" ;
VAL_ 139 TSSBHNGL 0 "No Prohibit request" 1 "Prohibit request" ;
VAL_ 139 TSSSCOKL 0 "Prohibit" 1 "Permit" ;
VAL_ 139 TSS_EPBR 0 "No request" 1 "Release" 2 "Lock" 3 "Reserved" ;
VAL_ 139 SRQEXIST 0 "Not exist" 1 "Exist" ;
VAL_ 139 TSSINV 0 "TSS function activated status" 1 "TSS function deactivated status" ;
VAL_ 139 SCMEXIST 0 "without AES" 1 "with AES" 2 "not use" 3 "Reserved" ;
VAL_ 139 ADSECOST 0 "ERM OFF" 1 "ERM ON & No Pulse Glide state" 2 "ERM ON & Glide state" 3 "ERM ON & Pulse state" ;
VAL_ 139 ESSEGON 0 "No S&S Engine Start Request" 1 "S&S Engine Start Request" ;
VAL_ 139 PCSALM 0 "OFF" 1 "ON" ;
VAL_ 139 ACCFCMF 0 "FCM ECU is not active" 1 "FCM ECU is active" ;
VAL_ 139 VGRSTRGR 0 "OFF" 1 "VGRS flag1" 2 "VGRS flag2" 3 "VGRS flag3" ;
VAL_ 139 PCSNOCHG 0 "No Request" 1 "Prohibit charge control" ;
VAL_ 139 ACCACT 0 "Not active (w/ stop hold)" 1 "Active (w/o stop hold)" ;
VAL_ 139 ACCMOFF 0 "No ACC Main SW OFF Request" 1 "ACC Main SW OFF Request" ;
VAL_ 139 PBATRGR 0 "OFF" 1 "ON(ctl_brk_1)" 2 "ON(ctl_brk_2)" 3 "Both ON" ;
VAL_ 139 AVSTRGR 0 "OFF" 1 "Full Hard" ;
VAL_ 136 ADAS_SteOnOff_D_Actl 0 "ON" 1 "OFF" 2 "OFF (Steering Hold Alert)" ;
VAL_ 136 ADAS_SteCtlActv_D_Actl 0 "Normal State" 1 "Standby" 2 "System Fail" ;
VAL_ 136 EPS_State_ADAS 0 "Normal" 1 "ADAS Control" 2 "Drv OverRide (Stay Drv Ctl)" 3 "Drv OverRide (Rtn ADAS Ctl)" ;
VAL_ 136 ADAS_SteInhbt_B_Flag 0 "Off" 1 "On" ;
VAL_ 135 SasCntComplt_B_Actl 0 "Calculating" 1 "Calculation Completed" ;
VAL_ 135 Sas_FailStatus 0 "Normal" 1 "Misassembly_Fault" 2 "Sas_Signal_Fault" 3 "Reserved" ;
VAL_ 135 SteWhlCompAnEst_D_Qf 0 "Before the absl Angle or Lost" 1 "Absl Angle Low Accuracy" 2 "Absl Angle High Accuracy" 3 "fail" ;
VAL_ 133 APPSCS 0 "NotStationalSteerAndSteerStable" 1 "StationarySteering" 2 "SteeringStabilityWithoutDriving" 3 "SteeringStability" ;
VAL_ 133 TSSVSPAU 0 "No request" 1 "Reguest" ;
VAL_ 133 TSSVSPAV 0 "invalid" 1 "valid" ;
VAL_ 133 TSSLTRSP 0 "Do not apply feedback control" 1 "Apply High gain feedback control" 2 "Apply Mid gain feedback control" 3 "Reserved" 4 "Apply Low gain feedback control" 5 "Reserved" 6 "Reserved" 7 "Reserved" ;
VAL_ 133 CSRPPMP 0 "CSR not working" 1 "CSR Pre-pump request" ;
VAL_ 133 CSRAORFG 0 "Permit accel override" 1 "Prohibit accel override" ;
VAL_ 133 CSRLMRL 0 "NotRequest" 1 "RequestOfDriveForceLimitRelease" ;
VAL_ 133 CSRRQBH 0 "No request for Brake hold" 1 "Request for Brake hold" ;
VAL_ 133 TSS_DSTR 0 "Not under operation" 1 "Under operation" ;
VAL_ 133 TSSLDRCO 0 "No Default" 1 "Mode1" 2 "Mode2" 3 "Mode3" 4 "Mode4" 5 "Mode5" 6 "Mode6" 7 "Mode7" 8 "Mode8" 9 "Mode9" 10 "Mode10" 11 "Mode11" 12 "Mode12" 13 "Mode13" 14 "Mode14" 15 "Mode15" ;
VAL_ 133 TSSLGRCH 0 "No Default" 1 "Mode1" 2 "Mode2" 3 "Mode3" 4 "Mode4" 5 "Mode5" 6 "Mode6" 7 "Mode7" 8 "Mode8" 9 "Mode9" 10 "Mode10" 11 "Mode11" 12 "Mode12" 13 "Mode13" 14 "Mode14" 15 "Mode15" ;
VAL_ 133 DEG6DOF 0 "Don't degenerate" 1 "Degenerate gradually" 2 "Degenerate instantly" 3 "Reserved" ;
VAL_ 133 TSSLTRCK 0 "No Default" 1 "Mode1" 2 "Mode2" 3 "Mode3" 4 "Mode4" 5 "Mode5" 6 "Mode6" 7 "Mode7" 8 "Mode8" 9 "Mode9" 10 "Mode10" 11 "Mode11" 12 "Mode12" 13 "Mode13" 14 "Mode14" 15 "Mode15" ;
VAL_ 133 STVIBFTV 0 "No SteeringVibrate request" 1 "SteerVibrate LDA Act" 2 "SteerVibrate LTA cancel" 3 "SteerVibrate LCA ApprochWarn" 4 "SteerVibrate BSM Warn" 5 "SteerVibrate DMS AbnormalSignSys" 6 "SteerVibrate AEB SystemWarn" 7 "SteerVibrate DMS DrowsinessAlarm" ;
VAL_ 133 TRAFAIL 0 "TRA Normal State" 1 "TRA Diagnosis Error State" ;
VAL_ 133 TSS_LTID 0 "No request" 1 "Application1" 2 "Application2" 3 "Application3" 4 "Application4" 5 "Application5" 6 "Application6" 7 "Application7" 8 "Application8" 9 "Application9" 10 "Application10" 11 "Application11" 12 "Application12" 13 "Application13" 14 "Application14" 15 "Application15" 16 "Application16" 17 "Application17" 18 "Application18" 19 "Application19" 20 "Application20" 21 "Application21" 22 "Application22" 23 "Application23" 24 "Application24" 25 "Application25" 26 "Application26" 27 "Application27" 28 "Application28" 29 "Application29" 30 "Application30" 31 "Application31" 32 "Application32" 33 "Application33" 34 "Application34" 35 "Application35" 36 "Application36" 37 "Application37" 38 "Application38" 39 "Application39" 40 "Application40" 41 "Application41" 42 "Application42" 43 "Application43" 44 "Application44" 45 "Application45" 46 "Application46" 47 "Application47" 48 "Application48" 49 "Application49" 50 "Application50" 51 "Application51" 52 "Application52" 53 "Application53" 54 "Application54" 55 "Application55" 56 "Application56" 57 "Application57" 58 "Application58" 59 "Application59" 60 "Application60" 61 "Application61" 62 "Application62" 63 "Driver's operation" ;
VAL_ 133 E_APPF 0 "Parking system nomal" 1 "Parking system fail" ;
VAL_ 133 ICSFAIL 0 "ICS system Normal" 1 "ICS system Fail" ;
VAL_ 133 CSRBRKID 0 "No request" 1 "Application1" 2 "Application2" 3 "Application3" 4 "Application4" 5 "Application5" 6 "Application6" 7 "Application7" 8 "Application8" 9 "Application9" 10 "Application10" 11 "Application11" 12 "Application12" 13 "Application13" 14 "Application14" 15 "Application15" 16 "Application16" 17 "Application17" 18 "Application18" 19 "Application19" 20 "Application20" 21 "Application21" 22 "Application22" 23 "Application23" 24 "Application24" 25 "Application25" 26 "Application26" 27 "Application27" 28 "Application28" 29 "Application29" 30 "Application30" 31 "Application31" 32 "Application32" 33 "Application33" 34 "Application34" 35 "Application35" 36 "Application36" 37 "Application37" 38 "Application38" 39 "Application39" 40 "Application40" 41 "Application41" 42 "Application42" 43 "Application43" 44 "Application44" 45 "Application45" 46 "Application46" 47 "Application47" 48 "Application48" 49 "Application49" 50 "Application50" 51 "Application51" 52 "Application52" 53 "Application53" 54 "Application54" 55 "Application55" 56 "Application56" 57 "Application57" 58 "Application58" 59 "Application59" 60 "Application60" 61 "Application61" 62 "Application62" 63 "Driver's operation" ;
VAL_ 133 RCPEXBRK 0 "without RCP" 1 "with RCP" ;
VAL_ 133 ICSSYS 0 "ICS System is invalid" 1 "ICS System is valid" ;
VAL_ 133 CSRDRVID 0 "No request" 1 "Application1" 2 "Application2" 3 "Application3" 4 "Application4" 5 "Application5" 6 "Application6" 7 "Application7" 8 "Application8" 9 "Application9" 10 "Application10" 11 "Application11" 12 "Application12" 13 "Application13" 14 "Application14" 15 "Application15" 16 "Application16" 17 "Application17" 18 "Application18" 19 "Application19" 20 "Application20" 21 "Application21" 22 "Application22" 23 "Application23" 24 "Application24" 25 "Application25" 26 "Application26" 27 "Application27" 28 "Application28" 29 "Application29" 30 "Application30" 31 "Application31" 32 "Application32" 33 "Application33" 34 "Application34" 35 "Application35" 36 "Application36" 37 "Application37" 38 "Application38" 39 "Application39" 40 "Application40" 41 "Application41" 42 "Application42" 43 "Application43" 44 "Application44" 45 "Application45" 46 "Application46" 47 "Application47" 48 "Application48" 49 "Application49" 50 "Application50" 51 "Application51" 52 "Application52" 53 "Application53" 54 "Application54" 55 "Application55" 56 "Application56" 57 "Application57" 58 "Application58" 59 "Application59" 60 "Application60" 61 "Application61" 62 "Application62" 63 "Driver's operation" ;
VAL_ 133 CSRRQSFT 0 "no request" 1 "P range request" 2 "R range request" 3 "N range request" 4 "D range request" ;
VAL_ 133 CSR_RNGR 0 "No request" 1 "Reserved" 2 "Reserved" 3 "D range" 4 "Reserved" 5 "R range" 6 "P range" 7 "N range" ;
VAL_ 133 CSRRCSFT 0 "No Request" 1 "Backward" 3 "Forward" ;
VAL_ 133 CSR_EPBR 0 "No request" 1 "Release" 2 "Lock" 3 "Reserved" ;
VAL_ 133 APPFAIL 0 "APP system Normal" 1 "APP system Fail" ;
VAL_ 133 APPSYS 0 "APP System is invalid" 1 "APP System is valid" ;
VAL_ 133 APPEXIST 0 "without APP" 1 "with APP" ;
VAL_ 133 APPMD 0 "Not control" 1 "Act control" 2 "Suspend control" 3 "Fin control" ;
VAL_ 132 SteAng_CalStart 0 "After CalculationStarted" 1 "CalcError or NotCalcStarted" ;
VAL_ 132 SteAngReltvAnSns_D_Qf 0 "Normal" 1 "Fault" 2 "Failed" 3 "Reserved" ;
VAL_ 132 SteAng_CalibStatus 0 "Not Initialization" 1 "Initialization Completed" ;
VAL_ 130 SteWhl_ChangeRateSign 0 "Left Turn" 1 "Right Turn" ;
VAL_ 130 SteWhl_CalibStatus 0 "Not Calib" 1 "Calib OK" ;
VAL_ 130 SteWhl_FailureStatus 0 "OK" 1 "Fail" ;
VAL_ 130 SteWhl_CalibRes 0 "Off" 1 "Accepted" 2 "Not Accepted" ;
VAL_ 129 VSC_YAWF 0 "Normal" 1 "Abnormal" ;
VAL_ 129 VSC_YAWS 0 "Valid" 1 "Invalid" ;
VAL_ 129 VSC_GYIV 0 "Valid" 1 "Invalid" ;
VAL_ 129 VSC_GYF 0 "Normal" 1 "Abnormal" ;
VAL_ 129 VSC_GXIV 0 "Valid" 1 "Invalid" ;
VAL_ 129 VSC_GXF 0 "Normal" 1 "Abnormal" ;
VAL_ 126 Hdc_state 0 "off" 1 "standby" 2 "active" 3 "ramp out" 4 "cooling down" 5 "disable" 6 "reserved" ;
VAL_ 126 Drive_Mode_Towing_Req_DSC 0 "NG" 1 "OK" 2 "Not Determined" 3 "Invalid" ;
VAL_ 126 Drive_Mode_OffRoad_Req_DSC 0 "NG" 1 "OK" 2 "Not Determined" 3 "Invalid" ;
VAL_ 126 Drive_Mode_Normal_Req_DSC 0 "NG" 1 "OK" 2 "Not Determined" 3 "Invalid" ;
VAL_ 126 VacRelativePres_QF 0 "Faulty" 1 "No Data Exists" 2 "Not Within Specifications" 3 "OK" ;
VAL_ 126 DYC_StatusFlag 0 "Off" 1 "On" ;
VAL_ 126 Drive_Mode_Sports_Req_DSC 0 "NG" 1 "OK" 2 "Not Determined" 3 "Invalid" ;
VAL_ 126 HlaCtl_D_Actl 0 "not configured" 1 "Hold" 2 "Release" 3 "Passive" 4 "Fail" ;
VAL_ 116 SlaCtl_D_Actl 0 "not configured" 1 "Pressurize" 2 "Hold" 3 "Release" 4 "Passive" 5 "Fail" ;
VAL_ 116 BrkMstAActl_D_Qf 0 "Faulty" 1 "No data exists" 2 "Not within specifications" 3 "OK" ;
VAL_ 80 Clutch_Cut_Switch_Status 0 "Unknown" 1 "Off" 2 "On" 3 "Invalid" ;
VAL_ 80 SKE_IR_Request 0 "Idle" 1 "IR Request" ;
VAL_ 80 SKE_SISS_Status 0 "Idle" 1 "IS Wait" 2 "IS Enable" 3 "IS Disable" 4 "IR Wait" 5 "IR Disable" 6 "IR Crank" 15 "Invalid" ;
VAL_ 80 SKE_SISS_Mode 0 "Idle" 1 "SISS mode" ;
VAL_ 80 CrankStat_B_Actl 0 "Off" 1 "On" ;
VAL_ 80 AutoP_Request 0 "Not Request" 1 "AutoP Request" 2 "Reserved" 3 "Reserved" ;
VAL_ 80 IG_OFF_Delay_State 0 "OFF" 1 "ON" ;
VAL_ 80 IG_mode 0 "Normal" 1 "Service" ;
VAL_ 80 PowerControlStatus 0 "OFF" 1 "ACC" 2 "ON" 3 "CRANK" ;
VAL_ 48 EPSACT5 0 "Other than TBG mode" 1 "Under TBG mode" ;
VAL_ 48 EPSSTS5 0 "not established" 1 "established" ;
VAL_ 48 EPSSATGF 0 "Valid" 1 "Invalid" ;
VAL_ 48 EPSAESTF 0 "Valid" 1 "Invalid" ;
VAL_ 48 EPSADACT 0 "Control off" 1 "Control off to on" 2 "Control on" 3 "Control on to off" ;
VAL_ 48 EPSSTS0 0 "Not being limited" 1 "Being limited" ;
VAL_ 48 EPSACT 0 "Not being limited" 1 "Being limited" ;
VAL_ 48 EPSFANG 0 "Normal" 1 "Abnormal" ;
VAL_ 48 STRUNSET 0 "Confirmed" 1 "NotConfirmed" ;
VAL_ 48 GRDF 0 "Not being limited" 1 "Being limited" ;
VAL_ 48 DGRDF 0 "Not being limited" 1 "Being limited" ;
VAL_ 48 EPSFC 0 "Req is executable" 1 "Req is restricted(high load)" 2 "Req is not executable (temp)" 3 "Req is not executable (fail)" ;
VAL_ 48 EPSVSPAC 0 "NotUpdated" 1 "UpdateCompleted" ;
VAL_ 48 TRQSENSF 0 "Valid" 1 "Invalid" ;
VAL_ 48 EPSF 0 "Normal" 1 "Abnormal" ;
VAL_ 48 EPSSAINV 0 "Valid" 1 "Invalid" ;
VAL_ 48 EPSTS1 0 "Normal" 1 "Abnormal" ;
VAL_ 38 SteWhl_ChangeRateSign2 0 "Left Turn" 1 "Right Turn" ;
VAL_ 38 SteWhl_CalibStatus2 0 "Not Calib" 1 "Calib OK" ;
VAL_ 38 SteWhl_FailureStatus2 0 "OK" 1 "Fail" ;
VAL_ 38 SteWhl_CalibRes2 0 "Off" 1 "Accepted" 2 "Not Accepted" ;
